VERSION ""

NS_ :

BS_:

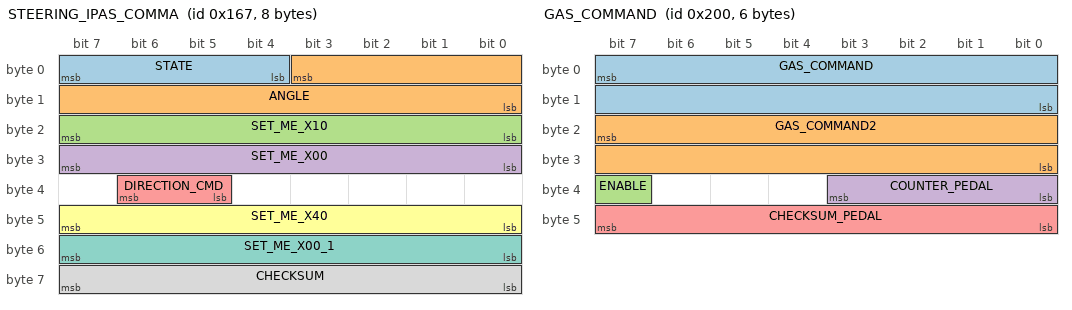
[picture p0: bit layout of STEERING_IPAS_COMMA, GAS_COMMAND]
BO_ 359 STEERING_IPAS_COMMA: 8 IPAS
 SG_ STATE : 7|4@0+ (1,0) [0|15] "" XXX
 SG_ ANGLE : 3|12@0- (1.5,0) [-510|510] "deg" XXX
 SG_ SET_ME_X10 : 23|8@0+ (1,0) [0|255] "" XXX
 SG_ SET_ME_X00 : 31|8@0+ (1,0) [0|255] "" XXX
 SG_ DIRECTION_CMD : 38|2@0+ (1,0) [0|3] "" XXX
 SG_ SET_ME_X40 : 47|8@0+ (1,0) [0|255] "" XXX
 SG_ SET_ME_X00_1 : 55|8@0+ (1,0) [0|255] "" XXX
 SG_ CHECKSUM : 63|8@0+ (1,0) [0|255] "" XXX

BO_ 512 GAS_COMMAND: 6 EON
 SG_ GAS_COMMAND : 7|16@0+ (0.159375,-75.555) [0|1] "" INTERCEPTOR
 SG_ GAS_COMMAND2 : 23|16@0+ (0.159375,-151.111) [0|1] "" INTERCEPTOR
 SG_ ENABLE : 39|1@0+ (1,0) [0|1] "" INTERCEPTOR
 SG_ COUNTER_PEDAL : 35|4@0+ (1,0) [0|15] "" INTERCEPTOR
 SG_ CHECKSUM_PEDAL : 47|8@0+ (1,0) [0|255] "" INTERCEPTOR

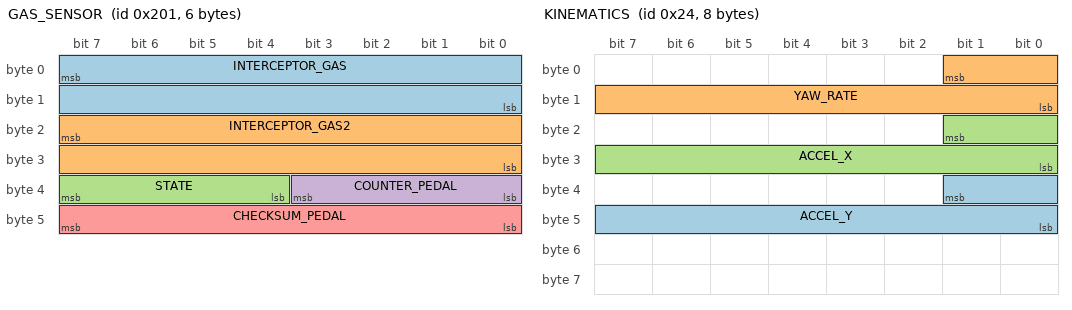
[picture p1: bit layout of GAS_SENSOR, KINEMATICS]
BO_ 513 GAS_SENSOR: 6 INTERCEPTOR
 SG_ INTERCEPTOR_GAS : 7|16@0+ (1,0) [0|1] "" EON
 SG_ INTERCEPTOR_GAS2 : 23|16@0+ (1,0) [0|1] "" EON
 SG_ STATE : 39|4@0+ (1,0) [0|15] "" EON
 SG_ COUNTER_PEDAL : 35|4@0+ (1,0) [0|15] "" EON
 SG_ CHECKSUM_PEDAL : 47|8@0+ (1,0) [0|255] "" EON

BO_ 35 SECONDARY_STEER_ANGLE: 8 XXX
 SG_ ZORRO_STEER : 7|24@0- (0.004901594652,0) [-500|500] "" XXX

BO_ 767 SDSU: 8 XXX
 SG_ FD_BUTTON : 7|1@0+ (1,0) [0|1] "" XXX

BO_ 36 KINEMATICS: 8 XXX
 SG_ ACCEL_Y : 33|10@0+ (0.03589,-18.375) [0|65535] "m/s^2" XXX
 SG_ YAW_RATE : 1|10@0+ (0.244,-125) [0|65535] "deg/s" XXX
 SG_ ACCEL_X : 17|10@0+ (0.03589,-18.375) [0|65535] "m/s^2" XXX

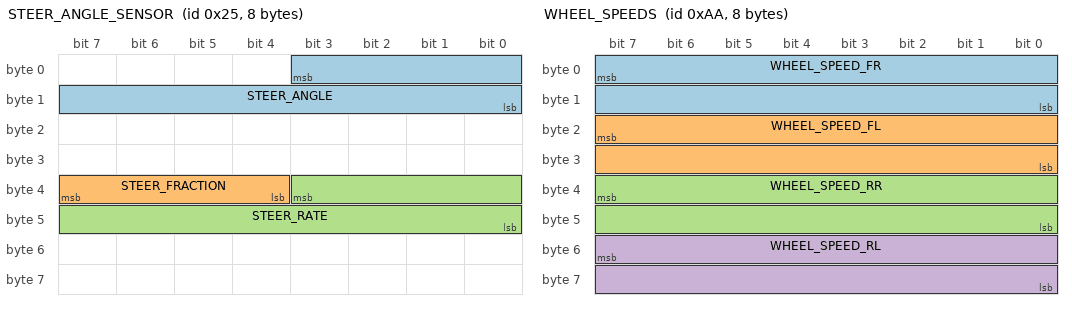
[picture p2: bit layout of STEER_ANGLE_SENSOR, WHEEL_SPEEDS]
BO_ 37 STEER_ANGLE_SENSOR: 8 XXX
 SG_ STEER_ANGLE : 3|12@0- (1.5,0) [-500|500] "deg" XXX
 SG_ STEER_FRACTION : 39|4@0- (0.1,0) [-0.7|0.7] "deg" XXX
 SG_ STEER_RATE : 35|12@0- (1,0) [-2000|2000] "deg/s" XXX

BO_ 166 BRAKE: 8 XXX
 SG_ BRAKE_AMOUNT : 7|8@0+ (1,0) [0|255] "" XXX
 SG_ BRAKE_PEDAL : 23|8@0+ (1,0) [0|255] "" XXX

BO_ 170 WHEEL_SPEEDS: 8 XXX
 SG_ WHEEL_SPEED_FR : 7|16@0+ (0.01,-67.67) [0|250] "km/h" XXX
 SG_ WHEEL_SPEED_FL : 23|16@0+ (0.01,-67.67) [0|250] "km/h" XXX
 SG_ WHEEL_SPEED_RR : 39|16@0+ (0.01,-67.67) [0|250] "km/h" XXX
 SG_ WHEEL_SPEED_RL : 55|16@0+ (0.01,-67.67) [0|250] "km/h" XXX

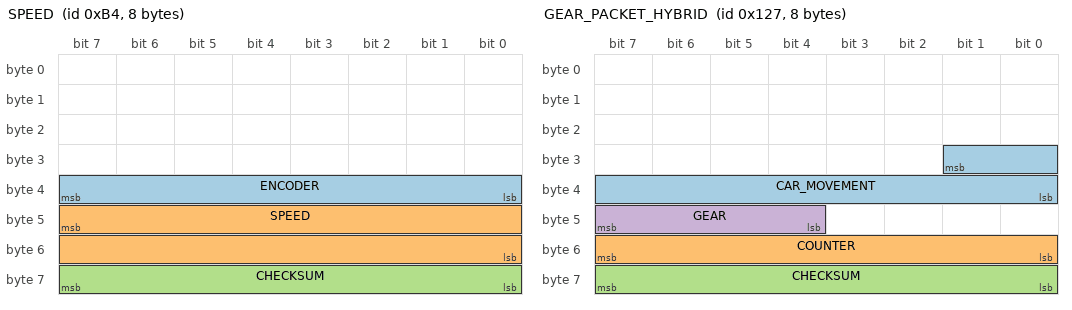
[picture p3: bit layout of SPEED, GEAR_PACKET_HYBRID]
BO_ 180 SPEED: 8 XXX
 SG_ ENCODER : 39|8@0+ (1,0) [0|255] "" XXX
 SG_ SPEED : 47|16@0+ (0.01,0) [0|250] "km/h" XXX
 SG_ CHECKSUM : 63|8@0+ (1,0) [0|255] "" XXX

BO_ 295 GEAR_PACKET_HYBRID: 8 XXX
 SG_ CAR_MOVEMENT : 25|10@0- (1,0) [0|255] "" XXX
 SG_ COUNTER : 55|8@0+ (1,0) [0|255] "" XXX
 SG_ CHECKSUM : 63|8@0+ (1,0) [0|255] "" XXX
 SG_ GEAR : 47|4@0+ (1,0) [0|15] "" XXX

BO_ 353 DSU_SPEED: 7 XXX
 SG_ FORWARD_SPEED : 15|16@0- (0.00390625,-30) [0|255] "km/h" XXX

BO_ 452 ENGINE_RPM: 8 CGW
 SG_ RPM : 7|16@0- (0.78125,0) [0|0] "rpm" SCS

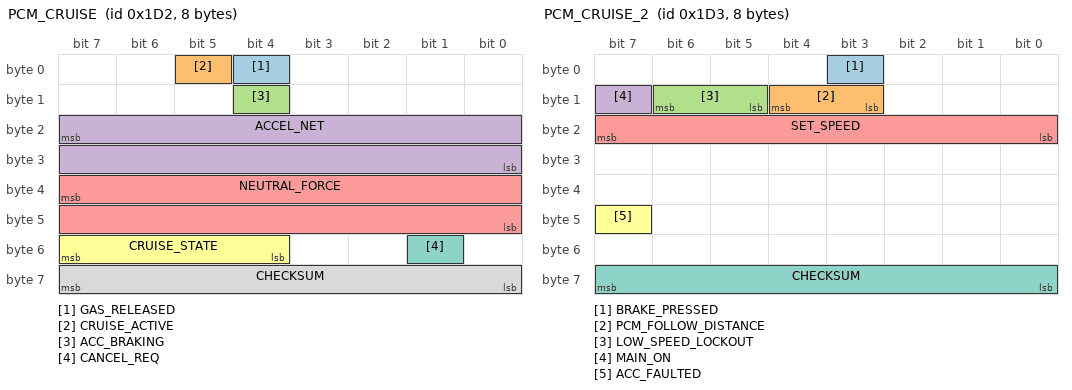
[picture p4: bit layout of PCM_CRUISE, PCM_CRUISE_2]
BO_ 466 PCM_CRUISE: 8 XXX
 SG_ GAS_RELEASED : 4|1@0+ (1,0) [0|1] "" XXX
 SG_ CRUISE_ACTIVE : 5|1@0+ (1,0) [0|1] "" XXX
 SG_ ACC_BRAKING : 12|1@0+ (1,0) [0|1] "" XXX
 SG_ ACCEL_NET : 23|16@0- (0.0009765625,0) [-20|20] "m/s^2" XXX
 SG_ NEUTRAL_FORCE : 39|16@0- (2,0) [-65536|65534] "N" XXX
 SG_ CRUISE_STATE : 55|4@0+ (1,0) [0|15] "" XXX
 SG_ CANCEL_REQ : 49|1@1+ (1,0) [0|1] "" XXX
 SG_ CHECKSUM : 63|8@0+ (1,0) [0|255] "" XXX

BO_ 467 PCM_CRUISE_2: 8 XXX
 SG_ BRAKE_PRESSED : 3|1@0+ (1,0) [0|1] "" XXX
 SG_ PCM_FOLLOW_DISTANCE : 12|2@0+ (1,0) [0|3] "" XXX
 SG_ LOW_SPEED_LOCKOUT : 14|2@0+ (1,0) [0|3] "" XXX
 SG_ MAIN_ON : 15|1@0+ (1,0) [0|1] "" XXX
 SG_ SET_SPEED : 23|8@0+ (1,0) [0|255] "km/h" XXX
 SG_ ACC_FAULTED : 47|1@0+ (1,0) [0|1] "" XXX
 SG_ CHECKSUM : 63|8@0+ (1,0) [0|255] "" XXX

BO_ 552 ACCELEROMETER: 8 XXX
 SG_ ACCEL_Z : 22|15@0- (1,0) [0|32767] "m/s^2" XXX
 SG_ ACCEL_X : 6|15@0- (0.001,0) [-20|20] "m/s^2" XXX

BO_ 560 BRAKE_2: 7 XXX
 SG_ BRAKE_PRESSED : 26|1@0+ (1,0) [0|1] "" XXX

BO_ 581 GAS_PEDAL_HYBRID: 8 XXX
 SG_ GAS_PEDAL : 23|8@0+ (0.005,0) [0|1] "" XXX

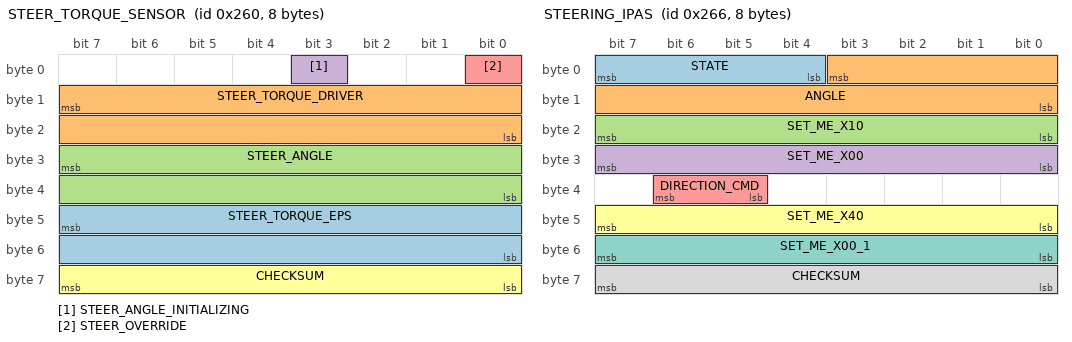
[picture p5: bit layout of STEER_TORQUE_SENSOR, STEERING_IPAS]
BO_ 608 STEER_TORQUE_SENSOR: 8 XXX
 SG_ STEER_TORQUE_EPS : 47|16@0- (1,0) [-32768|32767] "" XXX
 SG_ STEER_TORQUE_DRIVER : 15|16@0- (1,0) [-32768|32767] "" XXX
 SG_ STEER_ANGLE : 31|16@0- (0.0573,0) [-500|500] "" XXX
 SG_ STEER_ANGLE_INITIALIZING : 3|1@0+ (1,0) [0|1] "" XXX
 SG_ STEER_OVERRIDE : 0|1@0+ (1,0) [0|1] "" XXX
 SG_ CHECKSUM : 63|8@0+ (1,0) [0|255] "" XXX

BO_ 614 STEERING_IPAS: 8 IPAS
 SG_ STATE : 7|4@0+ (1,0) [0|15] "" XXX
 SG_ ANGLE : 3|12@0- (1.5,0) [-510|510] "deg" XXX
 SG_ SET_ME_X10 : 23|8@0+ (1,0) [0|255] "" XXX
 SG_ SET_ME_X00 : 31|8@0+ (1,0) [0|255] "" XXX
 SG_ DIRECTION_CMD : 38|2@0+ (1,0) [0|3] "" XXX
 SG_ SET_ME_X40 : 47|8@0+ (1,0) [0|255] "" XXX
 SG_ SET_ME_X00_1 : 55|8@0+ (1,0) [0|255] "" XXX
 SG_ CHECKSUM : 63|8@0+ (1,0) [0|255] "" XXX

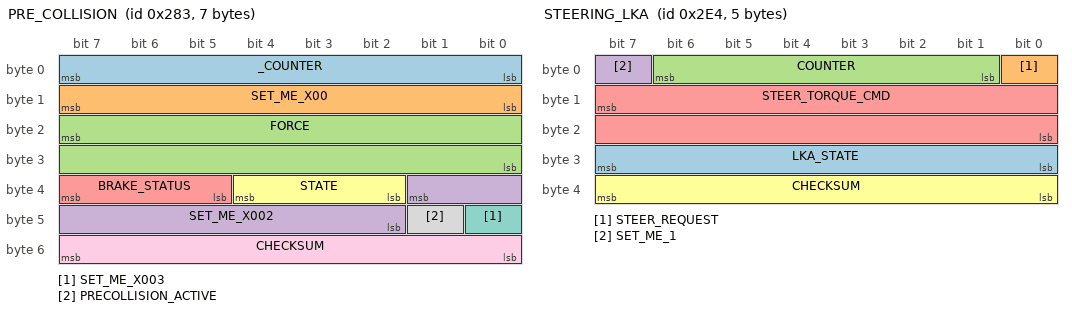
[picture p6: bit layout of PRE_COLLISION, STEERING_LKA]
BO_ 643 PRE_COLLISION: 7 DSU
 SG_ _COUNTER : 7|8@0+ (1,0) [0|255] "" XXX
 SG_ SET_ME_X00 : 15|8@0+ (1,0) [0|255] "" XXX
 SG_ FORCE : 23|16@0- (2,0) [0|255] "N" XXX
 SG_ SET_ME_X002 : 33|8@0+ (1,0) [0|3] "" XXX
 SG_ BRAKE_STATUS : 39|3@0+ (1,0) [0|255] "" XXX
 SG_ STATE : 36|3@0+ (1,0) [0|255] "" XXX
 SG_ SET_ME_X003 : 40|1@0+ (1,0) [0|1] "" XXX
 SG_ PRECOLLISION_ACTIVE : 41|1@0+ (1,0) [0|255] "" XXX
 SG_ CHECKSUM : 55|8@0+ (1,0) [0|255] "" XXX

BO_ 705 GAS_PEDAL: 8 XXX
 SG_ GAS_RELEASED : 3|1@0+ (1,0) [0|1] "" XXX
 SG_ GAS_PEDAL : 55|8@0+ (0.005,0) [0|1] "" XXX

BO_ 740 STEERING_LKA: 5 XXX
 SG_ LKA_STATE : 31|8@0+ (1,0) [0|255] "" XXX
 SG_ STEER_REQUEST : 0|1@0+ (1,0) [0|1] "" XXX
 SG_ COUNTER : 6|6@0+ (1,0) [0|63] "" XXX
 SG_ SET_ME_1 : 7|1@0+ (1,0) [0|1] "" XXX
 SG_ STEER_TORQUE_CMD : 15|16@0- (1,0) [0|65535] "" XXX
 SG_ CHECKSUM : 39|8@0+ (1,0) [0|255] "" XXX

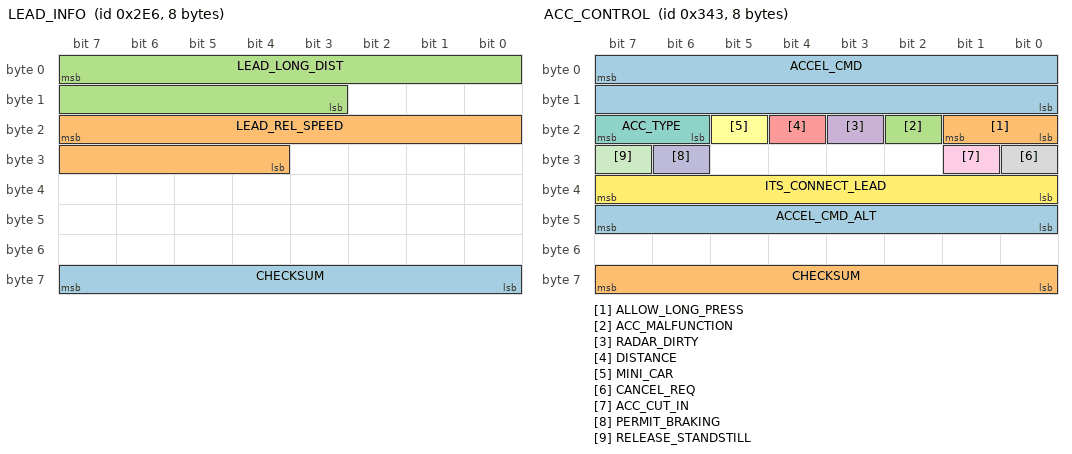
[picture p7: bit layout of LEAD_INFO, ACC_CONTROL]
BO_ 742 LEAD_INFO: 8 DSU
 SG_ CHECKSUM : 63|8@0+ (1,0) [0|255] "" HCU
 SG_ LEAD_REL_SPEED : 23|12@0- (0.025,0) [-100|100] "m/s" HCU
 SG_ LEAD_LONG_DIST : 7|13@0+ (0.05,0) [0|300] "m" HCU

BO_ 835 ACC_CONTROL: 8 DSU
 SG_ ACCEL_CMD : 7|16@0- (0.001,0) [-20|20] "m/s^2" HCU
 SG_ ALLOW_LONG_PRESS : 17|2@0+ (1,0) [0|2] "" XXX
 SG_ ACC_MALFUNCTION : 18|1@0+ (1,0) [0|0] "" XXX
 SG_ RADAR_DIRTY : 19|1@0+ (1,0) [0|1] "" XXX
 SG_ DISTANCE : 20|1@0+ (1,0) [0|1] "" XXX
 SG_ MINI_CAR : 21|1@0+ (1,0) [0|1] "" XXX
 SG_ ACC_TYPE : 23|2@0+ (1,0) [0|3] "" HCU
 SG_ CANCEL_REQ : 24|1@0+ (1,0) [0|1] "" HCU
 SG_ ACC_CUT_IN : 25|1@0+ (1,0) [0|1] "" XXX
 SG_ PERMIT_BRAKING : 30|1@0+ (1,0) [0|1] "" HCU
 SG_ RELEASE_STANDSTILL : 31|1@0+ (1,0) [0|1] "" HCU
 SG_ ITS_CONNECT_LEAD : 39|8@0+ (1,0) [0|1] "" Vector__XXX
 SG_ ACCEL_CMD_ALT : 47|8@0- (0.05,0) [0|0] "m/s^2" XXX
 SG_ CHECKSUM : 63|8@0+ (1,0) [0|255] "" XXX

BO_ 836 PRE_COLLISION_2: 8 DSU
 SG_ CHECKSUM : 63|8@0+ (1,0) [0|0] "" XXX

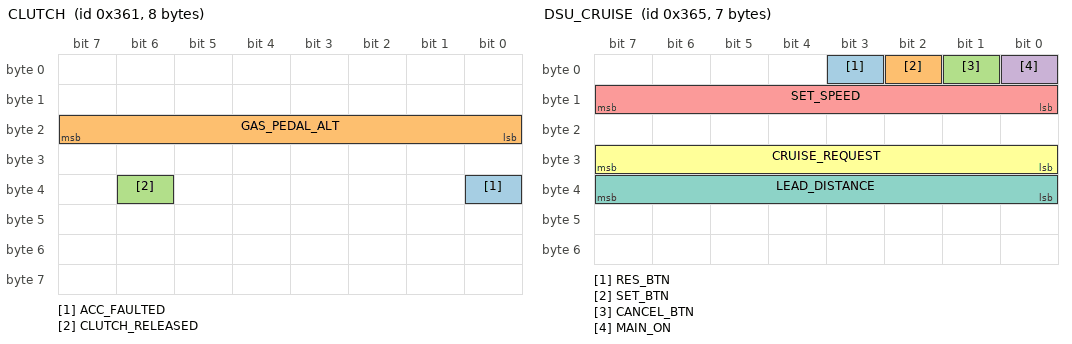
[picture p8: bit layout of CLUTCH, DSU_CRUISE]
BO_ 865 CLUTCH: 8 XXX
 SG_ ACC_FAULTED : 32|1@0+ (1,0) [0|1] "" XXX
 SG_ GAS_PEDAL_ALT : 23|8@0+ (0.005,0) [0|1] "" XXX
 SG_ CLUTCH_RELEASED : 38|1@0+ (1,0) [0|1] "" XXX

BO_ 869 DSU_CRUISE : 7 DSU
 SG_ RES_BTN : 3|1@0+ (1,0) [0|0] "" XXX
 SG_ SET_BTN : 2|1@0+ (1,0) [0|0] "" XXX
 SG_ CANCEL_BTN : 1|1@0+ (1,0) [0|0] "" XXX
 SG_ MAIN_ON : 0|1@0+ (1,0) [0|0] "" XXX
 SG_ SET_SPEED : 15|8@0+ (1,0) [0|0] "km/h" XXX
 SG_ CRUISE_REQUEST : 31|8@0+ (100,-12800) [0|0] "N" XXX
 SG_ LEAD_DISTANCE : 39|8@0+ (1,0) [0|0] "m" XXX

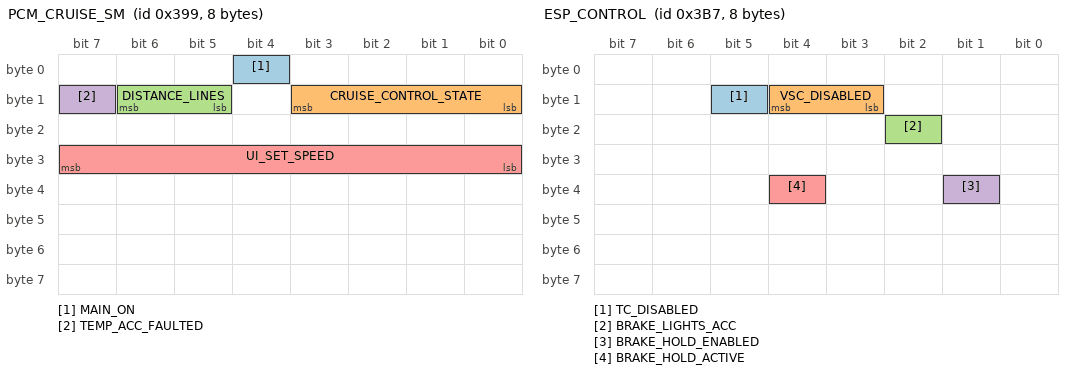
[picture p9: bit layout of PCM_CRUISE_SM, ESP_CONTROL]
BO_ 921 PCM_CRUISE_SM: 8 XXX
 SG_ MAIN_ON : 4|1@0+ (1,0) [0|1] "" XXX
 SG_ CRUISE_CONTROL_STATE : 11|4@0+ (1,0) [0|15] "" XXX
 SG_ DISTANCE_LINES : 14|2@0+ (1,0) [0|3] "" XXX
 SG_ TEMP_ACC_FAULTED : 15|1@0+ (1,0) [0|1] "" XXX
 SG_ UI_SET_SPEED : 31|8@0+ (1,0) [0|255] "" XXX

BO_ 951 ESP_CONTROL: 8 ESP
 SG_ TC_DISABLED : 13|1@0+ (1,0) [0|1] "" XXX
 SG_ VSC_DISABLED : 12|2@0+ (1,0) [0|1] "" XXX
 SG_ BRAKE_LIGHTS_ACC : 18|1@0+ (1,0) [0|1] "" XXX
 SG_ BRAKE_HOLD_ENABLED : 33|1@1+ (1,0) [0|1] "" XXX
 SG_ BRAKE_HOLD_ACTIVE : 36|1@0+ (1,0) [0|1] "" XXX

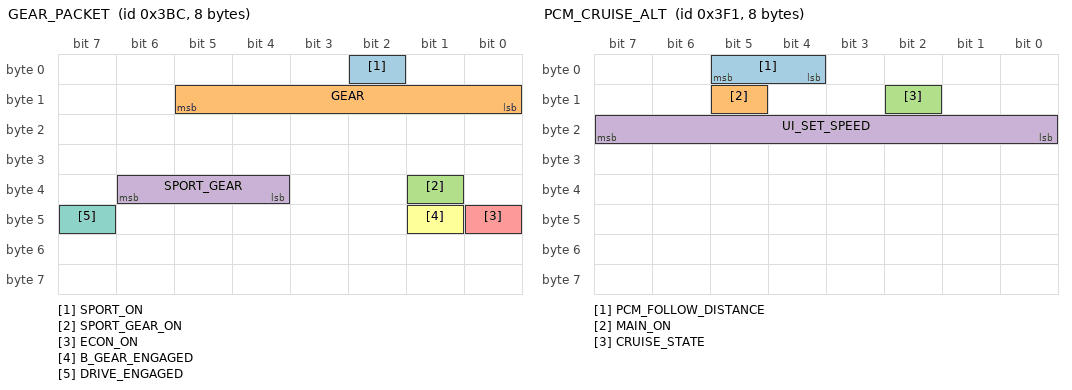
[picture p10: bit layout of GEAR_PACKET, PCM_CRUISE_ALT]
BO_ 956 GEAR_PACKET: 8 XXX
 SG_ SPORT_ON : 2|1@0+ (1,0) [0|1] "" XXX
 SG_ GEAR : 13|6@0+ (1,0) [0|63] "" XXX
 SG_ SPORT_GEAR_ON : 33|1@0+ (1,0) [0|1] "" XXX
 SG_ SPORT_GEAR : 38|3@0+ (1,0) [0|7] "" XXX
 SG_ ECON_ON : 40|1@0+ (1,0) [0|1] "" XXX
 SG_ B_GEAR_ENGAGED : 41|1@0+ (1,0) [0|1] "" XXX
 SG_ DRIVE_ENGAGED : 47|1@0+ (1,0) [0|1] "" XXX

BO_ 1005 REVERSE_CAMERA_STATE: 2 BGM
 SG_ REVERSE_CAMERA_GUIDELINES : 9|2@0+ (1,0) [1|3] "" XXX

BO_ 1009 PCM_CRUISE_ALT: 8 XXX
 SG_ PCM_FOLLOW_DISTANCE : 4|2@1+ (1,0) [0|3] "" XXX
 SG_ MAIN_ON : 13|1@0+ (1,0) [0|3] "" XXX
 SG_ CRUISE_STATE : 10|1@0+ (1,0) [0|1] "" XXX
 SG_ UI_SET_SPEED : 23|8@0+ (1,0) [0|255] "mph" XXX

BO_ 1020 SOLAR_SENSOR: 8 XXX
 SG_ LUX_SENSOR : 55|13@0+ (1,0) [0|0] "" XXX

BO_ 1041 PCS_HUD: 8 DSU
 SG_ PCS_INDICATOR : 7|2@0+ (1,0) [0|3] "" XXX
 SG_ FCW : 4|1@0+ (1,0) [0|1] "" XXX
 SG_ SET_ME_X20 : 15|8@0+ (1,0) [0|1] "" XXX
 SG_ PCS_DUST : 34|1@0+ (1,0) [0|0] "" XXX
 SG_ PCS_TEMP : 35|1@0+ (1,0) [0|0] "" XXX
 SG_ PCS_DUST2 : 41|1@0+ (1,0) [0|0] "" XXX
 SG_ PCS_TEMP2 : 42|1@0+ (1,0) [0|0] "" XXX
 SG_ SET_ME_X10 : 39|8@0+ (1,0) [0|1] "" XXX
 SG_ PCS_OFF : 40|1@0+ (1,0) [0|0] "" XXX
 SG_ FRD_ADJ : 53|3@0+ (1,0) [0|0] "" XXX
 SG_ PCS_SENSITIVITY : 55|8@0+ (1,0) [0|1] "" XXX

BO_ 1042 LKAS_HUD: 8 DSU
 SG_ BARRIERS : 1|2@0+ (1,0) [0|3] "" XXX
 SG_ RIGHT_LINE : 3|2@0+ (1,0) [0|3] "" XXX
 SG_ LEFT_LINE : 5|2@0+ (1,0) [0|3] "" XXX
 SG_ LKAS_STATUS : 7|2@0+ (1,0) [0|3] "" XXX
 SG_ LDA_ALERT : 9|2@0+ (1,0) [0|3] "" XXX
 SG_ LDW_EXIST : 10|1@0+ (1,0) [0|1] "" XXX
 SG_ TWO_BEEPS : 12|1@0+ (1,0) [0|1] "" XXX
 SG_ ADJUSTING_CAMERA : 13|1@0+ (1,0) [0|1] "" XXX
 SG_ LDA_UNAVAILABLE_QUIET : 14|1@0+ (1,0) [0|1] "" XXX
 SG_ LDA_MALFUNCTION : 15|1@0+ (1,0) [0|1] "" XXX
 SG_ LDA_UNAVAILABLE : 16|1@0+ (1,0) [0|1] "" XXX
 SG_ LDA_SENSITIVITY : 18|2@0+ (1,0) [0|3] "" XXX
 SG_ LDA_SA_TOGGLE : 20|2@0+ (1,0) [0|3] "" XXX
 SG_ LDA_MESSAGES : 23|3@0+ (1,0) [0|1] "" XXX
 SG_ LDA_ON_MESSAGE : 31|2@0+ (1,0) [0|3] "" XXX
 SG_ REPEATED_BEEPS : 32|1@0+ (1,0) [0|1] "" XXX
 SG_ LANE_SWAY_TOGGLE : 43|1@0+ (1,0) [0|1] "" XXX
 SG_ LANE_SWAY_SENSITIVITY : 45|2@0+ (1,0) [0|3] "" XXX
 SG_ TAKE_CONTROL : 46|1@0+ (1,0) [0|1] "" XXX
 SG_ LDA_FRONT_CAMERA_BLOCKED : 47|1@0+ (1,0) [0|1] "" XXX
 SG_ LANE_SWAY_BUZZER : 50|2@0+ (1,0) [0|0] "" XXX
 SG_ LANE_SWAY_FLD : 53|3@0+ (1,0) [0|7] "" XXX
 SG_ LANE_SWAY_WARNING : 55|2@0+ (1,0) [0|3] "" XXX
 SG_ SET_ME_X01 : 42|1@0+ (1,0) [0|1] "" XXX
 SG_ SET_ME_X02 : 63|8@0+ (1,0) [0|1] "" XXX

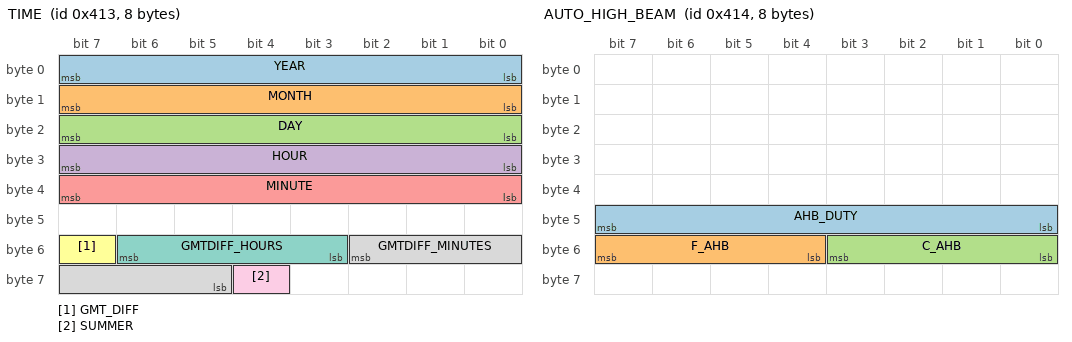
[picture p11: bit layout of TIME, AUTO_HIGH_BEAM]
BO_ 1043 TIME : 8 CGW
 SG_ YEAR : 7|8@0+ (1,0) [0|0] "year" XXX
 SG_ MONTH : 15|8@0+ (1,0) [0|0] "month" XXX
 SG_ DAY : 23|8@0+ (1,0) [0|0] "day" XXX
 SG_ HOUR : 31|8@0+ (1,0) [0|0] "hour" XXX
 SG_ MINUTE : 39|8@0+ (1,0) [0|0] "minute" XXX
 SG_ GMT_DIFF : 55|1@0+ (1,0) [0|0] "" XXX
 SG_ GMTDIFF_HOURS : 54|4@0+ (1,0) [0|0] "hours" XXX
 SG_ GMTDIFF_MINUTES : 50|6@0+ (1,0) [0|0] "minutes" XXX
 SG_ SUMMER : 60|1@0+ (1,0) [0|0] "" XXX

BO_ 1044 AUTO_HIGH_BEAM: 8 FCM
 SG_ AHB_DUTY : 47|8@0+ (0.5,0) [0|0] "%" Vector__XXX
 SG_ F_AHB : 55|4@0+ (1,0) [0|0] "" Vector__XXX
 SG_ C_AHB : 51|4@0+ (1,0) [0|0] "" Vector__XXX

BO_ 1083 AUTOPARK_STATUS: 8 IPAS
 SG_ STATE : 7|4@0+ (1,0) [0|15] "" XXX

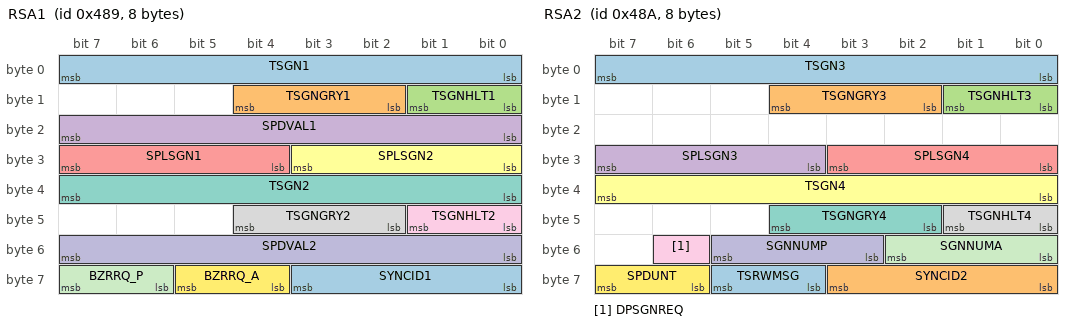
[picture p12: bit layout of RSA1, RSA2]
BO_ 1161 RSA1: 8 FCM
 SG_ TSGN1 : 7|8@0+ (1,0) [0|0] "" XXX
 SG_ TSGNGRY1 : 12|3@0+ (1,0) [0|0] "" XXX
 SG_ TSGNHLT1 : 9|2@0+ (1,0) [0|0] "" XXX
 SG_ SPDVAL1 : 23|8@0+ (1,0) [0|0] "km/h" XXX
 SG_ SPLSGN1 : 31|4@0+ (1,0) [0|0] "" XXX
 SG_ SPLSGN2 : 27|4@0+ (1,0) [0|0] "" XXX
 SG_ TSGN2 : 39|8@0+ (1,0) [0|0] "" XXX
 SG_ TSGNGRY2 : 44|3@0+ (1,0) [0|0] "" XXX
 SG_ TSGNHLT2 : 41|2@0+ (1,0) [0|0] "" XXX
 SG_ SPDVAL2 : 55|8@0+ (1,0) [0|0] "" XXX
 SG_ BZRRQ_P : 63|2@0+ (1,0) [0|0] "" XXX
 SG_ BZRRQ_A : 61|2@0+ (1,0) [0|0] "" XXX
 SG_ SYNCID1 : 59|4@0+ (1,0) [0|0] "" XXX

BO_ 1162 RSA2: 8 FCM
 SG_ TSGN3 : 7|8@0+ (1,0) [0|0] "" XXX
 SG_ TSGNGRY3 : 12|3@0+ (1,0) [0|0] "" XXX
 SG_ TSGNHLT3 : 9|2@0+ (1,0) [0|0] "" XXX
 SG_ SPLSGN3 : 31|4@0+ (1,0) [0|0] "" XXX
 SG_ SPLSGN4 : 27|4@0+ (1,0) [0|0] "" XXX
 SG_ TSGN4 : 39|8@0+ (1,0) [0|0] "" XXX
 SG_ TSGNGRY4 : 44|3@0+ (1,0) [0|0] "" XXX
 SG_ TSGNHLT4 : 41|2@0+ (1,0) [0|0] "" XXX
 SG_ DPSGNREQ : 54|1@0+ (1,0) [0|0] "" XXX
 SG_ SGNNUMP : 53|3@0+ (1,0) [0|0] "" XXX
 SG_ SGNNUMA : 50|3@0+ (1,0) [0|0] "" XXX
 SG_ SPDUNT : 63|2@0+ (1,0) [0|0] "" XXX
 SG_ TSRWMSG : 61|2@0+ (1,0) [0|0] "" XXX
 SG_ SYNCID2 : 59|4@0+ (1,0) [0|0] "" XXX

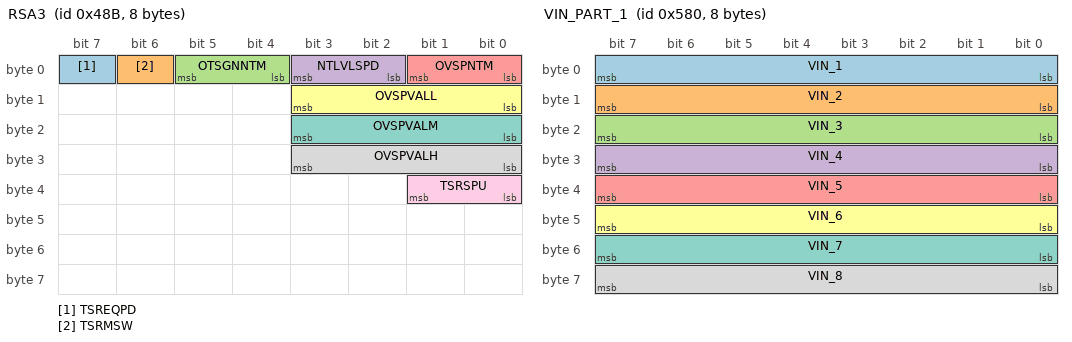
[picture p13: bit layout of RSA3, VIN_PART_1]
BO_ 1163 RSA3: 8 FCM
 SG_ TSREQPD : 7|1@0+ (1,0) [0|0] "" XXX
 SG_ TSRMSW : 6|1@0+ (1,0) [0|0] "" XXX
 SG_ OTSGNNTM : 5|2@0+ (1,0) [0|0] "" XXX
 SG_ NTLVLSPD : 3|2@0+ (1,0) [0|0] "" XXX
 SG_ OVSPNTM : 1|2@0+ (1,0) [0|0] "" XXX
 SG_ OVSPVALL : 11|4@0+ (1,-5) [0|0] "" XXX
 SG_ OVSPVALM : 19|4@0+ (1,-5) [0|0] "" XXX
 SG_ OVSPVALH : 27|4@0+ (1,-5) [0|0] "" XXX
 SG_ TSRSPU : 33|2@0+ (1,0) [0|0] "" XXX

BO_ 1408 VIN_PART_1: 8 CGW
 SG_ VIN_1 : 7|8@0+ (1,0) [0|0] "" XXX
 SG_ VIN_2 : 15|8@0+ (1,0) [0|0] "" XXX
 SG_ VIN_3 : 23|8@0+ (1,0) [0|0] "" XXX
 SG_ VIN_4 : 31|8@0+ (1,0) [0|0] "" XXX
 SG_ VIN_5 : 39|8@0+ (1,0) [0|0] "" XXX
 SG_ VIN_6 : 47|8@0+ (1,0) [0|0] "" XXX
 SG_ VIN_7 : 55|8@0+ (1,0) [0|0] "" XXX
 SG_ VIN_8 : 63|8@0+ (1,0) [0|0] "" XXX

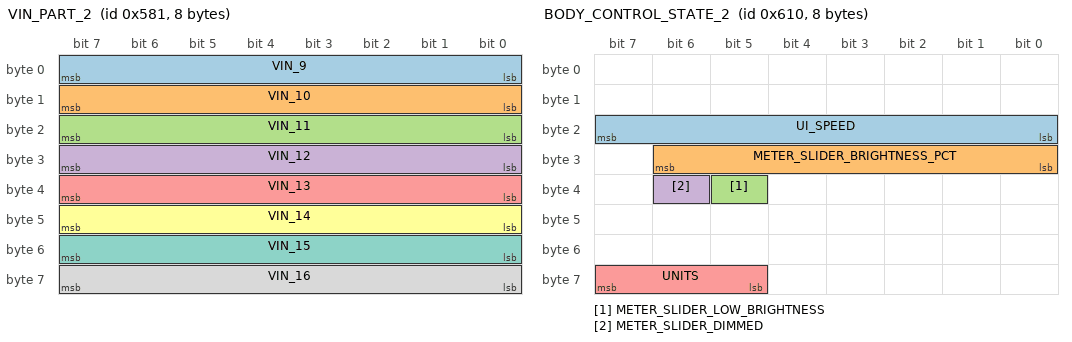
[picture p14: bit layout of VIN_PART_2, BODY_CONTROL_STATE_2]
BO_ 1409 VIN_PART_2: 8 CGW
 SG_ VIN_9 : 7|8@0+ (1,0) [0|0] "" XXX
 SG_ VIN_10 : 15|8@0+ (1,0) [0|0] "" XXX
 SG_ VIN_11 : 23|8@0+ (1,0) [0|0] "" XXX
 SG_ VIN_12 : 31|8@0+ (1,0) [0|0] "" XXX
 SG_ VIN_13 : 39|8@0+ (1,0) [0|0] "" XXX
 SG_ VIN_14 : 47|8@0+ (1,0) [0|0] "" XXX
 SG_ VIN_15 : 55|8@0+ (1,0) [0|0] "" XXX
 SG_ VIN_16 : 63|8@0+ (1,0) [0|0] "" XXX

BO_ 1410 VIN_PART_3: 8 CGW
 SG_ VIN_17 : 7|8@0+ (1,0) [0|0] "" XXX

BO_ 1552 BODY_CONTROL_STATE_2: 8 XXX
 SG_ UI_SPEED : 23|8@0+ (1,0) [0|255] "" XXX
 SG_ METER_SLIDER_BRIGHTNESS_PCT : 30|7@0+ (1,0) [12|100] "%" XXX
 SG_ METER_SLIDER_LOW_BRIGHTNESS : 37|1@0+ (1,0) [0|1] "" XXX
 SG_ METER_SLIDER_DIMMED : 38|1@0+ (1,0) [0|1] "" XXX
 SG_ UNITS : 63|3@0+ (1,0) [1|4] "" XXX

BO_ 1553 UI_SETTING: 8 XXX
 SG_ UNITS : 26|2@0+ (1,0) [0|3] "" XXX
 SG_ ODOMETER : 39|32@0+ (1,0) [0|1048575] "" XXX

BO_ 1556 BLINKERS_STATE: 8 XXX
 SG_ TURN_SIGNALS : 29|2@0+ (1,0) [0|3] "" XXX
 SG_ HAZARD_LIGHT : 27|1@0+ (1,0) [0|1] "" XXX

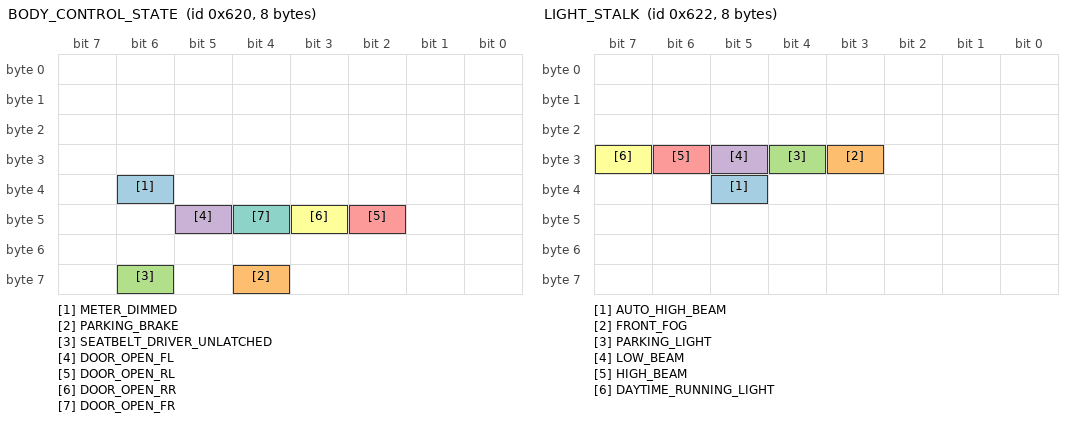
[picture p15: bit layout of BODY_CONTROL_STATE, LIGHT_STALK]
BO_ 1568 BODY_CONTROL_STATE: 8 XXX
 SG_ METER_DIMMED : 38|1@0+ (1,0) [0|1] "" XXX
 SG_ PARKING_BRAKE : 60|1@0+ (1,0) [0|1] "" XXX
 SG_ SEATBELT_DRIVER_UNLATCHED : 62|1@0+ (1,0) [0|1] "" XXX
 SG_ DOOR_OPEN_FL : 45|1@0+ (1,0) [0|1] "" XXX
 SG_ DOOR_OPEN_RL : 42|1@0+ (1,0) [0|1] "" XXX
 SG_ DOOR_OPEN_RR : 43|1@0+ (1,0) [0|1] "" XXX
 SG_ DOOR_OPEN_FR : 44|1@0+ (1,0) [0|1] "" XXX

BO_ 1570 LIGHT_STALK: 8 SCM
 SG_ AUTO_HIGH_BEAM : 37|1@0+ (1,0) [0|1] "" XXX
 SG_ FRONT_FOG : 27|1@0+ (1,0) [0|1] "" XXX
 SG_ PARKING_LIGHT : 28|1@0+ (1,0) [0|1] "" XXX
 SG_ LOW_BEAM : 29|1@0+ (1,0) [0|1] "" XXX
 SG_ HIGH_BEAM : 30|1@0+ (1,0) [0|1] "" XXX
 SG_ DAYTIME_RUNNING_LIGHT : 31|1@0+ (1,0) [0|1] "" XXX

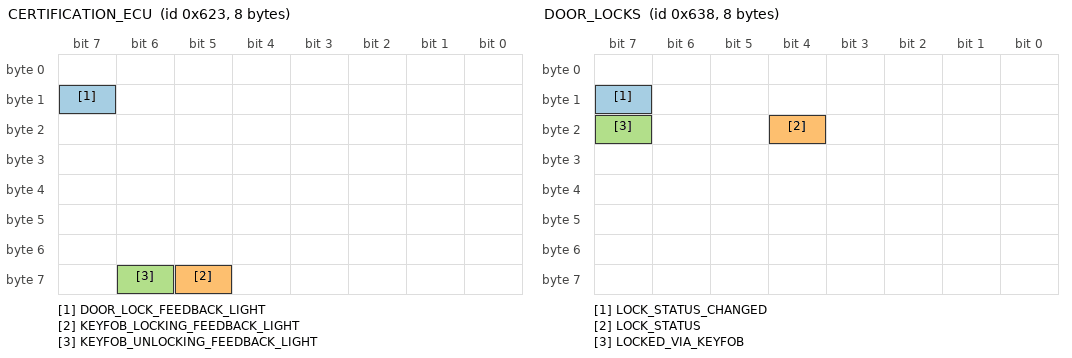
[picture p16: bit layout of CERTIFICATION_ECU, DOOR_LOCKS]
BO_ 1571 CERTIFICATION_ECU: 8 CGW
 SG_ DOOR_LOCK_FEEDBACK_LIGHT : 15|1@0+ (1,0) [0|0] "" XXX
 SG_ KEYFOB_LOCKING_FEEDBACK_LIGHT : 61|1@0+ (1,0) [0|0] "" XXX
 SG_ KEYFOB_UNLOCKING_FEEDBACK_LIGHT : 62|1@0+ (1,0) [0|0] "" XXX

BO_ 1592 DOOR_LOCKS: 8 XXX
 SG_ LOCK_STATUS_CHANGED : 15|1@0+ (1,0) [0|1] "" XXX
 SG_ LOCK_STATUS : 20|1@0+ (1,0) [0|1] "" XXX
 SG_ LOCKED_VIA_KEYFOB : 23|1@0+ (1,0) [0|1] "" XXX

BO_ 548 BRAKE_MODULE: 8 XXX
 SG_ BRAKE_PRESSURE : 43|12@0+ (1,0) [0|4047] "" XXX
 SG_ BRAKE_PRESSED : 5|1@0+ (1,0) [0|1] "" XXX

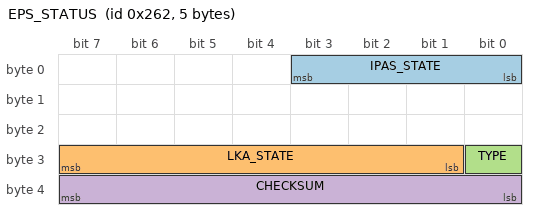
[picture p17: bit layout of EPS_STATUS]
BO_ 610 EPS_STATUS: 5 EPS
 SG_ IPAS_STATE : 3|4@0+ (1,0) [0|15] "" XXX
 SG_ LKA_STATE : 31|7@0+ (1,0) [0|127] "" XXX
 SG_ TYPE : 24|1@0+ (1,0) [0|1] "" XXX
 SG_ CHECKSUM : 39|8@0+ (1,0) [0|255] "" XXX

BO_ 1178 BRAKE_RELATED: 8 XXX
 SG_ BRAKE_PRESSED : 48|1@0+ (1,0) [0|1] "" XXX

BU_: K182_PACM K43_PSCM K17_EBCM NEO K124_ASCM

CM_ "New CAN FD network";
CM_ BU_ CMR_DSMC "Driver Status Monitor Camera";
CM_ BU_ IPMA_ADAS "Assist Driving Alert System";
CM_ BU_ PSCM "Passenger Front Climate Control Seat Module";
CM_ BU_ ABS_ESC "Anti-lock Brake / Traction Control Module";
CM_ BU_ TCCM "Transfer Case Control Module, 4x4 Control Module";
CM_ BU_ TCM_DSL "Transmission Control Module";
CM_ BU_ PCM "Powertrain Control Module";
CM_ BU_ ECM_Diesel "Diesel";
CM_ BU_ GWM "Gateway Module CGEA1.3(Star Architecture)";
CM_ BU_ TSTR "Diagnostic Tester";

CM_ SG_ 524 PrplWhlTotTqRqMxAwd_No_Cs "Signal not transmitted on gas variants.";
CM_ SG_ 524 PrplWhlTotTqRqMxAwd_No_Cnt "Signal not transmitted on gas variants.";
CM_ SG_ 1150 LocationServices_1 "Tx by HS3 APIM";
CM_ SG_ 542 LocationServices_3 "Tx by HS3 APIM";
CM_ SG_ 810 NtfyDrvTrgtDist_L_Rq "Object.SetTripRangeAlert_Rq This signal is meant to provide the customer settings for the target distance remote notification";
CM_ SG_ 810 NtfyDrvSocLvl1_Pc_Rq "Object.SetCustomerLevelAlert_Rq This signal is meant to provide the customer settings for the SOC remote notification.";
CM_ SG_ 810 PtRmtRprt_D_Stat "Object.RemoteDataReport_St";
CM_ SG_ 550 PtWakeupActv1_B_Rq "ECG Application signal";
CM_ SG_ 982 LatCtlPath_No_Cnt "Signal not transmitted on gas variants.";
CM_ SG_ 982 LatCtlPath_No_Cs "Signal not transmitted on gas variants.";
CM_ SG_ 1104 DrvEngageLevel_No_Cs "Signal not transmitted on gas variants.";
CM_ SG_ 1104 DrvEngageLevel_No_Cnt "Signal not transmitted on gas variants.";
CM_ SG_ 1085 ULoRgenTestMde_B_Stat "Signal not transmitted on HEV variants.";
CM_ SG_ 1085 PwSrcULoComm_B_Falt "Signal not transmitted on HEV variants.";
CM_ SG_ 1445 SOBDMC_AutoSarNMReserved4 "Signal not transmitted on gas and diesel variants.";
CM_ SG_ 1445 SOBDMC_AutoSarNMReserved3 "Signal not transmitted on gas and diesel variants.";
CM_ SG_ 1445 SOBDMC_AutoSarNMReserved2 "Signal not transmitted on gas and diesel variants.";
CM_ SG_ 1445 SOBDMC_AutoSarNMReserved1 "Signal not transmitted on gas and diesel variants.";
CM_ SG_ 1445 SOBDMC_AutoSarNMNodeId "Signal not transmitted on gas and diesel variants.";
CM_ SG_ 1445 SOBDMC_AutoSarNMControl "Signal not transmitted on gas and diesel variants.";
CM_ SG_ 1088 HvacPrecondMode2_D_Rq "Signal not transmitted on vehicles that do not have the Fuel operated heater feature.";
CM_ SG_ 1088 HvacPrecondBlwr2_D_Rq "Signal not transmitted on vehicles that do not have the Fuel operated heater feature.";
CM_ SG_ 786 ChrgStat_D_Dsply "Signal not transmitted by PCM_HEV";
CM_ SG_ 66 immoControlData_T2 "Not transmitted on all vehicle variants";
CM_ SG_ 66 immoControlCmd_T2 "Not transmitted on all vehicle variants";
CM_ SG_ 549 BeltminderAudioMute "Object.MyKey.BeltMinderAudioMute.St";
CM_ SG_ 549 Power_Up_Chime_Modules "Object.AlertMethod.IPC _Infotainment";
CM_ SG_ 549 Chime_Source "Object.AlertMethod.IPC_infotainment";
CM_ SG_ 611 AwdStat_D_RqDsply "Signal not transmitted on programs that do not have AWD.";
CM_ SG_ 611 AwdSrvcRqd_B_Rq "Signal not transmitted on programs that do not have AWD.";
CM_ SG_ 611 AwdLck_Tq_Rq "Signal not transmitted on programs that do not have AWD.";
CM_ SG_ 130 VehVTrlrAid_B_Rq "VR session start- req. limit blower speed no more than X volts.  CC restriction on time msg. will be honored.Double Event msg1st event to request limit, 2nd event to release limit, No msg. CC Grammar v7.xls";
CM_ SG_ 130 SteMdule_U_Meas "DCR 1745  to update Tx from GWM to EP100ms. SteMdule_I_Est & SteMdule_U_Meas are used by BMS system & filtered. The filter uses standard periodic rate & changing to EP would adversely affect the filter.(jweinfur)";
CM_ SG_ 130 SteMdule_I_Est "DCR 1745  to update Tx from GWM to EP100ms. SteMdule_I_Est & SteMdule_U_Meas are used by BMS system & filtered. The filter uses standard periodic rate & changing to EP would adversely affect the filter.(jweinfur)";
CM_ SG_ 126 StePinRelInit_An_Sns "SASM will transmit these signals on vehicles with SASM and without PSCM.  SCCM will not Tx this signal when SASM is present.";
CM_ SG_ 126 StePinAn_No_Cs "Signal not transmitted on gas variants.";
CM_ SG_ 1200 BrkTot_Tq_RqDrv "DCR 1836 to update Tx from GWM to EP100ms rejected due MPS6 TCM requires BrkTot_Tq_RqDrv at 20ms (bshu1).";
CM_ SG_ 1046 TCMode "Signal data set to 0x0 for ABS only vehicle option content";
CM_ SG_ 1046 DrvAntiLckLamp_D_Rq "update value table v8.34, not align w/GSDB, need etracker.  ABS & IPC implemented as updated.";
CM_ SG_ 1046 BpedMove_D_Actl "CCMGenSigTimeoutTime=1000";
CM_ SG_ 1044 StePinOffst_An_Est "SASM will transmit these signals on vehicles with SASM and without PSCM.  SCCM will not Tx this signal when SASM is present.";
CM_ SG_ 1044 StePinOffst_No_Cs "Signal not transmitted on gas variants.";
CM_ SG_ 534 BrkObdData_No_Actl "Signal not transmitted on gas, diesel and HEV.  Only supported on PHEV.";
CM_ SG_ 534 BrkObdIndex_No_Actl "Signal not transmitted on gas, diesel and HEV.  Only supported on PHEV.";
CM_ SG_ 534 WhlRotatRr_No_Cnt "DCR 1833 to update Tx from GWM to EP100ms. Wheel Count signals are used by complex algorithm to determine Tire Pressure by Location & can't change from 20msec. (jweinfur)";
CM_ SG_ 534 WhlRotatRl_No_Cnt "DCR 1833 to update Tx from GWM to EP100ms. Wheel Count signals are used by complex algorithm to determine Tire Pressure by Location & can't change from 20msec. (jweinfur)";
CM_ SG_ 534 WhlRotatFr_No_Cnt "DCR 1833 to update Tx from GWM to EP100ms. Wheel Count signals are used by complex algorithm to determine Tire Pressure by Location & can't change from 20msec. (jweinfur)";
CM_ SG_ 534 WhlRotatFl_No_Cnt "DCR 1833 to update Tx from GWM to EP100ms. Wheel Count signals are used by complex algorithm to determine Tire Pressure by Location & can't change from 20msec. (jweinfur)";
CM_ SG_ 531 VehLongOvrGnd_A_Est "CCMGenSigTimeoutTime=1000";
CM_ SG_ 1034 VehicleGGCCData "RCMGenSigTimeout=6000";
CM_ SG_ 1090 Mtr2State_D_ActlMntr "Signal Not transmitted on PCM_HEV variant";
CM_ SG_ 1090 Inv1Ain_I_ActlMntr "Signal Not transmitted on PCM_HEV variant";
CM_ SG_ 1090 VehElRnge_L_Dsply "Signal Not transmitted on HPCM variant";
CM_ SG_ 374 TrnRng_D_Rq "Powersplit HEVs with HF45, HPCM will Tx  this message.  For all other programs it will be Tx by PCM or TCM. ";
CM_ SG_ 374 TrnPrkSys_D_Actl "Powersplit HEVs with HF45, HPCM will Tx  this message.  For all other programs it will be Tx by PCM or TCM. ";
CM_ SG_ 374 GearLvr_D_ActlDrv "Powersplit HEVs with HF45, HPCM will Tx  this message.  For all other programs it will be Tx by PCM or TCM. ";
CM_ SG_ 374 GearPos_No_Cs "Powersplit HEVs with HF45, HPCM will Tx  this message.  For all other programs it will be Tx by PCM or TCM. ";
CM_ SG_ 374 GearPos_D_Trg "Powersplit HEVs with HF45, HPCM will Tx  this message.  For all other programs it will be Tx by PCM or TCM. ";
CM_ SG_ 374 GearPos_No_Cnt "Powersplit HEVs with HF45, HPCM will Tx  this message.  For all other programs it will be Tx by PCM or TCM. ";
CM_ SG_ 374 GearPos_D_Actl "Powersplit HEVs with HF45, HPCM will Tx  this message.  For all other programs it will be Tx by PCM or TCM. ";
CM_ SG_ 603 WhlDirAvgDrv_D_Actl "48V mHEV: ECM_HEVDSL is Tx,  MHT HEV: PCM_HEV is Tx,  Powersplit HEV: SOBDMC_HPCM is Tx";
CM_ SG_ 603 PrplTqMnRgen_B_Actl "48V mHEV: ECM_HEVDSL is Tx,  MHT HEV: PCM_HEV is Tx,  Powersplit HEV: SOBDMC_HPCM is Tx";
CM_ SG_ 603 BattTracCnnct_D_Rq "48V mHEV: ECM_HEVDSL is Tx,  MHT HEV: PCM_HEV is Tx,  Powersplit HEV: SOBDMC_HPCM is Tx";
CM_ SG_ 872 HybMdeStat_D_Dsply "Signal not transmitted by HPCM";
CM_ SG_ 560 SelDrvMdeSwtch_D_Stat3 "ECM_HEV,  PCM & PCM_HEV do not support or Transmit signal.";
CM_ SG_ 560 TrnSrvcRqd_B_Rq "Signal not transmitted on Diesel & HEV variants. MHT(U611/625) HPCM Rx 0x230 from PCM_HEV. Powersplit FWD HEVs(Cx482/3 430) HPCM Tx 0x230.";
CM_ SG_ 560 TrnShifActv_B_Actl "Signal not transmitted on HEV variants. MHT(U611/625) HPCM Rx 0x230 from PCM_HEV. Powersplit FWD HEVs(Cx482/3 430) HPCM Tx 0x230.";
CM_ SG_ 560 GboxOil_Te_Actl "Signal not transmitted on HEV variants. MHT(U611/625) HPCM Rx 0x230 from PCM_HEV. Powersplit FWD HEVs(Cx482/3 430) HPCM Tx 0x230.";
CM_ SG_ 369 SeatWorkSrfc_B_Falt "Signal Not transmitted by TCM_DSL";
CM_ SG_ 369 TrnIpcDsplyRng2_D_Actl "Signal not transmitted on HEV variants.";
CM_ SG_ 369 TrnIpcDsplyRng_D_Stat "Signal not transmitted on HEV variants.";
CM_ SG_ 92 TrnLvrV_D_Rq "Signal not transmitted on vehicles with PCM_HEV";
CM_ SG_ 92 TrnSbwSysHlth_D_Actl "Signal not transmitted on vehicles that do not have shift by wire.";
CM_ SG_ 92 TrnGearNtmAllow_B_Stat "Signal not transmitted on vehicles that do not have shift by wire.";
CM_ SG_ 92 TrnDtpCmd_D_Actl "Signal not transmitted on vehicles that do not have shift by wire.";
CM_ SG_ 92 TrnGearCmd_No_Cs "Signal not transmitted on vehicles that do not have shift by wire.";
CM_ SG_ 92 TrnValidGear_D_Cnfm "Signal not transmitted on vehicles that do not have shift by wire.";
CM_ SG_ 92 TrnNtrlTowCmd_D_Actl "Signal not transmitted on vehicles that do not have shift by wire.";
CM_ SG_ 92 TrnGearCmd_Pc_ActlPt "Signal not transmitted on vehicles that do not have shift by wire.";
CM_ SG_ 92 TrnGear_D_RqPt "Signal not transmitted on vehicles that do not have shift by wire.";
CM_ SG_ 92 TrnCmdState_B_Actl "Signal not transmitted on vehicles that do not have shift by wire.";
CM_ SG_ 92 TrnCmdCnt_B_Actl "Signal not transmitted on vehicles that do not have shift by wire.";
CM_ SG_ 92 PrkBrkActv_D_RqTrnGear "Signal not transmitted on vehicles that do not have shift by wire.";
CM_ SG_ 92 TrnGearMsgTxt_D_Rq "Signal not transmitted on vehicles that do not have shift by wire.";
CM_ SG_ 92 TrnGearCmd_No_Cnt "Signal not transmitted on vehicles that do not have shift by wire.";
CM_ SG_ 1087 BattRgenLoChrg_D_RqEng "Signal not transmitted on diesel variant";
CM_ SG_ 1087 BattRgenLoDChrg_D_RqEng "Signal not transmitted on diesel variant";
CM_ SG_ 1087 FapLcInhbt_B_Rq "Signal not transmitted on diesel variant";
CM_ SG_ 1100 EngExhMdeQuiet_D2_Stat "Signal not transmitted on HEV & Diesel programs";
CM_ SG_ 1100 HvacCmprLim_D_Stat "Signal not transmitted on Diesel variants";
CM_ SG_ 1100 WakeAlarm1_T_Rq "Signal not transmitted on Gas variants";
CM_ SG_ 1100 WakeAlarm1_B_Typ "Signal not transmitted on Gas variants";
CM_ SG_ 1100 Veh_V_DsplyTrailCtlSet "Signal not transmitted on HEV & Diesel programs";
CM_ SG_ 1100 TrailCtlPt_B_Falt "Signal not transmitted on HEV & Diesel programs";
CM_ SG_ 1100 AutoTowAllw_D_StatMnu "Signal not transmitted on Gas & Diesel variants";
CM_ SG_ 1100 AutoTowActv_B_Stat "Signal not transmitted on Gas & Diesel variants";
CM_ SG_ 1086 EngMnfld_P_Actl "Signal not transmitted on HEV & Diesel programs";
CM_ SG_ 1086 ElLoadCtl_D_Rq "Signal not transmitted on HEV variants.";
CM_ SG_ 1071 CluPdl_PcRate_Actl "Signal not transmitted on HEV and Gas variants.";
CM_ SG_ 1071 CluPdlPosPcMeas_D_Qf "Signal not transmitted on HEV and Gas variants.";
CM_ SG_ 1071 CluPdlPos_Pc_Meas "Signal not transmitted on HEV and Gas variants.";
CM_ SG_ 1071 EngAoutIdl_N_Ntrl "Signal not transmitted on HEV variants and diesel.";
CM_ SG_ 1069 SlMde_D_Stat "IPC and HUD_ADV Receve from HS3 FGW 0x42D, not HS3 0x38A, MSG DCR 506. Signal not transmitted on Gas & HEV variants";
CM_ SG_ 1069 SlMde_D_RqDsply "IPC and HUD_ADV Receve from HS3 FGW 0x42D, not HS3 0x38A, MSG DCR 506. Signal not transmitted on Gas & HEV variants";
CM_ SG_ 1069 IsaOffst_D_Stat "Signal not transmitted on Gas & HEV variants";
CM_ SG_ 1069 ObdWarmUp_B_Complt "Signal not transmitted on diesel variants.";
CM_ SG_ 1069 EngMsgTxt_D_Rq "Signal not transmitted on diesel variants.";
CM_ SG_ 1069 EngClnt_Te_ActlDiag "Signal not transmitted on gas variants.";
CM_ SG_ 1069 EngLoad_Pc_CalcDiag "Signal not transmitted on gas variants.";
CM_ SG_ 1069 ApedPos_Pc_ActlDiag "Signal not transmitted on gas variants.";
CM_ SG_ 1060 RearDiffOilTeWarn_B_Rq "Signal not transmitted on HEV & Diesel programs";
CM_ SG_ 1060 RearDiffOil_Te_Actl "Signal not transmitted on HEV & Diesel programs";
CM_ SG_ 1057 FohEng_D_Rq "Signal not transmitted on vehicles that do not have the fuel operated heater feature. Signal not transmitted on HEV programs";
CM_ SG_ 1057 EngIdlShutDown_D_Stat "Signal not transmitted on diesel variants.";
CM_ SG_ 1057 FUEL_ALCOHOL_PERCNT "signal not transmitted on diesel and HEV variants.";
CM_ SG_ 1057 TrnTotTq_Rt_Est "Signal not transmitted on gas and HEV variants.";
CM_ SG_ 1057 TrnTotLss_Tq_Est "Signal not transmitted on gas and HEV variants.";
CM_ SG_ 1057 VehVLimStat_D_Actl "Signal not transmitted on gas and HEV variants.";
CM_ SG_ 1057 VehVLimActv_B_Actl "Signal not transmitted on gas and HEV variants.";
CM_ SG_ 562 GearNtrl_No_Cs "Powersplit HEVs with HF45, HPCM will Tx  this message.  For all other programs it will be Tx by PCM or TCM. ";
CM_ SG_ 562 GearNtrl_No_Cnt "Powersplit HEVs with HF45, HPCM will Tx  this message.  For all other programs it will be Tx by PCM or TCM. ";
CM_ SG_ 516 EngAoutNActl_D_QF "Signal not transmitted on Gas & HEV variants";
CM_ SG_ 516 EngAout3_N_Actl "Signal not transmitted on gas and diesel variants.";
CM_ SG_ 516 ApedPos_Pc_ActlArb "ABSGenSigTimeoutTime=1000";
CM_ SG_ 516 ApedPosPcActl_No_Cnt "Signal not transmitted on gas and diesel variants.";
CM_ SG_ 516 ApedPosPcActl_No_Cs "Signal not transmitted on gas and diesel variants.";
CM_ SG_ 514 VehVTrlrAid_B_Avail "Signal not transmitted on HEV variants.";
CM_ SG_ 514 GearRvrse_D_Actl "Do not implement GearRvrse_D_Actl  until eTracker 8804151 is approved, 11/24/09";
CM_ SG_ 512 PrplWhlTotTqRq_No_Cs "Signal not transmitted on gas & Diesel variants.";
CM_ SG_ 512 PrplWhlTotTqRq_No_Cnt "Signal not transmitted on gas & Diesel variants.";
CM_ SG_ 512 PtDrvMde_D_Stat "Signal not transmitted on Gas & HEV variants.";
CM_ SG_ 380 EngExhBrkOnLamp_B_Rq "Signal not transmitted on Gas variants";
CM_ SG_ 380 EngExhBrkAutoLamp_B_Rq "Signal not transmitted on Gas variants";
CM_ SG_ 380 EngAout_N_MxAllw "Signal not transmitted on Gas variants";
CM_ SG_ 380 EngExhBrkMde_D_Actl "Signal not transmitted on Gas variants";
CM_ SG_ 377 HvacAirFullOut_B_Rq "Signal not transmitted on diesel variant";
CM_ SG_ 377 FuelFlw_Vl_Dsply "Signal not transmitted on diesel variants.";
CM_ SG_ 377 FuelFillInlet_B_Dsply "Signal not transmitted on diesel variants.";
CM_ SG_ 377 OdoCount "Signal not transmitted on diesel variants.";
CM_ SG_ 377 EngOilLife_Pc_Actl "Signal not transmitted on diesel variants.";
CM_ SG_ 377 FuelFilterLamp_B_Dsply "Signal not transmitted on Gas & HEV variants";
CM_ SG_ 377 AirCondRec_B_Rq "Signal not transmitted on diesel variants.";
CM_ SG_ 377 AirCondClutch_B_Stats "Signal not transmitted on diesel variants.";
CM_ SG_ 376 GasPrtc_D_RqDsply "Signal not transmitted on HEV & Diesel variants.";
CM_ SG_ 376 EngAout_Aa_Actl "Signal not transmitted on HEV variants.";
CM_ SG_ 376 AslIconDsply_D_Rq "Signal not transmitted on HEV variants.";
CM_ SG_ 376 AslChime_B_Rq "Signal not transmitted on HEV variants.";
CM_ SG_ 376 HvacHtrCore2_Te_Actl "Signal not transmitted on Gas & Diesel variants";
CM_ SG_ 376 EcssLamp_D_RqDsply "Signal not transmitted on Gas & HEV variants";
CM_ SG_ 376 AirAmb_Te_Actl "Signal not transmitted on Gas variants";
CM_ SG_ 359 PrplWhlRgenMn_Tq_Actl "Signal not transmitted on Gas & Diesel variants";
CM_ SG_ 359 ElPw_D_StatStrtStop "Signal not transmitted on HEV variants.";
CM_ SG_ 359 TrnAin_Tq_Actl "Signal not transmitted on HEV variances.";
CM_ SG_ 359 PlgActvArb_B_Actl "Only supported on PHEV programs.  PlgActvArb_B_Actl HPCM will Tx on Powersplit PHEVs,  On MHT PHEVs the PCM_HEV will Tx and HPCM will Rx.";
CM_ SG_ 359 TrnAinTq_D_Qf "Signal not transmitted on HEV variances.";
CM_ SG_ 358 StopStrtStdby_D_Indic "Signal not transmitted on HEV variants.";
CM_ SG_ 358 StopStrtIODTxt_D_Rq "Signal not transmitted on HEV variants.";
CM_ SG_ 358 StopStrtDrvMde_D_Indic "Signal not transmitted on HEV variants.";
CM_ SG_ 358 StopStrtMsgTxt_D_Rq "Signal not transmitted on HEV variants.";
CM_ SG_ 358 HiElPwInhbt_B_Stat "Signal not transmitted on HEV programs";
CM_ SG_ 358 AutoStopPtDelta_I_Est "Signal not transmitted on HEV variants. ";
CM_ SG_ 357 BpedDrvAppl_D_Actl "CCMGenSigTimeoutTime=1000";
CM_ SG_ 357 CcStat_D_Actl "ABSGenSigTimeoutTime=1000";
CM_ SG_ 357 EngAout_N_MnAllw "Signal not transmitted on Gas & Diesel variants.";
CM_ SG_ 357 AccStopMde_D_Rq "ABSGenSigTimeoutTime=1000";
CM_ SG_ 342 EngOvrhtMitgActv_D_Ind "Signal not transmitted on diesel.";
CM_ SG_ 342 EngGoutLss_Tq_Est "Signal not transmitted on gas and diesel variants.";
CM_ SG_ 342 EngOil_Te_Actl "Signal not transmitted on Gas & HEV variants. ";
CM_ SG_ 954 GenericSwtch2_No_Actl "U625 Police Wig Wag feature";
CM_ SG_ 935 SodRight_D_Stat "IPCGenSigTimeoutTime=1600";
CM_ SG_ 935 Side_Detect_R_Illum "DDMGenSigTimeoutTime=2000";
CM_ SG_ 935 SodSnsRight_D_Stat "IPCGenSigTimeoutTime=1600";
CM_ SG_ 935 SodAlrtRight_D_Stat "DDMGenSigTimeoutTime=2000";
CM_ SG_ 1112 BattTracClntPmp_D_Stat "48V mHEV: ECM_HEVDSL is Tx,  MHT HEV: PCM_HEV is Tx,  Powersplit HEV: SOBDMC_HPCM is Tx";
CM_ SG_ 1050 Outside_Air_Temp_Stat "Filtered value, i.e. same as disply for customer";
CM_ SG_ 1009 CenterStackRing_D_Actl "The Center Stack sends the CPLR a signal to turn On or Off the light Ring, This is a customer selectable preference switch";
CM_ SG_ 1009 APIM_NumberofTracks_St "Object NumberofTracks";
CM_ SG_ 1009 APIM_ActiveTrackNum_St "Object.ActiveTrackNum";
CM_ SG_ 360 GsmSrvcRqd_B_Rq "Signal not transmitted on vehicles that do not have shift by wire.";
CM_ SG_ 360 TrnGearPwmFalt_B_Actl "Signal not transmitted on vehicles that do not have shift by wire.";
CM_ SG_ 360 GearButtnStuck_B_Actl "Signal not transmitted on vehicles that do not have shift by wire.";
CM_ SG_ 90 TrnGsmNtmState_D_Actl "Signal not transmitted on vehicles that do not have shift by wire.";
CM_ SG_ 90 DrQltyDrv_D_StatGsm "Signal not transmitted on vehicles that do not have shift by wire.";
CM_ SG_ 90 TrnBtsiOvrrd_B_Stat "Signal not transmitted on vehicles that do not have shift by wire.";
CM_ SG_ 90 TrnValidGearRq_D_Stat "Signal not transmitted on vehicles that do not have shift by wire.";
CM_ SG_ 90 TrnGearRqCnt_B_Actl "Signal not transmitted on vehicles that do not have shift by wire.";
CM_ SG_ 90 TrnGearButtn_U_Actl "Signal not transmitted on vehicles that do not have shift by wire.";
CM_ SG_ 90 TrnGearButtn_B_ActlR2 "Signal not transmitted on vehicles that do not have shift by wire.";
CM_ SG_ 90 TrnGearButtn_B_ActlR1 "Signal not transmitted on vehicles that do not have shift by wire.";
CM_ SG_ 90 TrnGearButtn_B_ActlR0 "Signal not transmitted on vehicles that do not have shift by wire.";
CM_ SG_ 90 TrnGearButtn_B_ActlP2 "Signal not transmitted on vehicles that do not have shift by wire.";
CM_ SG_ 90 TrnGearButtn_B_ActlP1 "Signal not transmitted on vehicles that do not have shift by wire.";
CM_ SG_ 90 TrnGearButtn_B_ActlP0 "Signal not transmitted on vehicles that do not have shift by wire.";
CM_ SG_ 90 TrnGearButtn_B_ActlN2 "Signal not transmitted on vehicles that do not have shift by wire.";
CM_ SG_ 90 TrnGearButtn_B_ActlN1 "Signal not transmitted on vehicles that do not have shift by wire.";
CM_ SG_ 90 TrnGearButtn_B_ActlN0 "Signal not transmitted on vehicles that do not have shift by wire.";
CM_ SG_ 90 TrnGearButtn_B_ActlM2 "Signal not transmitted on vehicles that do not have shift by wire.";
CM_ SG_ 90 TrnGearButtn_B_ActlM1 "Signal not transmitted on vehicles that do not have shift by wire.";
CM_ SG_ 90 TrnGearButtn_B_ActlM0 "Signal not transmitted on vehicles that do not have shift by wire.";
CM_ SG_ 90 TrnGearButtn_B_ActlD2 "Signal not transmitted on vehicles that do not have shift by wire.";
CM_ SG_ 90 TrnGearButtn_B_ActlD1 "Signal not transmitted on vehicles that do not have shift by wire.";
CM_ SG_ 90 TrnGearButtn_B_ActlD0 "Signal not transmitted on vehicles that do not have shift by wire.";
CM_ SG_ 90 TrnGear_No_Cs "Signal not transmitted on vehicles that do not have shift by wire.";
CM_ SG_ 90 TrnGear_No_Cnt "Signal not transmitted on vehicles that do not have shift by wire.";
CM_ SG_ 90 TrnGear_D_RqDrv "Signal not transmitted on vehicles that do not have shift by wire.";
CM_ SG_ 90 BrkSwtchPos_B_ActlGsm "Signal not transmitted on vehicles that do not have shift by wire.";
CM_ SG_ 138 SteWhlRelCalib_An_Sns "Signal is not transmitted on vehicles where PSCM is transmitting the message that contains this signal. Signal data set to 0x0 for ABS only vehicle option content";
CM_ SG_ 1093 StopLamp_B_RqTrlrBrk "Signal not transmitted on all variants.";
CM_ SG_ 792 ElTrip_L_Dsply "Key cycle trip distance driven with the engine off (Trip EV Miles)";
CM_ SG_ 792 ElLongTerm_L_Dsply "Long term distance distance driven with the engine off since the last long term reset (Long Term EV Miles).";
CM_ SG_ 765 Mc_VehTimeFrmtUsrSel_St "Object.BodyInterface.Settings.VehicleTimeFormatUserSelection";
CM_ SG_ 765 Mc_VehUntTrpCoUsrSel_St "Object.VehicleSettings.Disp_Miles_Kilometers.Rq";
CM_ SG_ 765 Mc_VehUnitTempUsrSel_St "Object.VehicleSettings.Disp_Temperature.Rq";
CM_ SG_ 765 Mc_VehLangUsrSel_St "Object.BodyInterface.Settings.VehicleLanguageUserSelection Object Vehicle Settings.Disp_LangSel";
CM_ SG_ 934 Side_Detect_L_Illum "DDMGenSigTimeoutTime=2000";
CM_ SG_ 934 SodLeft_D_Stat "IPCGenSigTimeoutTime=1600";
CM_ SG_ 934 SodSnsLeft_D_Stat "IPCGenSigTimeoutTime=1600";
CM_ SG_ 934 SodAlrtLeft_D_Stat "DDMGenSigTimeoutTime=2000";
CM_ SG_ 1072 MetricActv_B_Actl "0 =Inactive(English), 1=Active(Metric)";
CM_ SG_ 145 VehYaw_W_Actl "CCMGenSigTimeoutTime=1000";
CM_ SG_ 931 CrnkInhbt_No_Cs "Signal not transmitted on gas and HEV variants.";
CM_ SG_ 931 CrnkInhbt_No_Cnt "Signal not transmitted on gas and HEV variants.";
CM_ SG_ 947 Dimming_Lvl "Refer to Vehicle Interior Illum Dimming Ctrl Sys Eng Spec, Table 2";
CM_ SG_ 947 PrkBrkActv_B_Actl "Signal not transmitted on vehicles with electric park brake. ";
CM_ SG_ 394 HaDsply_No_Cs "Signal not transmitted on gas variants.";
CM_ SG_ 394 HaDsply_No_Cnt "Signal not transmitted on gas variants.";
CM_ SG_ 391 CmbbBrkDecel_A_Rq "ABSGenSigTimeoutTime=1000";
CM_ SG_ 391 CmbbBrkPrchg_D_Rq "ABSGenSigTimeoutTime=1000";
CM_ SG_ 391 CmbbBrkDecel_B_Rq "ABSGenSigTimeoutTime=1000";
CM_ SG_ 391 CmbbBaSens_D_Rq "ABSGenSigTimeoutTime=1000";
CM_ SG_ 390 AccBrkTot_A_Rq "ABSGenSigTimeoutTime=1000";
CM_ SG_ 390 AccBrkPrkEl_B_Rq "ABSGenSigTimeoutTime=1000";
CM_ SG_ 390 AccPrpl_A_Rq "PCMGenSigTimeoutTime=1000";
CM_ SG_ 390 AccBrkPrchg_B_Rq "ABSGenSigTimeoutTime=1000";
CM_ SG_ 390 AccBrkDecel_B_Rq "ABSGenSigTimeoutTime=1000";
CM_ SG_ 390 AccStopStat_B_Rq "ABSGenSigTimeoutTime=1000";
CM_ SG_ 942 PrkAidRdiusRight_L_Dsply "MSGDCR 679, set all signals to OnChange";
CM_ SG_ 942 PrkAidRdiusLeft_L_Dsply "MSGDCR 679, set all signals to OnChange";
CM_ SG_ 942 PrkAidDrvDir_D_Stat "MSGDCR 679, set all signals to OnChange";

BA_DEF_ BO_  "OvtpPushApplication" ENUM  "FALSE","TRUE";
BA_DEF_ BU_  "OvtpOperationMode" ENUM  "SERVER","CLIENT";
BA_DEF_ BU_  "OvtpEcuAddress" INT 0 1022;
BA_DEF_ SG_  "ECGUsedRxSignal" ENUM  "No","Yes";
BA_DEF_ SG_  "ECGUsedTxSignal" ENUM  "No","Yes";
BA_DEF_ BO_  "VFrameFormat" ENUM  "StandardCAN","ExtendedCAN","reserved","reserved","reserved","reserved","reserved","reserved","reserved","reserved","reserved","reserved","reserved","reserved","StandardCAN_FD","ExtendedCAN_FD";
BA_DEF_  "BusType" STRING;
BA_DEF_ BO_  "FrameRouting" STRING;
BA_DEF_ BO_  "FrameGatewayNetwork" STRING;
BA_DEF_ BO_  "NetworkInitialization" ENUM  "No","Yes";
BA_DEF_ BO_  "FrameGatewayId" HEX 0 1407;
BA_DEF_ BO_  "EventRateOfChange" INT 10 10000;
BA_DEF_ BO_  "GenMsgStartDelayTime" INT 0 10000;
BA_DEF_ BO_  "GenMsgNrOfRepetition" INT 0 100;
BA_DEF_ BO_  "GenMsgDelayTime" INT 0 1000;
BA_DEF_ BO_  "GenMsgCycleTime" INT 0 100000;
BA_DEF_ BO_  "GenMsgSendType" ENUM  "FixedPeriodic","Event","EnabledPeriodic","NotUsed","NotUsed","EventPeriodic","NotUsed","NotUsed","NoMsgSendType";
BA_DEF_ SG_  "U_T6_MCA_MY2020_Tx" ENUM  "No","Yes";
BA_DEF_ SG_  "U_P702_MY2021_Tx" ENUM  "No","Yes";
BA_DEF_ SG_  "U_CX727_MY2021_Tx" ENUM  "No","Yes";
BA_DEF_ SG_  "U_T6_MCA_MY2020_Rx" ENUM  "No","Yes";
BA_DEF_ SG_  "U_P702_MY2021_Rx" ENUM  "No","Yes";
BA_DEF_ SG_  "U_CX727_MY2021_Rx" ENUM  "No","Yes";
BA_DEF_ SG_  "GenSigStartValue" HEX 0 268435455;
BA_DEF_ SG_  "MetaData" ENUM  "No","Yes";
BA_DEF_ SG_  "ContentDependant" ENUM  "No","Yes";
BA_DEF_ SG_  "GenSigStartValueInteger" INT 0 1000000000;
BA_DEF_ SG_  "UsedOnPgmDBC" ENUM  "No","Yes";
BA_DEF_ SG_  "CrossOver_InfoCAN" ENUM  "No","Yes";
BA_DEF_ SG_  "WakeupSignal" ENUM  "No","Yes";
BA_DEF_ SG_  "GenSigInactiveValue" INT 0 100000;
BA_DEF_ SG_  "GenSigSendType" ENUM  "Cyclic","OnWrite","vector_leerstring","OnChange","vector_leerstring","IfActive","vector_leerstring","NoSigSendType";
BA_DEF_ BO_  "SCP_FreshnessValueLength" INT 0 512;
BA_DEF_ BO_  "AuthFreshnessCounterSyncAttempt" INT 0 512;
BA_DEF_ BO_  "SCP_FreshnessValueTxLength" INT 0 512;
BA_DEF_ BO_  "SCP_AuthInfoTxLength" INT 0 512;
BA_DEF_ BO_  "ProgBWConditional" STRING;
BA_DEF_ BO_  "NmAsrMessage" ENUM  "No","Yes";
BA_DEF_ BO_  "TpApplType" STRING;
BA_DEF_ BO_  "DiagState" ENUM  "No","Yes";
BA_DEF_ BO_  "TpTxIndex" INT 0 536870911;
BA_DEF_ BO_  "DiagRequest" ENUM  "No","Yes";
BA_DEF_ BO_  "DiagResponse" ENUM  "No","Yes";
BA_DEF_ BO_  "GenMsgILSupport" ENUM  "No","Yes";
BA_DEF_ BU_  "Terminator" ENUM  "No","Yes";
BA_DEF_ BU_  "NodeWakeUpTime" INT 0 10000;
BA_DEF_ BU_  "NodeStartUpTime" INT 0 10000;
BA_DEF_ BU_  "NmAsrNodeIdentifier" HEX 128 255;
BA_DEF_ BU_  "NmAsrNode" ENUM  "No","Yes";
BA_DEF_ BU_  "PowerType" ENUM  "Switched","Latched","Sleep","vector_leerstring","vector_leerstring";
BA_DEF_ BU_  "DiagNode" ENUM  "GGDS","GDS","NONE";
BA_DEF_ BU_  "EOL_SB_Flash" ENUM  "GGDS","GDS","NONE","vector_leerstring";
BA_DEF_ BU_  "NmStationAddress" INT 0 255;
BA_DEF_ BU_  "ILUsed" ENUM  "No","Yes";
BA_DEF_ BU_  "NosPackage" ENUM  "None","I3_1","I3_2","1.0.1","RP","EuCD","Volcano","I3_3","FNOS_Autosar";
BA_DEF_ BU_  "PackageID" STRING;
BA_DEF_ BU_  "GatewayECU" ENUM  "No","Yes";
BA_DEF_  "NetworkSpeed" ENUM  "500kBits/s","125kBit/s";
BA_DEF_  "VersionNumber" INT 0 10000;
BA_DEF_  "StarNetworkGwType" ENUM  "0=NotDefined","1=HS1","2=HS2","3=HS3","4=HS4","5=HS5","6=MS1","7=HS6","8=HS7","9=MS2","10=FD1","11=FD2","12=FD3","13=FD4","14=FD5","15=FD6","16=FD7","17=FD8";
BA_DEF_  "CMDB_Version" STRING;
BA_DEF_  "NmType" STRING;
BA_DEF_  "NmAsrMessageCount" INT 128 128;
BA_DEF_  "NmAsrBaseAddress" HEX 1408 1408;
BA_DEF_  "DBName" STRING;
BA_DEF_  "VersionDay" INT 1 31;
BA_DEF_  "Manufacturer" STRING;
BA_DEF_  "VersionMonth" INT 1 12;
BA_DEF_  "VersionYear" INT 2000 3000;
BA_DEF_  "NmBaseAddress" HEX 1280 1280;
BA_DEF_  "NmMessageCount" INT 0 128;
BA_DEF_DEF_  "OvtpPushApplication" "FALSE";
BA_DEF_DEF_  "OvtpOperationMode" "SERVER";
BA_DEF_DEF_  "OvtpEcuAddress" 0;
BA_DEF_DEF_  "ECGUsedRxSignal" "No";
BA_DEF_DEF_  "ECGUsedTxSignal" "No";
BA_DEF_DEF_  "VFrameFormat" "ExtendedCAN_FD";
BA_DEF_DEF_  "BusType" "";
BA_DEF_DEF_  "FrameRouting" "NONE";
BA_DEF_DEF_  "FrameGatewayNetwork" "NONE";
BA_DEF_DEF_  "NetworkInitialization" "Yes";
BA_DEF_DEF_  "FrameGatewayId" 0;
BA_DEF_DEF_  "EventRateOfChange" 10000;
BA_DEF_DEF_  "GenMsgStartDelayTime" 0;
BA_DEF_DEF_  "GenMsgNrOfRepetition" 1;
BA_DEF_DEF_  "GenMsgDelayTime" 20;
BA_DEF_DEF_  "GenMsgCycleTime" 0;
BA_DEF_DEF_  "GenMsgSendType" "NoMsgSendType";
BA_DEF_DEF_  "U_T6_MCA_MY2020_Tx" "No";
BA_DEF_DEF_  "U_P702_MY2021_Tx" "No";
BA_DEF_DEF_  "U_CX727_MY2021_Tx" "No";
BA_DEF_DEF_  "U_T6_MCA_MY2020_Rx" "No";
BA_DEF_DEF_  "U_P702_MY2021_Rx" "No";
BA_DEF_DEF_  "U_CX727_MY2021_Rx" "No";
BA_DEF_DEF_  "GenSigStartValue" 0;
BA_DEF_DEF_  "MetaData" "No";
BA_DEF_DEF_  "ContentDependant" "No";
BA_DEF_DEF_  "GenSigStartValueInteger" 0;
BA_DEF_DEF_  "UsedOnPgmDBC" "Yes";
BA_DEF_DEF_  "CrossOver_InfoCAN" "No";
BA_DEF_DEF_  "WakeupSignal" "No";
BA_DEF_DEF_  "GenSigInactiveValue" 0;
BA_DEF_DEF_  "GenSigSendType" "NoSigSendType";
BA_DEF_DEF_  "SCP_FreshnessValueLength" 64;
BA_DEF_DEF_  "AuthFreshnessCounterSyncAttempt" 2;
BA_DEF_DEF_  "SCP_FreshnessValueTxLength" 8;
BA_DEF_DEF_  "SCP_AuthInfoTxLength" 56;
BA_DEF_DEF_  "ProgBWConditional" "NONE";
BA_DEF_DEF_  "NmAsrMessage" "No";
BA_DEF_DEF_  "TpApplType" "";
BA_DEF_DEF_  "DiagState" "No";
BA_DEF_DEF_  "TpTxIndex" 0;
BA_DEF_DEF_  "DiagRequest" "No";
BA_DEF_DEF_  "DiagResponse" "No";
BA_DEF_DEF_  "GenMsgILSupport" "Yes";
BA_DEF_DEF_  "Terminator" "No";
BA_DEF_DEF_  "NodeWakeUpTime" 10;
BA_DEF_DEF_  "NodeStartUpTime" 250;
BA_DEF_DEF_  "NmAsrNodeIdentifier" 128;
BA_DEF_DEF_  "NmAsrNode" "No";
BA_DEF_DEF_  "PowerType" "Switched";
BA_DEF_DEF_  "DiagNode" "GGDS";
BA_DEF_DEF_  "EOL_SB_Flash" "GGDS";
BA_DEF_DEF_  "NmStationAddress" 0;
BA_DEF_DEF_  "ILUsed" "Yes";
BA_DEF_DEF_  "NosPackage" "I3_3";
BA_DEF_DEF_  "PackageID" "08.05.00.00.71.xx.xx.rr.00.00";
BA_DEF_DEF_  "GatewayECU" "No";
BA_DEF_DEF_  "NetworkSpeed" "500kBits/s";
BA_DEF_DEF_  "VersionNumber" 1;
BA_DEF_DEF_  "StarNetworkGwType" "0=NotDefined";
BA_DEF_DEF_  "CMDB_Version" "v11.01";
BA_DEF_DEF_  "NmType" "Ford-OSEK";
BA_DEF_DEF_  "NmAsrMessageCount" 128;
BA_DEF_DEF_  "NmAsrBaseAddress" 1408;
BA_DEF_DEF_  "DBName" "";
BA_DEF_DEF_  "VersionDay" 1;
BA_DEF_DEF_  "Manufacturer" "Ford";
BA_DEF_DEF_  "VersionMonth" 1;
BA_DEF_DEF_  "VersionYear" 2011;
BA_DEF_DEF_  "NmBaseAddress" 1280;
BA_DEF_DEF_  "NmMessageCount" 128;
BA_ "BusType" "CAN FD";
BA_ "VersionYear" 2019;
BA_ "VersionMonth" 4;
BA_ "VersionDay" 11;
BA_ "CMDB_Version" "FNV2_v18.07";
BA_ "StarNetworkGwType" 10;
BA_ "VersionNumber" 6;
BA_ "DBName" "FD1_CAN";
BA_ "NmStationAddress" BU_ VDM 48;
BA_ "OvtpEcuAddress" BU_ VDM 32;
BA_ "OvtpEcuAddress" BU_ CMR_DSMC 187;
BA_ "NmStationAddress" BU_ CMR_DSMC 95;
BA_ "PowerType" BU_ CMR_DSMC 2;
BA_ "NmAsrNode" BU_ CMR_DSMC 1;
BA_ "NmAsrNodeIdentifier" BU_ CMR_DSMC 223;
BA_ "OvtpEcuAddress" BU_ SOBDMC_HPCM_FD1 17;
BA_ "NmStationAddress" BU_ SOBDMC_HPCM_FD1 37;
BA_ "OvtpEcuAddress" BU_ IPMA_ADAS 33;
BA_ "NmStationAddress" BU_ IPMA_ADAS 28;
BA_ "NodeStartUpTime" BU_ IPMA_ADAS 300;
BA_ "OvtpEcuAddress" BU_ PSCM 48;
BA_ "NmStationAddress" BU_ PSCM 53;
BA_ "PowerType" BU_ PSCM 1;
BA_ "NmAsrNode" BU_ PSCM 1;
BA_ "NmAsrNodeIdentifier" BU_ PSCM 181;
BA_ "Terminator" BU_ PSCM 1;
BA_ "OvtpEcuAddress" BU_ ABS_ESC 40;
BA_ "NmStationAddress" BU_ ABS_ESC 22;
BA_ "PowerType" BU_ ABS_ESC 2;
BA_ "NmAsrNode" BU_ ABS_ESC 1;
BA_ "NmAsrNodeIdentifier" BU_ ABS_ESC 150;
BA_ "NodeStartUpTime" BU_ ABS_ESC 1000;
BA_ "NodeWakeUpTime" BU_ ABS_ESC 300;
BA_ "OvtpEcuAddress" BU_ TCCM 25;
BA_ "NmStationAddress" BU_ TCCM 33;
BA_ "NmAsrNode" BU_ TCCM 1;
BA_ "NmAsrNodeIdentifier" BU_ TCCM 161;
BA_ "NodeStartUpTime" BU_ TCCM 1000;
BA_ "NodeWakeUpTime" BU_ TCCM 25;
BA_ "OvtpEcuAddress" BU_ TCM_DSL 24;
BA_ "NmStationAddress" BU_ TCM_DSL 32;
BA_ "PowerType" BU_ TCM_DSL 1;
BA_ "NmAsrNode" BU_ TCM_DSL 1;
BA_ "NmAsrNodeIdentifier" BU_ TCM_DSL 160;
BA_ "NodeWakeUpTime" BU_ TCM_DSL 200;
BA_ "NosPackage" BU_ TCM_DSL 4;
BA_ "OvtpEcuAddress" BU_ PCM_HEV 16;
BA_ "NmStationAddress" BU_ PCM_HEV 21;
BA_ "PowerType" BU_ PCM_HEV 1;
BA_ "NmAsrNode" BU_ PCM_HEV 1;
BA_ "NmAsrNodeIdentifier" BU_ PCM_HEV 149;
BA_ "NodeStartUpTime" BU_ PCM_HEV 350;
BA_ "OvtpEcuAddress" BU_ PCM 16;
BA_ "NmStationAddress" BU_ PCM 21;
BA_ "PowerType" BU_ PCM 1;
BA_ "NmAsrNode" BU_ PCM 1;
BA_ "NmAsrNodeIdentifier" BU_ PCM 149;
BA_ "NodeStartUpTime" BU_ PCM 350;
BA_ "OvtpEcuAddress" BU_ ECM_Diesel 16;
BA_ "NmStationAddress" BU_ ECM_Diesel 21;
BA_ "PowerType" BU_ ECM_Diesel 1;
BA_ "NmAsrNode" BU_ ECM_Diesel 1;
BA_ "NmAsrNodeIdentifier" BU_ ECM_Diesel 149;
BA_ "OvtpEcuAddress" BU_ GWM 216;
BA_ "OvtpOperationMode" BU_ GWM 1;
BA_ "NmStationAddress" BU_ GWM 30;
BA_ "PowerType" BU_ GWM 2;
BA_ "NmAsrNode" BU_ GWM 1;
BA_ "NmAsrNodeIdentifier" BU_ GWM 158;
BA_ "NodeStartUpTime" BU_ GWM 100;
BA_ "Terminator" BU_ GWM 1;
BA_ "GatewayECU" BU_ GWM 1;
BA_ "NosPackage" BU_ GWM 4;
BA_ "GenMsgSendType" BO_ 823 5;
BA_ "GenMsgCycleTime" BO_ 823 1000;
BA_ "VFrameFormat" BO_ 823 14;
BA_ "GenMsgSendType" BO_ 824 5;
BA_ "GenMsgCycleTime" BO_ 824 1000;
BA_ "VFrameFormat" BO_ 824 14;
BA_ "FrameGatewayId" BO_ 949 949;
BA_ "FrameGatewayNetwork" BO_ 949 "HS1_CAN";
BA_ "FrameRouting" BO_ 949 "";
BA_ "VFrameFormat" BO_ 949 14;
BA_ "GenMsgILSupport" BO_ 1825 0;
BA_ "DiagRequest" BO_ 1825 1;
BA_ "GenMsgSendType" BO_ 1825 1;
BA_ "GenMsgDelayTime" BO_ 1825 0;
BA_ "NetworkInitialization" BO_ 1825 0;
BA_ "VFrameFormat" BO_ 1825 14;
BA_ "GenMsgDelayTime" BO_ 524 0;
BA_ "GenMsgCycleTime" BO_ 524 10;
BA_ "GenMsgSendType" BO_ 524 0;
BA_ "ProgBWConditional" BO_ 524 "MSGDCR1008_CX48X_V03_HS1D_56.84_mHEV_54.89";
BA_ "VFrameFormat" BO_ 524 14;
BA_ "FrameRouting" BO_ 740 "";
BA_ "FrameGatewayNetwork" BO_ 740 "HS1_CAN";
BA_ "FrameGatewayId" BO_ 740 740;
BA_ "VFrameFormat" BO_ 740 14;
BA_ "GenMsgCycleTime" BO_ 1160 1000;
BA_ "GenMsgSendType" BO_ 1160 5;
BA_ "VFrameFormat" BO_ 1160 14;
BA_ "GenMsgCycleTime" BO_ 776 1000;
BA_ "GenMsgSendType" BO_ 776 5;
BA_ "VFrameFormat" BO_ 776 14;
BA_ "GenMsgCycleTime" BO_ 775 1000;
BA_ "GenMsgSendType" BO_ 775 5;
BA_ "VFrameFormat" BO_ 775 14;
BA_ "GenMsgCycleTime" BO_ 774 1000;
BA_ "GenMsgSendType" BO_ 774 5;
BA_ "VFrameFormat" BO_ 774 14;
BA_ "FrameGatewayId" BO_ 811 811;
BA_ "FrameGatewayNetwork" BO_ 811 "HS3_CAN";
BA_ "FrameRouting" BO_ 811 "";
BA_ "VFrameFormat" BO_ 811 14;
BA_ "GenMsgSendType" BO_ 850 0;
BA_ "GenMsgCycleTime" BO_ 850 150;
BA_ "VFrameFormat" BO_ 850 14;
BA_ "GenMsgCycleTime" BO_ 563 1000;
BA_ "GenMsgSendType" BO_ 563 5;
BA_ "VFrameFormat" BO_ 563 14;
BA_ "GenMsgILSupport" BO_ 1833 0;
BA_ "DiagResponse" BO_ 1833 1;
BA_ "GenMsgSendType" BO_ 1833 1;
BA_ "GenMsgDelayTime" BO_ 1833 0;
BA_ "NetworkInitialization" BO_ 1833 0;
BA_ "VFrameFormat" BO_ 1833 14;
BA_ "FrameRouting" BO_ 570 "";
BA_ "GenMsgSendType" BO_ 570 0;
BA_ "GenMsgCycleTime" BO_ 570 20;
BA_ "GenMsgDelayTime" BO_ 570 10;
BA_ "VFrameFormat" BO_ 570 14;
BA_ "FrameRouting" BO_ 837 "";
BA_ "GenMsgSendType" BO_ 837 5;
BA_ "GenMsgCycleTime" BO_ 837 1000;
BA_ "VFrameFormat" BO_ 837 14;
BA_ "FrameRouting" BO_ 885 "";
BA_ "GenMsgSendType" BO_ 885 0;
BA_ "GenMsgCycleTime" BO_ 885 200;
BA_ "VFrameFormat" BO_ 885 14;
BA_ "FrameRouting" BO_ 1150 "";
BA_ "FrameGatewayNetwork" BO_ 1150 "HS3_CAN";
BA_ "FrameGatewayId" BO_ 1150 1118;
BA_ "VFrameFormat" BO_ 1150 14;
BA_ "FrameRouting" BO_ 542 "";
BA_ "FrameGatewayNetwork" BO_ 542 "HS4_CAN";
BA_ "FrameGatewayId" BO_ 542 542;
BA_ "VFrameFormat" BO_ 542 14;
BA_ "FrameRouting" BO_ 2612224016 "";
BA_ "TpTxIndex" BO_ 2612224016 464535768;
BA_ "GenMsgSendType" BO_ 2612224016 1;
BA_ "GenMsgDelayTime" BO_ 2612224016 0;
BA_ "NetworkInitialization" BO_ 2612224016 0;
BA_ "OvtpPushApplication" BO_ 2612224016 1;
BA_ "FrameRouting" BO_ 810 "";
BA_ "GenMsgCycleTime" BO_ 810 1000;
BA_ "GenMsgSendType" BO_ 810 5;
BA_ "VFrameFormat" BO_ 810 14;
BA_ "FrameRouting" BO_ 550 "";
BA_ "GenMsgCycleTime" BO_ 550 1000;
BA_ "GenMsgSendType" BO_ 550 5;
BA_ "VFrameFormat" BO_ 550 14;
BA_ "FrameRouting" BO_ 639 "";
BA_ "GenMsgCycleTime" BO_ 639 1000;
BA_ "GenMsgSendType" BO_ 639 5;
BA_ "VFrameFormat" BO_ 639 14;
BA_ "FrameRouting" BO_ 530 "";
BA_ "GenMsgCycleTime" BO_ 530 1000;
BA_ "GenMsgSendType" BO_ 530 5;
BA_ "VFrameFormat" BO_ 530 14;
BA_ "FrameRouting" BO_ 1142 "";
BA_ "GenMsgSendType" BO_ 1142 0;
BA_ "GenMsgCycleTime" BO_ 1142 500;
BA_ "VFrameFormat" BO_ 1142 14;
BA_ "FrameRouting" BO_ 817 "";
BA_ "FrameGatewayId" BO_ 817 817;
BA_ "FrameGatewayNetwork" BO_ 817 "HS1_CAN";
BA_ "VFrameFormat" BO_ 817 14;
BA_ "FrameRouting" BO_ 879 "";
BA_ "FrameGatewayNetwork" BO_ 879 "HS1_CAN";
BA_ "FrameGatewayId" BO_ 879 879;
BA_ "VFrameFormat" BO_ 879 14;
BA_ "FrameRouting" BO_ 878 "";
BA_ "GenMsgSendType" BO_ 878 5;
BA_ "GenMsgCycleTime" BO_ 878 1000;
BA_ "VFrameFormat" BO_ 878 14;
BA_ "FrameRouting" BO_ 395 "";
BA_ "FrameGatewayNetwork" BO_ 395 "HS3_CAN";
BA_ "FrameGatewayId" BO_ 395 395;
BA_ "VFrameFormat" BO_ 395 14;
BA_ "TpTxIndex" BO_ 2611055832 463572184;
BA_ "FrameRouting" BO_ 2611055832 "";
BA_ "NetworkInitialization" BO_ 2611055832 0;
BA_ "GenMsgDelayTime" BO_ 2611055832 0;
BA_ "GenMsgSendType" BO_ 2611055832 1;
BA_ "TpTxIndex" BO_ 2611054808 463571160;
BA_ "FrameRouting" BO_ 2611054808 "";
BA_ "NetworkInitialization" BO_ 2611054808 0;
BA_ "GenMsgDelayTime" BO_ 2611054808 0;
BA_ "GenMsgSendType" BO_ 2611054808 1;
BA_ "TpTxIndex" BO_ 2611026136 463542488;
BA_ "FrameRouting" BO_ 2611026136 "";
BA_ "NetworkInitialization" BO_ 2611026136 0;
BA_ "GenMsgDelayTime" BO_ 2611026136 0;
BA_ "GenMsgSendType" BO_ 2611026136 1;
BA_ "TpTxIndex" BO_ 2611025112 463541464;
BA_ "FrameRouting" BO_ 2611025112 "";
BA_ "NetworkInitialization" BO_ 2611025112 0;
BA_ "GenMsgDelayTime" BO_ 2611025112 0;
BA_ "GenMsgSendType" BO_ 2611025112 1;
BA_ "TpTxIndex" BO_ 2610975960 463492312;
BA_ "FrameRouting" BO_ 2610975960 "";
BA_ "NetworkInitialization" BO_ 2610975960 0;
BA_ "GenMsgDelayTime" BO_ 2610975960 0;
BA_ "GenMsgSendType" BO_ 2610975960 1;
BA_ "FrameRouting" BO_ 2610007256 "";
BA_ "NetworkInitialization" BO_ 2610007256 0;
BA_ "GenMsgDelayTime" BO_ 2610007256 0;
BA_ "GenMsgSendType" BO_ 2610007256 1;
BA_ "TpTxIndex" BO_ 2610007256 462523608;
BA_ "FrameRouting" BO_ 2610006232 "";
BA_ "NetworkInitialization" BO_ 2610006232 0;
BA_ "GenMsgDelayTime" BO_ 2610006232 0;
BA_ "GenMsgSendType" BO_ 2610006232 1;
BA_ "TpTxIndex" BO_ 2610006232 462522584;
BA_ "FrameRouting" BO_ 2609977560 "";
BA_ "NetworkInitialization" BO_ 2609977560 0;
BA_ "GenMsgDelayTime" BO_ 2609977560 0;
BA_ "GenMsgSendType" BO_ 2609977560 1;
BA_ "TpTxIndex" BO_ 2609977560 462493912;
BA_ "FrameRouting" BO_ 2609976536 "";
BA_ "NetworkInitialization" BO_ 2609976536 0;
BA_ "GenMsgDelayTime" BO_ 2609976536 0;
BA_ "GenMsgSendType" BO_ 2609976536 1;
BA_ "TpTxIndex" BO_ 2609976536 462492888;
BA_ "FrameRouting" BO_ 2609927384 "";
BA_ "NetworkInitialization" BO_ 2609927384 0;
BA_ "GenMsgDelayTime" BO_ 2609927384 0;
BA_ "GenMsgSendType" BO_ 2609927384 1;
BA_ "TpTxIndex" BO_ 2609927384 462443736;
BA_ "TpTxIndex" BO_ 2611175523 463572184;
BA_ "FrameRouting" BO_ 2611175523 "";
BA_ "NetworkInitialization" BO_ 2611175523 0;
BA_ "GenMsgDelayTime" BO_ 2611175523 0;
BA_ "GenMsgSendType" BO_ 2611175523 1;
BA_ "TpTxIndex" BO_ 2612224099 464620760;
BA_ "OvtpPushApplication" BO_ 2612224099 1;
BA_ "FrameRouting" BO_ 2612224099 "";
BA_ "NetworkInitialization" BO_ 2612224099 0;
BA_ "GenMsgDelayTime" BO_ 2612224099 0;
BA_ "GenMsgSendType" BO_ 2612224099 1;
BA_ "TpTxIndex" BO_ 2611175522 463571160;
BA_ "FrameRouting" BO_ 2611175522 "";
BA_ "NetworkInitialization" BO_ 2611175522 0;
BA_ "GenMsgDelayTime" BO_ 2611175522 0;
BA_ "GenMsgSendType" BO_ 2611175522 1;
BA_ "TpTxIndex" BO_ 2612224098 464619736;
BA_ "OvtpPushApplication" BO_ 2612224098 1;
BA_ "FrameRouting" BO_ 2612224098 "";
BA_ "NetworkInitialization" BO_ 2612224098 0;
BA_ "GenMsgDelayTime" BO_ 2612224098 0;
BA_ "GenMsgSendType" BO_ 2612224098 1;
BA_ "TpTxIndex" BO_ 2611175494 463542488;
BA_ "FrameRouting" BO_ 2611175494 "";
BA_ "NetworkInitialization" BO_ 2611175494 0;
BA_ "GenMsgDelayTime" BO_ 2611175494 0;
BA_ "GenMsgSendType" BO_ 2611175494 1;
BA_ "TpTxIndex" BO_ 2612224070 464591064;
BA_ "OvtpPushApplication" BO_ 2612224070 1;
BA_ "FrameRouting" BO_ 2612224070 "";
BA_ "NetworkInitialization" BO_ 2612224070 0;
BA_ "GenMsgDelayTime" BO_ 2612224070 0;
BA_ "GenMsgSendType" BO_ 2612224070 1;
BA_ "TpTxIndex" BO_ 2611175493 463541464;
BA_ "FrameRouting" BO_ 2611175493 "";
BA_ "NetworkInitialization" BO_ 2611175493 0;
BA_ "GenMsgDelayTime" BO_ 2611175493 0;
BA_ "GenMsgSendType" BO_ 2611175493 1;
BA_ "TpTxIndex" BO_ 2612224069 464590040;
BA_ "OvtpPushApplication" BO_ 2612224069 1;
BA_ "FrameRouting" BO_ 2612224069 "";
BA_ "NetworkInitialization" BO_ 2612224069 0;
BA_ "GenMsgDelayTime" BO_ 2612224069 0;
BA_ "GenMsgSendType" BO_ 2612224069 1;
BA_ "TpTxIndex" BO_ 2611175445 463492312;
BA_ "FrameRouting" BO_ 2611175445 "";
BA_ "NetworkInitialization" BO_ 2611175445 0;
BA_ "GenMsgDelayTime" BO_ 2611175445 0;
BA_ "GenMsgSendType" BO_ 2611175445 1;
BA_ "TpTxIndex" BO_ 2612224021 464540888;
BA_ "OvtpPushApplication" BO_ 2612224021 1;
BA_ "FrameRouting" BO_ 2612224021 "";
BA_ "NetworkInitialization" BO_ 2612224021 0;
BA_ "GenMsgDelayTime" BO_ 2612224021 0;
BA_ "GenMsgSendType" BO_ 2612224021 1;
BA_ "TpTxIndex" BO_ 2610126947 462523608;
BA_ "FrameRouting" BO_ 2610126947 "";
BA_ "NetworkInitialization" BO_ 2610126947 0;
BA_ "GenMsgDelayTime" BO_ 2610126947 0;
BA_ "GenMsgSendType" BO_ 2610126947 1;
BA_ "TpTxIndex" BO_ 2610126946 462522584;
BA_ "FrameRouting" BO_ 2610126946 "";
BA_ "NetworkInitialization" BO_ 2610126946 0;
BA_ "GenMsgDelayTime" BO_ 2610126946 0;
BA_ "GenMsgSendType" BO_ 2610126946 1;
BA_ "TpTxIndex" BO_ 2610126918 462493912;
BA_ "FrameRouting" BO_ 2610126918 "";
BA_ "NetworkInitialization" BO_ 2610126918 0;
BA_ "GenMsgDelayTime" BO_ 2610126918 0;
BA_ "GenMsgSendType" BO_ 2610126918 1;
BA_ "TpTxIndex" BO_ 2610126917 462492888;
BA_ "FrameRouting" BO_ 2610126917 "";
BA_ "NetworkInitialization" BO_ 2610126917 0;
BA_ "GenMsgDelayTime" BO_ 2610126917 0;
BA_ "GenMsgSendType" BO_ 2610126917 1;
BA_ "FrameRouting" BO_ 982 "";
BA_ "GenMsgSendType" BO_ 982 0;
BA_ "GenMsgCycleTime" BO_ 982 50;
BA_ "VFrameFormat" BO_ 982 14;
BA_ "FrameRouting" BO_ 1104 "";
BA_ "GenMsgCycleTime" BO_ 1104 200;
BA_ "GenMsgSendType" BO_ 1104 0;
BA_ "VFrameFormat" BO_ 1104 14;
BA_ "FrameRouting" BO_ 1085 "";
BA_ "GenMsgSendType" BO_ 1085 0;
BA_ "GenMsgCycleTime" BO_ 1085 50;
BA_ "VFrameFormat" BO_ 1085 14;
BA_ "FrameRouting" BO_ 865 "";
BA_ "FrameGatewayNetwork" BO_ 865 "HS1_CAN";
BA_ "FrameGatewayId" BO_ 865 865;
BA_ "VFrameFormat" BO_ 865 14;
BA_ "FrameRouting" BO_ 1445 "";
BA_ "GenMsgILSupport" BO_ 1445 0;
BA_ "NmAsrMessage" BO_ 1445 1;
BA_ "GenMsgSendType" BO_ 1445 0;
BA_ "GenMsgCycleTime" BO_ 1445 1000;
BA_ "NetworkInitialization" BO_ 1445 0;
BA_ "VFrameFormat" BO_ 1445 14;
BA_ "FrameRouting" BO_ 1088 "";
BA_ "GenMsgCycleTime" BO_ 1088 1000;
BA_ "GenMsgSendType" BO_ 1088 0;
BA_ "VFrameFormat" BO_ 1088 14;
BA_ "FrameRouting" BO_ 786 "";
BA_ "GenMsgCycleTime" BO_ 786 100;
BA_ "GenMsgSendType" BO_ 786 0;
BA_ "VFrameFormat" BO_ 786 14;
BA_ "FrameRouting" BO_ 66 "";
BA_ "FrameGatewayNetwork" BO_ 66 "HS1_CAN";
BA_ "FrameGatewayId" BO_ 66 66;
BA_ "VFrameFormat" BO_ 66 14;
BA_ "FrameRouting" BO_ 549 "";
BA_ "FrameGatewayId" BO_ 549 549;
BA_ "FrameGatewayNetwork" BO_ 549 "HS3_CAN";
BA_ "VFrameFormat" BO_ 549 14;
BA_ "FrameRouting" BO_ 611 "";
BA_ "GenMsgSendType" BO_ 611 0;
BA_ "GenMsgCycleTime" BO_ 611 100;
BA_ "VFrameFormat" BO_ 611 14;
BA_ "FrameRouting" BO_ 130 "";
BA_ "GenMsgSendType" BO_ 130 0;
BA_ "GenMsgCycleTime" BO_ 130 20;
BA_ "GenMsgDelayTime" BO_ 130 10;
BA_ "VFrameFormat" BO_ 130 14;
BA_ "FrameRouting" BO_ 126 "";
BA_ "GenMsgSendType" BO_ 126 0;
BA_ "GenMsgCycleTime" BO_ 126 10;
BA_ "GenMsgDelayTime" BO_ 126 0;
BA_ "VFrameFormat" BO_ 126 14;
BA_ "FrameRouting" BO_ 1200 "";
BA_ "GenMsgSendType" BO_ 1200 0;
BA_ "GenMsgCycleTime" BO_ 1200 20;
BA_ "GenMsgDelayTime" BO_ 1200 10;
BA_ "VFrameFormat" BO_ 1200 14;
BA_ "FrameRouting" BO_ 1046 "";
BA_ "GenMsgSendType" BO_ 1046 0;
BA_ "GenMsgCycleTime" BO_ 1046 100;
BA_ "VFrameFormat" BO_ 1046 14;
BA_ "FrameRouting" BO_ 1044 "";
BA_ "GenMsgSendType" BO_ 1044 0;
BA_ "GenMsgCycleTime" BO_ 1044 100;
BA_ "VFrameFormat" BO_ 1044 14;
BA_ "FrameRouting" BO_ 1042 "";
BA_ "GenMsgSendType" BO_ 1042 0;
BA_ "GenMsgCycleTime" BO_ 1042 50;
BA_ "VFrameFormat" BO_ 1042 14;
BA_ "FrameRouting" BO_ 534 "";
BA_ "GenMsgSendType" BO_ 534 0;
BA_ "GenMsgCycleTime" BO_ 534 20;
BA_ "GenMsgDelayTime" BO_ 534 10;
BA_ "VFrameFormat" BO_ 534 14;
BA_ "FrameRouting" BO_ 531 "";
BA_ "GenMsgSendType" BO_ 531 0;
BA_ "GenMsgCycleTime" BO_ 531 20;
BA_ "GenMsgDelayTime" BO_ 531 10;
BA_ "VFrameFormat" BO_ 531 14;
BA_ "FrameRouting" BO_ 1034 "";
BA_ "FrameGatewayId" BO_ 1034 1034;
BA_ "FrameGatewayNetwork" BO_ 1034 "HS1_CAN";
BA_ "VFrameFormat" BO_ 1034 14;
BA_ "FrameRouting" BO_ 1090 "";
BA_ "GenMsgSendType" BO_ 1090 0;
BA_ "GenMsgCycleTime" BO_ 1090 1000;
BA_ "VFrameFormat" BO_ 1090 14;
BA_ "FrameRouting" BO_ 869 "";
BA_ "GenMsgSendType" BO_ 869 0;
BA_ "GenMsgCycleTime" BO_ 869 100;
BA_ "VFrameFormat" BO_ 869 14;
BA_ "FrameRouting" BO_ 374 "";
BA_ "GenMsgSendType" BO_ 374 5;
BA_ "GenMsgCycleTime" BO_ 374 100;
BA_ "VFrameFormat" BO_ 374 14;
BA_ "FrameRouting" BO_ 603 "";
BA_ "GenMsgSendType" BO_ 603 0;
BA_ "GenMsgCycleTime" BO_ 603 20;
BA_ "GenMsgDelayTime" BO_ 603 10;
BA_ "VFrameFormat" BO_ 603 14;
BA_ "FrameRouting" BO_ 872 "";
BA_ "GenMsgSendType" BO_ 872 0;
BA_ "GenMsgCycleTime" BO_ 872 100;
BA_ "VFrameFormat" BO_ 872 14;
BA_ "FrameRouting" BO_ 560 "";
BA_ "GenMsgSendType" BO_ 560 0;
BA_ "GenMsgCycleTime" BO_ 560 20;
BA_ "GenMsgDelayTime" BO_ 560 10;
BA_ "VFrameFormat" BO_ 560 14;
BA_ "FrameRouting" BO_ 369 "";
BA_ "GenMsgSendType" BO_ 369 0;
BA_ "GenMsgCycleTime" BO_ 369 30;
BA_ "GenMsgDelayTime" BO_ 369 10;
BA_ "VFrameFormat" BO_ 369 14;
BA_ "FrameRouting" BO_ 92 "";
BA_ "GenMsgSendType" BO_ 92 5;
BA_ "GenMsgCycleTime" BO_ 92 100;
BA_ "VFrameFormat" BO_ 92 14;
BA_ "FrameRouting" BO_ 1087 "";
BA_ "GenMsgSendType" BO_ 1087 0;
BA_ "GenMsgCycleTime" BO_ 1087 100;
BA_ "VFrameFormat" BO_ 1087 14;
BA_ "FrameRouting" BO_ 1100 "";
BA_ "GenMsgSendType" BO_ 1100 0;
BA_ "GenMsgCycleTime" BO_ 1100 100;
BA_ "VFrameFormat" BO_ 1100 14;
BA_ "FrameRouting" BO_ 1086 "";
BA_ "GenMsgSendType" BO_ 1086 0;
BA_ "GenMsgCycleTime" BO_ 1086 100;
BA_ "VFrameFormat" BO_ 1086 14;
BA_ "FrameRouting" BO_ 1071 "";
BA_ "GenMsgSendType" BO_ 1071 0;
BA_ "GenMsgCycleTime" BO_ 1071 100;
BA_ "VFrameFormat" BO_ 1071 14;
BA_ "FrameRouting" BO_ 1069 "";
BA_ "GenMsgSendType" BO_ 1069 0;
BA_ "GenMsgCycleTime" BO_ 1069 100;
BA_ "VFrameFormat" BO_ 1069 14;
BA_ "FrameRouting" BO_ 1060 "";
BA_ "GenMsgSendType" BO_ 1060 0;
BA_ "GenMsgCycleTime" BO_ 1060 100;
BA_ "VFrameFormat" BO_ 1060 14;
BA_ "FrameRouting" BO_ 1057 "";
BA_ "GenMsgSendType" BO_ 1057 0;
BA_ "GenMsgCycleTime" BO_ 1057 100;
BA_ "VFrameFormat" BO_ 1057 14;
BA_ "FrameRouting" BO_ 562 "";
BA_ "GenMsgSendType" BO_ 562 0;
BA_ "GenMsgCycleTime" BO_ 562 100;
BA_ "VFrameFormat" BO_ 562 14;
BA_ "FrameRouting" BO_ 516 "";
BA_ "GenMsgSendType" BO_ 516 0;
BA_ "GenMsgCycleTime" BO_ 516 10;
BA_ "GenMsgDelayTime" BO_ 516 0;
BA_ "VFrameFormat" BO_ 516 14;
BA_ "FrameRouting" BO_ 514 "";
BA_ "GenMsgSendType" BO_ 514 0;
BA_ "GenMsgCycleTime" BO_ 514 20;
BA_ "GenMsgDelayTime" BO_ 514 10;
BA_ "VFrameFormat" BO_ 514 14;
BA_ "FrameRouting" BO_ 512 "";
BA_ "GenMsgSendType" BO_ 512 0;
BA_ "GenMsgCycleTime" BO_ 512 20;
BA_ "GenMsgDelayTime" BO_ 512 10;
BA_ "VFrameFormat" BO_ 512 14;
BA_ "FrameRouting" BO_ 380 "";
BA_ "GenMsgSendType" BO_ 380 0;
BA_ "GenMsgCycleTime" BO_ 380 100;
BA_ "VFrameFormat" BO_ 380 14;
BA_ "FrameRouting" BO_ 377 "";
BA_ "GenMsgSendType" BO_ 377 0;
BA_ "GenMsgCycleTime" BO_ 377 100;
BA_ "VFrameFormat" BO_ 377 14;
BA_ "FrameRouting" BO_ 376 "";
BA_ "GenMsgSendType" BO_ 376 0;
BA_ "GenMsgCycleTime" BO_ 376 100;
BA_ "VFrameFormat" BO_ 376 14;
BA_ "FrameRouting" BO_ 359 "";
BA_ "GenMsgSendType" BO_ 359 0;
BA_ "GenMsgCycleTime" BO_ 359 10;
BA_ "GenMsgDelayTime" BO_ 359 0;
BA_ "VFrameFormat" BO_ 359 14;
BA_ "FrameRouting" BO_ 358 "";
BA_ "GenMsgSendType" BO_ 358 0;
BA_ "GenMsgCycleTime" BO_ 358 100;
BA_ "VFrameFormat" BO_ 358 14;
BA_ "FrameRouting" BO_ 357 "";
BA_ "GenMsgSendType" BO_ 357 0;
BA_ "GenMsgCycleTime" BO_ 357 20;
BA_ "GenMsgDelayTime" BO_ 357 10;
BA_ "VFrameFormat" BO_ 357 14;
BA_ "FrameRouting" BO_ 342 "";
BA_ "GenMsgSendType" BO_ 342 0;
BA_ "GenMsgCycleTime" BO_ 342 100;
BA_ "VFrameFormat" BO_ 342 14;
BA_ "FrameRouting" BO_ 954 "";
BA_ "FrameGatewayId" BO_ 954 954;
BA_ "FrameGatewayNetwork" BO_ 954 "HS1_CAN";
BA_ "VFrameFormat" BO_ 954 14;
BA_ "FrameRouting" BO_ 935 "";
BA_ "GenMsgSendType" BO_ 935 5;
BA_ "GenMsgCycleTime" BO_ 935 200;
BA_ "VFrameFormat" BO_ 935 14;
BA_ "FrameRouting" BO_ 1041 "";
BA_ "FrameGatewayId" BO_ 1041 1041;
BA_ "FrameGatewayNetwork" BO_ 1041 "HS1_CAN";
BA_ "VFrameFormat" BO_ 1041 14;
BA_ "FrameRouting" BO_ 1112 "";
BA_ "FrameGatewayId" BO_ 1112 1112;
BA_ "FrameGatewayNetwork" BO_ 1112 "HS1_CAN";
BA_ "VFrameFormat" BO_ 1112 14;
BA_ "FrameRouting" BO_ 1050 "";
BA_ "FrameGatewayId" BO_ 1050 1050;
BA_ "FrameGatewayNetwork" BO_ 1050 "MS1_CAN";
BA_ "VFrameFormat" BO_ 1050 14;
BA_ "FrameRouting" BO_ 1009 "";
BA_ "FrameGatewayId" BO_ 1009 1009;
BA_ "FrameGatewayNetwork" BO_ 1009 "HS3_CAN";
BA_ "VFrameFormat" BO_ 1009 14;
BA_ "FrameRouting" BO_ 360 "";
BA_ "FrameGatewayId" BO_ 360 360;
BA_ "FrameGatewayNetwork" BO_ 360 "HS2_CAN";
BA_ "VFrameFormat" BO_ 360 14;
BA_ "FrameRouting" BO_ 90 "";
BA_ "FrameGatewayId" BO_ 90 90;
BA_ "FrameGatewayNetwork" BO_ 90 "HS2_CAN";
BA_ "VFrameFormat" BO_ 90 14;
BA_ "FrameRouting" BO_ 138 "";
BA_ "FrameGatewayId" BO_ 138 138;
BA_ "FrameGatewayNetwork" BO_ 138 "HS2_CAN";
BA_ "VFrameFormat" BO_ 138 14;
BA_ "FrameRouting" BO_ 1093 "";
BA_ "FrameGatewayId" BO_ 1093 1093;
BA_ "FrameGatewayNetwork" BO_ 1093 "HS3_CAN";
BA_ "VFrameFormat" BO_ 1093 14;
BA_ "FrameRouting" BO_ 792 "";
BA_ "FrameGatewayId" BO_ 792 792;
BA_ "FrameGatewayNetwork" BO_ 792 "HS3_CAN";
BA_ "VFrameFormat" BO_ 792 14;
BA_ "FrameRouting" BO_ 765 "";
BA_ "FrameGatewayId" BO_ 765 765;
BA_ "FrameGatewayNetwork" BO_ 765 "HS3_CAN";
BA_ "VFrameFormat" BO_ 765 14;
BA_ "FrameRouting" BO_ 934 "";
BA_ "GenMsgSendType" BO_ 934 5;
BA_ "GenMsgCycleTime" BO_ 934 200;
BA_ "VFrameFormat" BO_ 934 14;
BA_ "FrameRouting" BO_ 1072 "";
BA_ "FrameGatewayId" BO_ 1072 1072;
BA_ "FrameGatewayNetwork" BO_ 1072 "HS3_CAN";
BA_ "VFrameFormat" BO_ 1072 14;
BA_ "FrameRouting" BO_ 145 "";
BA_ "FrameGatewayId" BO_ 145 145;
BA_ "FrameGatewayNetwork" BO_ 145 "HS2_CAN";
BA_ "VFrameFormat" BO_ 145 14;
BA_ "FrameRouting" BO_ 931 "";
BA_ "FrameGatewayId" BO_ 931 931;
BA_ "FrameGatewayNetwork" BO_ 931 "HS1_CAN";
BA_ "VFrameFormat" BO_ 931 14;
BA_ "FrameRouting" BO_ 947 "";
BA_ "FrameGatewayId" BO_ 947 947;
BA_ "FrameGatewayNetwork" BO_ 947 "HS1_CAN";
BA_ "VFrameFormat" BO_ 947 14;
BA_ "FrameRouting" BO_ 394 "";
BA_ "GenMsgSendType" BO_ 394 5;
BA_ "GenMsgCycleTime" BO_ 394 200;
BA_ "VFrameFormat" BO_ 394 14;
BA_ "FrameRouting" BO_ 391 "";
BA_ "GenMsgSendType" BO_ 391 0;
BA_ "GenMsgCycleTime" BO_ 391 20;
BA_ "GenMsgDelayTime" BO_ 391 10;
BA_ "VFrameFormat" BO_ 391 14;
BA_ "FrameRouting" BO_ 390 "";
BA_ "GenMsgSendType" BO_ 390 0;
BA_ "GenMsgCycleTime" BO_ 390 20;
BA_ "GenMsgDelayTime" BO_ 390 10;
BA_ "VFrameFormat" BO_ 390 14;
BA_ "FrameRouting" BO_ 942 "";
BA_ "GenMsgSendType" BO_ 942 5;
BA_ "GenMsgCycleTime" BO_ 942 1000;
BA_ "VFrameFormat" BO_ 942 14;
BA_ "GenSigSendType" SG_ 823 DteVehPwId_No_Actl 3;
BA_ "ECGUsedRxSignal" SG_ 823 DteVehPwId_No_Actl 1;
BA_ "ECGUsedRxSignal" SG_ 823 DteVehEId_No_Actl 1;
BA_ "ECGUsedRxSignal" SG_ 823 DteVehEffId_No_Actl 1;
BA_ "ECGUsedRxSignal" SG_ 823 DteVeh_Pw_Actl 1;
BA_ "GenSigStartValue" SG_ 823 DteVeh_Eff_Actl 100;
BA_ "ECGUsedRxSignal" SG_ 823 DteVeh_Eff_Actl 1;
BA_ "ECGUsedRxSignal" SG_ 823 DteVeh_E_Actl 1;
BA_ "GenSigSendType" SG_ 823 DteAcceptNew_B_Rq 3;
BA_ "ECGUsedRxSignal" SG_ 823 DteAcceptNew_B_Rq 1;
BA_ "GenSigSendType" SG_ 824 DteCldTrlrOn_B_Stat 3;
BA_ "ECGUsedTxSignal" SG_ 824 DteCldTrlrOn_B_Stat 1;
BA_ "GenSigSendType" SG_ 824 DteCldTrlrOff_B_Stat 3;
BA_ "ECGUsedTxSignal" SG_ 824 DteCldTrlrOff_B_Stat 1;
BA_ "GenSigStartValue" SG_ 824 DteCldTrip_L_Actl 100;
BA_ "ECGUsedTxSignal" SG_ 824 DteCldTrip_L_Actl 1;
BA_ "GenSigSendType" SG_ 824 DteCldTraffic_B_Stat 3;
BA_ "ECGUsedTxSignal" SG_ 824 DteCldTraffic_B_Stat 1;
BA_ "GenSigSendType" SG_ 824 DteCldTerrain_B_Stat 3;
BA_ "ECGUsedTxSignal" SG_ 824 DteCldTerrain_B_Stat 1;
BA_ "GenSigSendType" SG_ 824 DteCldRoute_B_Stat 3;
BA_ "ECGUsedTxSignal" SG_ 824 DteCldRoute_B_Stat 1;
BA_ "GenSigSendType" SG_ 824 DteCldPayload_B_Stat 3;
BA_ "ECGUsedTxSignal" SG_ 824 DteCldPayload_B_Stat 1;
BA_ "GenSigSendType" SG_ 824 DteCldId_No_Actl 3;
BA_ "ECGUsedTxSignal" SG_ 824 DteCldId_No_Actl 1;
BA_ "GenSigSendType" SG_ 824 DteCldExtTe_B_Stat 3;
BA_ "ECGUsedTxSignal" SG_ 824 DteCldExtTe_B_Stat 1;
BA_ "GenSigStartValue" SG_ 824 DteCldExt_Eff_Actl 100;
BA_ "ECGUsedTxSignal" SG_ 824 DteCldExt_Eff_Actl 1;
BA_ "GenSigStartValue" SG_ 824 DteCldDrv_Eff_Actl 100;
BA_ "ECGUsedTxSignal" SG_ 824 DteCldDrv_Eff_Actl 1;
BA_ "GenSigSendType" SG_ 824 DteCldDcac_B_Stat 3;
BA_ "ECGUsedTxSignal" SG_ 824 DteCldDcac_B_Stat 1;
BA_ "GenSigStartValue" SG_ 824 DteCldClimt_Eff_Actl 100;
BA_ "ECGUsedTxSignal" SG_ 824 DteCldClimt_Eff_Actl 1;
BA_ "GenSigStartValue" SG_ 824 DteCldBattULo_Eff_Actl 100;
BA_ "ECGUsedTxSignal" SG_ 824 DteCldBattULo_Eff_Actl 1;
BA_ "GenSigStartValueInteger" SG_ 949 Tire_Press_RR_ORR_Data 65533;
BA_ "GenSigStartValue" SG_ 949 Tire_Press_RR_ORR_Data 65533;
BA_ "GenSigStartValueInteger" SG_ 949 Tire_Press_LR_OLR_Data 65533;
BA_ "GenSigStartValue" SG_ 949 Tire_Press_LR_OLR_Data 65533;
BA_ "GenSigStartValueInteger" SG_ 949 Tire_Press_LF_Data 65533;
BA_ "GenSigStartValue" SG_ 949 Tire_Press_LF_Data 65533;
BA_ "GenSigStartValueInteger" SG_ 949 Tire_Press_RF_Data 65533;
BA_ "GenSigStartValue" SG_ 949 Tire_Press_RF_Data 65533;
BA_ "GenSigSendType" SG_ 1825 TesterPhysicalReqVDM 3;
BA_ "U_T6_MCA_MY2020_Tx" SG_ 524 PrplWhlTotTqRqMxAwd_No_Cs 1;
BA_ "U_T6_MCA_MY2020_Rx" SG_ 524 PrplWhlTotTqRqMxAwd_No_Cs 1;
BA_ "MetaData" SG_ 524 PrplWhlTotTqRqMxAwd_No_Cs 1;
BA_ "ContentDependant" SG_ 524 PrplWhlTotTqRqMxAwd_No_Cs 1;
BA_ "U_T6_MCA_MY2020_Tx" SG_ 524 PrplWhlTot_Tq_RqMxAwd 1;
BA_ "U_T6_MCA_MY2020_Rx" SG_ 524 PrplWhlTot_Tq_RqMxAwd 1;
BA_ "GenSigStartValue" SG_ 524 PrplWhlTot_Tq_RqMxAwd 65535;
BA_ "GenSigStartValueInteger" SG_ 524 PrplWhlTot_Tq_RqMxAwd 65535;
BA_ "U_T6_MCA_MY2020_Tx" SG_ 524 PrplWhlTotTqRqMxAwd_No_Cnt 1;
BA_ "U_T6_MCA_MY2020_Rx" SG_ 524 PrplWhlTotTqRqMxAwd_No_Cnt 1;
BA_ "MetaData" SG_ 524 PrplWhlTotTqRqMxAwd_No_Cnt 1;
BA_ "ContentDependant" SG_ 524 PrplWhlTotTqRqMxAwd_No_Cnt 1;
BA_ "U_CX727_MY2021_Rx" SG_ 740 BattAuxCnnct_B_Cmd 1;
BA_ "GenSigSendType" SG_ 1160 DgtlCommPncReset_B_Req 3;
BA_ "ECGUsedTxSignal" SG_ 1160 DgtlCommPncReset_B_Req 1;
BA_ "ECGUsedTxSignal" SG_ 1160 DataMntrSustn_B_Rq 1;
BA_ "GenSigSendType" SG_ 1160 DataMntrSustn_B_Rq 3;
BA_ "ECGUsedTxSignal" SG_ 1160 PwSustnRdata_B_RqTelem 1;
BA_ "GenSigSendType" SG_ 1160 PwSustnRdata_B_RqTelem 3;
BA_ "ECGUsedTxSignal" SG_ 776 ScMnSoc_Pc_RqCld 1;
BA_ "GenSigStartValue" SG_ 776 ScMnSoc_Pc_RqCld 100;
BA_ "GenSigSendType" SG_ 776 ScMnSoc_Pc_RqCld 3;
BA_ "ECGUsedTxSignal" SG_ 776 ScChrgrPwMax_Pw_RqCld 1;
BA_ "GenSigSendType" SG_ 776 ScChrgrPwMax_Pw_RqCld 3;
BA_ "ECGUsedTxSignal" SG_ 776 ScLocPwId_No_RqCld 1;
BA_ "GenSigSendType" SG_ 776 ScLocPwId_No_RqCld 3;
BA_ "ECGUsedTxSignal" SG_ 776 PrcondEdit_D_RqCld 1;
BA_ "GenSigSendType" SG_ 776 PrcondEdit_D_RqCld 3;
BA_ "ECGUsedTxSignal" SG_ 776 GoTEditMnte_T_RqCld 1;
BA_ "GenSigStartValue" SG_ 776 GoTEditMnte_T_RqCld 14;
BA_ "GenSigSendType" SG_ 776 GoTEditMnte_T_RqCld 3;
BA_ "ECGUsedTxSignal" SG_ 776 GoTEditHr_T_RqCld 1;
BA_ "GenSigStartValue" SG_ 776 GoTEditHr_T_RqCld 30;
BA_ "GenSigSendType" SG_ 776 GoTEditHr_T_RqCld 3;
BA_ "ECGUsedTxSignal" SG_ 776 ChrgToPcEdit_Pc_RqCld 1;
BA_ "GenSigStartValue" SG_ 776 ChrgToPcEdit_Pc_RqCld 126;
BA_ "GenSigSendType" SG_ 776 ChrgToPcEdit_Pc_RqCld 3;
BA_ "ECGUsedTxSignal" SG_ 776 AirAmb_Te_ActlCld 1;
BA_ "GenSigStartValueInteger" SG_ 776 AirAmb_Te_ActlCld 512;
BA_ "GenSigSendType" SG_ 776 AirAmb_Te_ActlCld 3;
BA_ "ECGUsedTxSignal" SG_ 776 ScFreshDataEnbl_B_Rq 1;
BA_ "GenSigSendType" SG_ 776 ScFreshDataEnbl_B_Rq 3;
BA_ "ECGUsedTxSignal" SG_ 776 ScEnbl_D_RqCld 1;
BA_ "GenSigStartValue" SG_ 776 ScEnbl_D_RqCld 1;
BA_ "GenSigSendType" SG_ 776 ScEnbl_D_RqCld 3;
BA_ "ECGUsedTxSignal" SG_ 775 ScDayOfWeekId_D_RqCld 1;
BA_ "GenSigStartValue" SG_ 775 ScDayOfWeekId_D_RqCld 1;
BA_ "GenSigSendType" SG_ 775 ScDayOfWeekId_D_RqCld 3;
BA_ "ECGUsedTxSignal" SG_ 775 ScLocSetId_No_RqCld 1;
BA_ "GenSigSendType" SG_ 775 ScLocSetId_No_RqCld 3;
BA_ "ECGUsedTxSignal" SG_ 775 ScLocRdius_L_RqCld 1;
BA_ "GenSigStartValue" SG_ 775 ScLocRdius_L_RqCld 1;
BA_ "GenSigSendType" SG_ 775 ScLocRdius_L_RqCld 3;
BA_ "ECGUsedTxSignal" SG_ 775 ScChrgToPc_Pc_RqCld 1;
BA_ "GenSigStartValue" SG_ 775 ScChrgToPc_Pc_RqCld 100;
BA_ "GenSigSendType" SG_ 775 ScChrgToPc_Pc_RqCld 3;
BA_ "ECGUsedTxSignal" SG_ 775 ScChrgPrfl_No_RqCld 1;
BA_ "GenSigSendType" SG_ 775 ScChrgPrfl_No_RqCld 3;
BA_ "ECGUsedTxSignal" SG_ 775 ScChrgDurSet_D_RqCld 1;
BA_ "GenSigStartValue" SG_ 775 ScChrgDurSet_D_RqCld 1;
BA_ "GenSigSendType" SG_ 775 ScChrgDurSet_D_RqCld 3;
BA_ "ECGUsedTxSignal" SG_ 775 ScChrgDur_T_RqCld 1;
BA_ "GenSigSendType" SG_ 775 ScChrgDur_T_RqCld 3;
BA_ "ECGUsedTxSignal" SG_ 774 ScLocLongPostv_B_RqCld 1;
BA_ "GenSigSendType" SG_ 774 ScLocLongPostv_B_RqCld 3;
BA_ "ECGUsedTxSignal" SG_ 774 ScLocLongFrct_An_RqCld 1;
BA_ "GenSigStartValue" SG_ 774 ScLocLongFrct_An_RqCld 1048575;
BA_ "GenSigSendType" SG_ 774 ScLocLongFrct_An_RqCld 3;
BA_ "ECGUsedTxSignal" SG_ 774 ScLocLongDeg_An_RqCld 1;
BA_ "GenSigSendType" SG_ 774 ScLocLongDeg_An_RqCld 3;
BA_ "ECGUsedTxSignal" SG_ 774 ScLocLattPostv_B_RqCld 1;
BA_ "GenSigSendType" SG_ 774 ScLocLattPostv_B_RqCld 3;
BA_ "ECGUsedTxSignal" SG_ 774 ScLocLattFrct_An_RqCld 1;
BA_ "GenSigStartValue" SG_ 774 ScLocLattFrct_An_RqCld 1048575;
BA_ "GenSigSendType" SG_ 774 ScLocLattFrct_An_RqCld 3;
BA_ "ECGUsedTxSignal" SG_ 774 ScLocLattDeg_An_RqCld 1;
BA_ "GenSigSendType" SG_ 774 ScLocLattDeg_An_RqCld 3;
BA_ "ECGUsedTxSignal" SG_ 774 ScLocId_No_RqCld 1;
BA_ "GenSigSendType" SG_ 774 ScLocId_No_RqCld 3;
BA_ "ECGUsedTxSignal" SG_ 774 ScLocDelete_B_RqCld 1;
BA_ "GenSigSendType" SG_ 774 ScLocDelete_B_RqCld 3;
BA_ "GenSigStartValue" SG_ 811 DistToStopover_L_Actl 65535;
BA_ "WakeupSignal" SG_ 811 ExtLghtRight_D_RqMnu 1;
BA_ "WakeupSignal" SG_ 811 AutoLghtOvrrd_B_RqDrv 1;
BA_ "WakeupSignal" SG_ 811 ExtLghtRear_D_RqMnu 1;
BA_ "WakeupSignal" SG_ 811 ExtLghtLeft_D_RqMnu 1;
BA_ "WakeupSignal" SG_ 811 ExtLghtFront_D_RqMnu 1;
BA_ "GenSigStartValue" SG_ 811 GoTEditMnte_T_RqMnu 14;
BA_ "GenSigStartValue" SG_ 811 GoTEditHr_T_RqMnu 30;
BA_ "U_CX727_MY2021_Tx" SG_ 850 VehElRngeNut_L_Dsply 1;
BA_ "U_CX727_MY2021_Tx" SG_ 850 NxtUsgSocEst_Pc_Dsply 1;
BA_ "ECGUsedRxSignal" SG_ 850 EstmChrgTimeLP_St 1;
BA_ "U_CX727_MY2021_Tx" SG_ 850 EstmChrgTimeLP_St 1;
BA_ "ECGUsedRxSignal" SG_ 850 EstmChrgTimeHP_St 1;
BA_ "U_CX727_MY2021_Tx" SG_ 850 EstmChrgTimeHP_St 1;
BA_ "ECGUsedRxSignal" SG_ 850 ChargeNowDuration_St 1;
BA_ "U_CX727_MY2021_Tx" SG_ 850 ChargeNowDuration_St 1;
BA_ "ECGUsedTxSignal" SG_ 563 DrvBhavWarn_B_Rq 1;
BA_ "GenSigSendType" SG_ 563 DrvBhavWarn_B_Rq 3;
BA_ "ECGUsedTxSignal" SG_ 563 OfbChrgSetSync_D_Rq 1;
BA_ "ECGUsedTxSignal" SG_ 563 KeyOffPwMde_D_Stat 1;
BA_ "GenSigSendType" SG_ 563 KeyOffPwMde_D_Stat 3;
BA_ "ECGUsedTxSignal" SG_ 563 ModemReset_D_Stat 1;
BA_ "GenSigSendType" SG_ 563 ModemReset_D_Stat 3;
BA_ "ECGUsedTxSignal" SG_ 563 FactoryReset_St 1;
BA_ "GenSigSendType" SG_ 563 FactoryReset_St 3;
BA_ "GenSigSendType" SG_ 1833 TesterPhysicalResVDM 3;
BA_ "GenSigStartValueInteger" SG_ 570 SuspRearRight_L_Actl 511;
BA_ "GenSigStartValue" SG_ 570 SuspRearRight_L_Actl 511;
BA_ "U_CX727_MY2021_Rx" SG_ 570 SuspRearRight_L_Actl 1;
BA_ "GenSigStartValueInteger" SG_ 570 SuspFrntRight_L_Actl 511;
BA_ "GenSigStartValue" SG_ 570 SuspFrntRight_L_Actl 511;
BA_ "U_CX727_MY2021_Rx" SG_ 570 SuspFrntRight_L_Actl 1;
BA_ "GenSigStartValueInteger" SG_ 570 SuspRear_L_Prev 511;
BA_ "GenSigStartValue" SG_ 570 SuspRear_L_Prev 511;
BA_ "U_CX727_MY2021_Rx" SG_ 570 SuspRear_L_Prev 1;
BA_ "U_P702_MY2021_Rx" SG_ 570 SuspRear_L_Prev 1;
BA_ "GenSigStartValueInteger" SG_ 570 SuspRear_L_Actl 511;
BA_ "GenSigStartValue" SG_ 570 SuspRear_L_Actl 511;
BA_ "U_CX727_MY2021_Rx" SG_ 570 SuspRear_L_Actl 1;
BA_ "U_P702_MY2021_Rx" SG_ 570 SuspRear_L_Actl 1;
BA_ "GenSigStartValueInteger" SG_ 570 SuspFrnt_L_Prev 511;
BA_ "GenSigStartValue" SG_ 570 SuspFrnt_L_Prev 511;
BA_ "U_CX727_MY2021_Rx" SG_ 570 SuspFrnt_L_Prev 1;
BA_ "U_P702_MY2021_Rx" SG_ 570 SuspFrnt_L_Prev 1;
BA_ "GenSigStartValueInteger" SG_ 570 SuspFrnt_L_Actl 511;
BA_ "GenSigStartValue" SG_ 570 SuspFrnt_L_Actl 511;
BA_ "U_CX727_MY2021_Rx" SG_ 570 SuspFrnt_L_Actl 1;
BA_ "U_P702_MY2021_Rx" SG_ 570 SuspFrnt_L_Actl 1;
BA_ "GenSigSendType" SG_ 837 Ccd_B_Falt 3;
BA_ "GenSigSendType" SG_ 837 SelDrvMdeSusp_D_Stat 3;
BA_ "U_CX727_MY2021_Rx" SG_ 837 SelDrvMdeSusp_D_Stat 1;
BA_ "U_P702_MY2021_Rx" SG_ 837 SelDrvMdeSusp_D_Stat 1;
BA_ "U_T6_MCA_MY2020_Rx" SG_ 837 SelDrvMdeSusp_D_Stat 1;
BA_ "GenSigSendType" SG_ 837 AdptDrvMdePt_D_Rq 3;
BA_ "U_CX727_MY2021_Rx" SG_ 837 AdptDrvMdePt_D_Rq 1;
BA_ "U_P702_MY2021_Rx" SG_ 837 AdptDrvMdePt_D_Rq 1;
BA_ "U_T6_MCA_MY2020_Rx" SG_ 837 AdptDrvMdePt_D_Rq 1;
BA_ "GenSigSendType" SG_ 837 AdptDrvMdeChassis_D_Rq 3;
BA_ "U_CX727_MY2021_Rx" SG_ 837 AdptDrvMdeChassis_D_Rq 1;
BA_ "U_P702_MY2021_Rx" SG_ 837 AdptDrvMdeChassis_D_Rq 1;
BA_ "U_T6_MCA_MY2020_Rx" SG_ 837 AdptDrvMdeChassis_D_Rq 1;
BA_ "GenSigSendType" SG_ 837 CcdMsgTxt_D_RqDsply 3;
BA_ "U_P702_MY2021_Rx" SG_ 837 CcdMsgTxt_D_RqDsply 1;
BA_ "ECGUsedTxSignal" SG_ 885 BattULoChrg_D_RqOta 1;
BA_ "ECGUsedTxSignal" SG_ 885 VehStrtInhbt_T_Dsply 1;
BA_ "ECGUsedTxSignal" SG_ 885 VehStrtInhbt_D_Dsply 1;
BA_ "ECGUsedTxSignal" SG_ 885 VehOnRqstr_D_Stat 1;
BA_ "ECGUsedTxSignal" SG_ 885 VehStrtInhbt_D_RqCld 1;
BA_ "ECGUsedTxSignal" SG_ 885 VehOn_D_RqCld 1;
BA_ "ECGUsedTxSignal" SG_ 885 CanMsg375_No_Cnt 1;
BA_ "ECGUsedTxSignal" SG_ 885 CanMsg375_No_Crc 1;
BA_ "ECGUsedTxSignal" SG_ 885 OtaActv_D_Stat 1;
BA_ "U_CX727_MY2021_Rx" SG_ 1150 LocationServices_1 1;
BA_ "GenSigSendType" SG_ 2612224016 PARSEDPushPCMtoGWM_ECG 3;
BA_ "U_P702_MY2021_Tx" SG_ 2612224016 PARSEDPushPCMtoGWM_ECG 1;
BA_ "U_T6_MCA_MY2020_Tx" SG_ 2612224016 PARSEDPushPCMtoGWM_ECG 1;
BA_ "ECGUsedRxSignal" SG_ 2612224016 PARSEDPushPCMtoGWM_ECG 1;
BA_ "GenSigSendType" SG_ 810 OBCCSerial_D_Rq 3;
BA_ "ECGUsedTxSignal" SG_ 810 OBCCSerial_D_Rq 1;
BA_ "ECGUsedTxSignal" SG_ 810 TlghtTest_D_RqArb 1;
BA_ "GenSigSendType" SG_ 810 TlghtTest_D_RqArb 3;
BA_ "ECGUsedTxSignal" SG_ 810 ChrgrPncSustn_B_Rq 1;
BA_ "GenSigStartValueInteger" SG_ 810 ChrgrPncSustn_B_Rq 3;
BA_ "ECGUsedTxSignal" SG_ 810 NtfyDrvTrgtDist_L_Rq 1;
BA_ "GenSigStartValue" SG_ 810 NtfyDrvTrgtDist_L_Rq 1;
BA_ "GenSigStartValueInteger" SG_ 810 NtfyDrvTrgtDist_L_Rq 1;
BA_ "WakeupSignal" SG_ 810 NtfyDrvTrgtDist_L_Rq 1;
BA_ "GenSigSendType" SG_ 810 NtfyDrvTrgtDist_L_Rq 3;
BA_ "ECGUsedTxSignal" SG_ 810 NtfyDrvSocLvl1_Pc_Rq 1;
BA_ "GenSigStartValue" SG_ 810 NtfyDrvSocLvl1_Pc_Rq 1;
BA_ "GenSigStartValueInteger" SG_ 810 NtfyDrvSocLvl1_Pc_Rq 1;
BA_ "WakeupSignal" SG_ 810 NtfyDrvSocLvl1_Pc_Rq 1;
BA_ "GenSigSendType" SG_ 810 NtfyDrvSocLvl1_Pc_Rq 3;
BA_ "ECGUsedTxSignal" SG_ 810 PtRmtRprt_D_Stat 1;
BA_ "WakeupSignal" SG_ 810 PtRmtRprt_D_Stat 1;
BA_ "GenSigSendType" SG_ 810 PtRmtRprt_D_Stat 3;
BA_ "ECGUsedTxSignal" SG_ 810 ChrgrPncEnbl_D_Rq 1;
BA_ "GenSigStartValue" SG_ 810 ChrgrPncEnbl_D_Rq 3;
BA_ "GenSigStartValueInteger" SG_ 810 ChrgrPncEnbl_D_Rq 3;
BA_ "GenSigSendType" SG_ 810 ChrgrPncEnbl_D_Rq 3;
BA_ "ECGUsedTxSignal" SG_ 810 ExtLghtDsply_B_StatArb 1;
BA_ "WakeupSignal" SG_ 810 ExtLghtDsply_B_StatArb 1;
BA_ "GenSigSendType" SG_ 810 ExtLghtDsply_B_StatArb 3;
BA_ "ECGUsedTxSignal" SG_ 810 ExtLghtRight_D_RqOta 1;
BA_ "WakeupSignal" SG_ 810 ExtLghtRight_D_RqOta 1;
BA_ "GenSigSendType" SG_ 810 ExtLghtRight_D_RqOta 3;
BA_ "ECGUsedTxSignal" SG_ 810 ExtLghtRear_D_RqOta 1;
BA_ "WakeupSignal" SG_ 810 ExtLghtRear_D_RqOta 1;
BA_ "GenSigSendType" SG_ 810 ExtLghtRear_D_RqOta 3;
BA_ "ECGUsedTxSignal" SG_ 810 ExtLghtLeft_D_RqOta 1;
BA_ "WakeupSignal" SG_ 810 ExtLghtLeft_D_RqOta 1;
BA_ "GenSigSendType" SG_ 810 ExtLghtLeft_D_RqOta 3;
BA_ "ECGUsedTxSignal" SG_ 810 ExtLghtFront_D_RqOta 1;
BA_ "WakeupSignal" SG_ 810 ExtLghtFront_D_RqOta 1;
BA_ "GenSigSendType" SG_ 810 ExtLghtFront_D_RqOta 3;
BA_ "ECGUsedTxSignal" SG_ 550 PtWakeupActv1_B_Rq 1;
BA_ "WakeupSignal" SG_ 550 PtWakeupActv1_B_Rq 1;
BA_ "GenSigSendType" SG_ 550 PtWakeupActv1_B_Rq 3;
BA_ "ECGUsedTxSignal" SG_ 639 OfbChrgPrflUpdate_B_Rq 1;
BA_ "GenSigSendType" SG_ 639 OfbChrgPrflUpdate_B_Rq 3;
BA_ "ECGUsedTxSignal" SG_ 639 OfbChrgClearAll_B_Rq 1;
BA_ "GenSigSendType" SG_ 639 OfbChrgClearAll_B_Rq 3;
BA_ "ECGUsedTxSignal" SG_ 639 OfbChrgGoTTouch_D_Rq 1;
BA_ "GenSigSendType" SG_ 639 OfbChrgGoTTouch_D_Rq 3;
BA_ "ECGUsedTxSignal" SG_ 639 OfbChrgGoTPrcond_D_Rq 1;
BA_ "ECGUsedTxSignal" SG_ 639 OfbChrgGoTOn_D_Rq 1;
BA_ "GenSigStartValue" SG_ 639 OfbChrgGoTOn_D_Rq 2;
BA_ "GenSigStartValueInteger" SG_ 639 OfbChrgGoTOn_D_Rq 2;
BA_ "GenSigSendType" SG_ 639 OfbChrgGoTOn_D_Rq 3;
BA_ "ECGUsedTxSignal" SG_ 639 OfbChrgGoTMnte_D_Rq 1;
BA_ "MetaData" SG_ 639 OfbChrgGoTMnte_D_Rq 1;
BA_ "ECGUsedTxSignal" SG_ 639 OfbChrgGoTHr_T_Rq 1;
BA_ "GenSigStartValue" SG_ 639 OfbChrgGoTHr_T_Rq 30;
BA_ "GenSigStartValueInteger" SG_ 639 OfbChrgGoTHr_T_Rq 30;
BA_ "ECGUsedTxSignal" SG_ 639 OfbChrgGoTExtHtr_D_Rq 1;
BA_ "GenSigSendType" SG_ 639 OfbChrgGoTExtHtr_D_Rq 3;
BA_ "ECGUsedTxSignal" SG_ 639 OfbChrgGoTElement_D_Rq 1;
BA_ "MetaData" SG_ 639 OfbChrgGoTElement_D_Rq 1;
BA_ "GenSigSendType" SG_ 639 OfbChrgGoTElement_D_Rq 3;
BA_ "ECGUsedTxSignal" SG_ 639 OfbChrgGoTDelete_B_Rq 1;
BA_ "ECGUsedTxSignal" SG_ 639 OfbChrgGoTUpdate_B_Rq 1;
BA_ "GenSigSendType" SG_ 639 OfbChrgGoTUpdate_B_Rq 3;
BA_ "ECGUsedTxSignal" SG_ 530 OfbChrgLocIdTrgt_No_Rq 1;
BA_ "MetaData" SG_ 530 OfbChrgLocIdTrgt_No_Rq 1;
BA_ "GenSigSendType" SG_ 530 OfbChrgLocIdTrgt_No_Rq 3;
BA_ "ECGUsedTxSignal" SG_ 530 OfbChrgToPcWknd_D_Actl 1;
BA_ "ECGUsedTxSignal" SG_ 530 OfbChrgToPcWkdy_D_Actl 1;
BA_ "ECGUsedTxSignal" SG_ 530 OfbChrgSetNow_D_Rq 1;
BA_ "ECGUsedTxSignal" SG_ 530 OfbChrgSetDelete_B_Rq 1;
BA_ "ECGUsedTxSignal" SG_ 530 OfbChrgPrflWknd_No_Rq 1;
BA_ "ECGUsedTxSignal" SG_ 530 OfbChrgPrflWkdy_No_Rq 1;
BA_ "ECGUsedTxSignal" SG_ 530 OfbChrgLocIdUns_B_Rq 1;
BA_ "ECGUsedRxSignal" SG_ 1142 ConsTipV_No_Dsply 1;
BA_ "U_CX727_MY2021_Tx" SG_ 1142 ConsTipV_No_Dsply 1;
BA_ "WakeupSignal" SG_ 817 DrTgateOpen_B_Rq 1;
BA_ "WakeupSignal" SG_ 817 DrTgateExtSwMde_B_Stat 1;
BA_ "WakeupSignal" SG_ 817 Remote_Device_Feedback 1;
BA_ "WakeupSignal" SG_ 817 Veh_Lock_Requestor 1;
BA_ "WakeupSignal" SG_ 817 R_Pwr_Sliding_Dr_Rqst 1;
BA_ "WakeupSignal" SG_ 817 Power_Liftgate_Rqst 1;
BA_ "WakeupSignal" SG_ 817 Veh_Lock_EvNum 1;
BA_ "WakeupSignal" SG_ 817 Power_Decklid_Rqst 1;
BA_ "WakeupSignal" SG_ 817 L_Pwr_Sliding_Dr_Rqst 1;
BA_ "WakeupSignal" SG_ 817 Keyfob_Pad_Msg_Count 1;
BA_ "WakeupSignal" SG_ 817 Veh_Lock_Status 1;
BA_ "GenSigStartValueInteger" SG_ 817 Veh_Lock_Status 1;
BA_ "GenSigStartValue" SG_ 817 Veh_Lock_Status 1;
BA_ "WakeupSignal" SG_ 817 ChildLck_D_Dsply 1;
BA_ "GenSigStartValueInteger" SG_ 817 ChildLck_D_Dsply 1;
BA_ "GenSigStartValue" SG_ 817 ChildLck_D_Dsply 1;
BA_ "WakeupSignal" SG_ 817 Lockmsgtxt_D_Rq 1;
BA_ "WakeupSignal" SG_ 817 LockInhibit 1;
BA_ "GenSigSendType" SG_ 878 DcacGfciTest_B_Rq 3;
BA_ "GenSigSendType" SG_ 878 DcacHw_D_Confg 3;
BA_ "GenSigStartValueInteger" SG_ 878 DcacHw_D_Confg 1;
BA_ "GenSigStartValue" SG_ 878 DcacHw_D_Confg 1;
BA_ "GenSigSendType" SG_ 878 DcacFaltMsgTxt_D_Rq 3;
BA_ "GenSigStartValueInteger" SG_ 878 DcacFaltMsgTxt_D_Rq 1;
BA_ "GenSigStartValue" SG_ 878 DcacFaltMsgTxt_D_Rq 1;
BA_ "GenSigSendType" SG_ 878 DcacLoFuelMsgTxt_D_Rq 3;
BA_ "GenSigSendType" SG_ 878 DcacEngOnMsgTxt_D_Rq 3;
BA_ "GenSigSendType" SG_ 878 DcacElPw_D_Stat 3;
BA_ "GenSigStartValueInteger" SG_ 878 DcacElPw_D_Stat 1;
BA_ "GenSigStartValue" SG_ 878 DcacElPw_D_Stat 1;
BA_ "GenSigSendType" SG_ 878 PwBedPnlEnbl_B_Rq 3;
BA_ "GenSigSendType" SG_ 878 DcacOn_B_Rq 3;
BA_ "U_P702_MY2021_Tx" SG_ 878 DcacOn_B_Rq 1;
BA_ "GenSigSendType" SG_ 878 DcacSys_B_Falt 3;
BA_ "U_P702_MY2021_Tx" SG_ 878 DcacSys_B_Falt 1;
BA_ "GenSigSendType" SG_ 878 DcacLedCtl_D_Rq 3;
BA_ "U_P702_MY2021_Tx" SG_ 878 DcacLedCtl_D_Rq 1;
BA_ "ECGUsedTxSignal" SG_ 2611055832 PARSEDPhysGWM_ECGtoSODR 1;
BA_ "GenSigSendType" SG_ 2611055832 PARSEDPhysGWM_ECGtoSODR 3;
BA_ "ECGUsedTxSignal" SG_ 2611054808 PARSEDPhysGWM_ECGtoSODL 1;
BA_ "GenSigSendType" SG_ 2611054808 PARSEDPhysGWM_ECGtoSODL 3;
BA_ "ECGUsedTxSignal" SG_ 2611026136 PARSEDPhysGWM_ECGtoSODCMD 1;
BA_ "GenSigSendType" SG_ 2611026136 PARSEDPhysGWM_ECGtoSODCMD 3;
BA_ "ECGUsedTxSignal" SG_ 2611025112 PARSEDPhysGWM_ECGtoSODCMC 1;
BA_ "GenSigSendType" SG_ 2611025112 PARSEDPhysGWM_ECGtoSODCMC 3;
BA_ "ECGUsedTxSignal" SG_ 2610975960 PARSEDPhysGWM_ECGtoCCM 1;
BA_ "GenSigSendType" SG_ 2610975960 PARSEDPhysGWM_ECGtoCCM 3;
BA_ "ECGUsedTxSignal" SG_ 2610007256 OTAPhysGWM_ECGtoSODR 1;
BA_ "GenSigSendType" SG_ 2610007256 OTAPhysGWM_ECGtoSODR 3;
BA_ "ECGUsedTxSignal" SG_ 2610006232 OTAPhysGWM_ECGtoSODL 1;
BA_ "GenSigSendType" SG_ 2610006232 OTAPhysGWM_ECGtoSODL 3;
BA_ "ECGUsedTxSignal" SG_ 2609977560 OTAPhysGWM_ECGtoSODCMD 1;
BA_ "GenSigSendType" SG_ 2609977560 OTAPhysGWM_ECGtoSODCMD 3;
BA_ "ECGUsedTxSignal" SG_ 2609976536 OTAPhysGWM_ECGtoSODCMC 1;
BA_ "GenSigSendType" SG_ 2609976536 OTAPhysGWM_ECGtoSODCMC 3;
BA_ "ECGUsedTxSignal" SG_ 2609927384 OTAPhysGWM_ECGtoCCM 1;
BA_ "GenSigSendType" SG_ 2609927384 OTAPhysGWM_ECGtoCCM 3;
BA_ "ECGUsedRxSignal" SG_ 2611175523 PARSEDPhysSODRtoGWM_ECG 1;
BA_ "GenSigSendType" SG_ 2611175523 PARSEDPhysSODRtoGWM_ECG 3;
BA_ "ECGUsedRxSignal" SG_ 2612224099 PARSEDPhysSODR2toGWM_ECG 1;
BA_ "GenSigSendType" SG_ 2612224099 PARSEDPhysSODR2toGWM_ECG 3;
BA_ "ECGUsedRxSignal" SG_ 2611175522 PARSEDPhysSODLtoGWM_ECG 1;
BA_ "GenSigSendType" SG_ 2611175522 PARSEDPhysSODLtoGWM_ECG 3;
BA_ "ECGUsedRxSignal" SG_ 2612224098 PARSEDPhysSODL2toGWM_ECG 1;
BA_ "GenSigSendType" SG_ 2612224098 PARSEDPhysSODL2toGWM_ECG 3;
BA_ "ECGUsedRxSignal" SG_ 2611175494 PARSEDPhysSODCMDtoGWM_ECG 1;
BA_ "GenSigSendType" SG_ 2611175494 PARSEDPhysSODCMDtoGWM_ECG 3;
BA_ "ECGUsedRxSignal" SG_ 2612224070 PARSEDPhysSODCMD2toGWM_ECG 1;
BA_ "GenSigSendType" SG_ 2612224070 PARSEDPhysSODCMD2toGWM_ECG 3;
BA_ "ECGUsedRxSignal" SG_ 2611175493 PARSEDPhysSODCMCtoGWM_ECG 1;
BA_ "GenSigSendType" SG_ 2611175493 PARSEDPhysSODCMCtoGWM_ECG 3;
BA_ "ECGUsedRxSignal" SG_ 2612224069 PARSEDPhysSODCMC2toGWM_ECG 1;
BA_ "GenSigSendType" SG_ 2612224069 PARSEDPhysSODCMC2toGWM_ECG 3;
BA_ "ECGUsedRxSignal" SG_ 2611175445 PARSEDPhysCCMtoGWM_ECG 1;
BA_ "GenSigSendType" SG_ 2611175445 PARSEDPhysCCMtoGWM_ECG 3;
BA_ "ECGUsedRxSignal" SG_ 2612224021 PARSEDPhysCCM2toGWM_ECG 1;
BA_ "GenSigSendType" SG_ 2612224021 PARSEDPhysCCM2toGWM_ECG 3;
BA_ "ECGUsedRxSignal" SG_ 2610126947 OTAPhysSODRtoGWM_ECG 1;
BA_ "GenSigSendType" SG_ 2610126947 OTAPhysSODRtoGWM_ECG 3;
BA_ "ECGUsedRxSignal" SG_ 2610126946 OTAPhysSODLtoGWM_ECG 1;
BA_ "GenSigSendType" SG_ 2610126946 OTAPhysSODLtoGWM_ECG 3;
BA_ "ECGUsedRxSignal" SG_ 2610126918 OTAPhysSODCMDtoGWM_ECG 1;
BA_ "GenSigSendType" SG_ 2610126918 OTAPhysSODCMDtoGWM_ECG 3;
BA_ "ECGUsedRxSignal" SG_ 2610126917 OTAPhysSODCMCtoGWM_ECG 1;
BA_ "GenSigSendType" SG_ 2610126917 OTAPhysSODCMCtoGWM_ECG 3;
BA_ "GenSigStartValue" SG_ 982 LatCtlCrv_NoRate2_Actl 1024;
BA_ "ContentDependant" SG_ 982 LatCtlPath_No_Cnt 1;
BA_ "MetaData" SG_ 982 LatCtlPath_No_Cnt 1;
BA_ "ContentDependant" SG_ 982 LatCtlPath_No_Cs 1;
BA_ "MetaData" SG_ 982 LatCtlPath_No_Cs 1;
BA_ "U_CX727_MY2021_Rx" SG_ 982 HandsOffCnfm_B_Rq 1;
BA_ "U_P702_MY2021_Rx" SG_ 982 HandsOffCnfm_B_Rq 1;
BA_ "U_CX727_MY2021_Rx" SG_ 982 LatCtlRampType_D_Rq 1;
BA_ "U_P702_MY2021_Rx" SG_ 982 LatCtlRampType_D_Rq 1;
BA_ "U_CX727_MY2021_Rx" SG_ 982 LatCtlPrecision_D_Rq 1;
BA_ "U_P702_MY2021_Rx" SG_ 982 LatCtlPrecision_D_Rq 1;
BA_ "GenSigStartValueInteger" SG_ 982 LatCtlPathOffst_L_Actl 512;
BA_ "U_CX727_MY2021_Rx" SG_ 982 LatCtlPathOffst_L_Actl 1;
BA_ "U_P702_MY2021_Rx" SG_ 982 LatCtlPathOffst_L_Actl 1;
BA_ "GenSigStartValueInteger" SG_ 982 LatCtlPath_An_Actl 1000;
BA_ "U_CX727_MY2021_Rx" SG_ 982 LatCtlPath_An_Actl 1;
BA_ "U_P702_MY2021_Rx" SG_ 982 LatCtlPath_An_Actl 1;
BA_ "GenSigStartValueInteger" SG_ 982 LatCtlCurv_No_Actl 1000;
BA_ "U_CX727_MY2021_Rx" SG_ 982 LatCtlCurv_No_Actl 1;
BA_ "U_P702_MY2021_Rx" SG_ 982 LatCtlCurv_No_Actl 1;
BA_ "MetaData" SG_ 1104 DrvEngageLevel_No_Cs 1;
BA_ "ContentDependant" SG_ 1104 DrvEngageLevel_No_Cs 1;
BA_ "MetaData" SG_ 1104 DrvEngageLevel_No_Cnt 1;
BA_ "ContentDependant" SG_ 1104 DrvEngageLevel_No_Cnt 1;
BA_ "ContentDependant" SG_ 1085 ULoRgenTestMde_B_Stat 1;
BA_ "U_P702_MY2021_Tx" SG_ 1085 ULoRgenTestMde_B_Stat 1;
BA_ "U_T6_MCA_MY2020_Tx" SG_ 1085 ULoRgenTestMde_B_Stat 1;
BA_ "U_P702_MY2021_Tx" SG_ 1085 PwSrcULoOvrTe_B_Actl 1;
BA_ "U_T6_MCA_MY2020_Tx" SG_ 1085 PwSrcULoOvrTe_B_Actl 1;
BA_ "U_P702_MY2021_Tx" SG_ 1085 PwSrcULoFalt_D_Stat 1;
BA_ "U_T6_MCA_MY2020_Tx" SG_ 1085 PwSrcULoFalt_D_Stat 1;
BA_ "U_P702_MY2021_Tx" SG_ 1085 PwSrcULoDcnnt_B_Stat 1;
BA_ "U_T6_MCA_MY2020_Tx" SG_ 1085 PwSrcULoDcnnt_B_Stat 1;
BA_ "U_P702_MY2021_Tx" SG_ 1085 PwSrcULo_Pc_Mx 1;
BA_ "U_T6_MCA_MY2020_Tx" SG_ 1085 PwSrcULo_Pc_Mx 1;
BA_ "ContentDependant" SG_ 1085 PwSrcULoComm_B_Falt 1;
BA_ "U_P702_MY2021_Tx" SG_ 1085 PwSrcULoComm_B_Falt 1;
BA_ "U_T6_MCA_MY2020_Tx" SG_ 1085 PwSrcULoComm_B_Falt 1;
BA_ "U_P702_MY2021_Rx" SG_ 1085 PwSrcULo_I_Mx 1;
BA_ "U_P702_MY2021_Tx" SG_ 1085 PwSrcULo_I_Mx 1;
BA_ "U_T6_MCA_MY2020_Tx" SG_ 1085 PwSrcULo_I_Mx 1;
BA_ "U_P702_MY2021_Rx" SG_ 1085 PwSrcULo_I_Actl 1;
BA_ "U_P702_MY2021_Tx" SG_ 1085 PwSrcULo_I_Actl 1;
BA_ "U_T6_MCA_MY2020_Tx" SG_ 1085 PwSrcULo_I_Actl 1;
BA_ "U_P702_MY2021_Rx" SG_ 865 BattRgenLo_U_Actl 1;
BA_ "GenSigStartValue" SG_ 865 BattRgenLo_U_Actl 768;
BA_ "U_P702_MY2021_Rx" SG_ 865 BattRgenLo_I_Actl 1;
BA_ "GenSigStartValue" SG_ 865 BattRgenLo_I_Actl 32768;
BA_ "GenSigStartValueInteger" SG_ 1445 SOBDMC_AutoSarNMReserved4 255;
BA_ "ContentDependant" SG_ 1445 SOBDMC_AutoSarNMReserved4 1;
BA_ "GenSigStartValue" SG_ 1445 SOBDMC_AutoSarNMReserved4 255;
BA_ "U_P702_MY2021_Tx" SG_ 1445 SOBDMC_AutoSarNMReserved4 1;
BA_ "GenSigStartValueInteger" SG_ 1445 SOBDMC_AutoSarNMReserved3 255;
BA_ "ContentDependant" SG_ 1445 SOBDMC_AutoSarNMReserved3 1;
BA_ "GenSigStartValue" SG_ 1445 SOBDMC_AutoSarNMReserved3 255;
BA_ "U_P702_MY2021_Tx" SG_ 1445 SOBDMC_AutoSarNMReserved3 1;
BA_ "GenSigStartValueInteger" SG_ 1445 SOBDMC_AutoSarNMReserved2 255;
BA_ "ContentDependant" SG_ 1445 SOBDMC_AutoSarNMReserved2 1;
BA_ "GenSigStartValue" SG_ 1445 SOBDMC_AutoSarNMReserved2 255;
BA_ "U_P702_MY2021_Tx" SG_ 1445 SOBDMC_AutoSarNMReserved2 1;
BA_ "GenSigStartValueInteger" SG_ 1445 SOBDMC_AutoSarNMReserved1 255;
BA_ "ContentDependant" SG_ 1445 SOBDMC_AutoSarNMReserved1 1;
BA_ "GenSigStartValue" SG_ 1445 SOBDMC_AutoSarNMReserved1 255;
BA_ "U_P702_MY2021_Tx" SG_ 1445 SOBDMC_AutoSarNMReserved1 1;
BA_ "GenSigStartValueInteger" SG_ 1445 SOBDMC_AutoSarNMNodeId 165;
BA_ "ContentDependant" SG_ 1445 SOBDMC_AutoSarNMNodeId 1;
BA_ "GenSigStartValue" SG_ 1445 SOBDMC_AutoSarNMNodeId 165;
BA_ "U_P702_MY2021_Tx" SG_ 1445 SOBDMC_AutoSarNMNodeId 1;
BA_ "ContentDependant" SG_ 1445 SOBDMC_AutoSarNMControl 1;
BA_ "U_P702_MY2021_Tx" SG_ 1445 SOBDMC_AutoSarNMControl 1;
BA_ "GenSigStartValueInteger" SG_ 1445 SOBDMC_GWOnBoardTester 255;
BA_ "ContentDependant" SG_ 1445 SOBDMC_GWOnBoardTester 1;
BA_ "GenSigStartValue" SG_ 1445 SOBDMC_GWOnBoardTester 255;
BA_ "U_P702_MY2021_Tx" SG_ 1445 SOBDMC_GWOnBoardTester 1;
BA_ "GenSigStartValueInteger" SG_ 1445 SOBDMC_GWNMProxy 255;
BA_ "ContentDependant" SG_ 1445 SOBDMC_GWNMProxy 1;
BA_ "GenSigStartValue" SG_ 1445 SOBDMC_GWNMProxy 255;
BA_ "U_P702_MY2021_Tx" SG_ 1445 SOBDMC_GWNMProxy 1;
BA_ "U_CX727_MY2021_Tx" SG_ 1088 ChrgTMatch_B_Stat 1;
BA_ "U_P702_MY2021_Tx" SG_ 1088 ChrgStat_D2_Dsply 1;
BA_ "ECGUsedRxSignal" SG_ 1088 ChrgStat_D2_Dsply 1;
BA_ "U_P702_MY2021_Tx" SG_ 1088 HvacPrecondRecirc_D_Rq 1;
BA_ "U_P702_MY2021_Tx" SG_ 1088 HvacPrecondMode2_D_Rq 1;
BA_ "ContentDependant" SG_ 1088 HvacPrecondMode2_D_Rq 1;
BA_ "WakeupSignal" SG_ 1088 HvacPrecondMode2_D_Rq 1;
BA_ "U_P702_MY2021_Tx" SG_ 1088 HvacPrecondBlwr2_D_Rq 1;
BA_ "ContentDependant" SG_ 1088 HvacPrecondBlwr2_D_Rq 1;
BA_ "WakeupSignal" SG_ 1088 HvacPrecondBlwr2_D_Rq 1;
BA_ "U_P702_MY2021_Tx" SG_ 1088 HvacPrecondAC_D_Rq 1;
BA_ "U_P702_MY2021_Tx" SG_ 1088 HvacPrecond_Te_Rq 1;
BA_ "GenSigStartValue" SG_ 1088 HvacPrecond_Te_Rq 2;
BA_ "GenSigStartValueInteger" SG_ 1088 HvacPrecond_Te_Rq 2;
BA_ "U_P702_MY2021_Tx" SG_ 1088 BattChrgInhbt_D_Rq 1;
BA_ "U_P702_MY2021_Tx" SG_ 786 RgenTrip_Pc_Dsply 1;
BA_ "CrossOver_InfoCAN" SG_ 786 RgenTrip_Pc_Dsply 1;
BA_ "ECGUsedRxSignal" SG_ 786 RgenTrip_Pc_Dsply 1;
BA_ "U_P702_MY2021_Tx" SG_ 786 RgenTrip_L_Dsply 1;
BA_ "GenSigStartValue" SG_ 786 RgenTrip_L_Dsply 65535;
BA_ "GenSigStartValueInteger" SG_ 786 RgenTrip_L_Dsply 65535;
BA_ "CrossOver_InfoCAN" SG_ 786 RgenTrip_L_Dsply 1;
BA_ "ECGUsedRxSignal" SG_ 786 RgenTrip_L_Dsply 1;
BA_ "U_P702_MY2021_Tx" SG_ 786 ChrgStat_D_Dsply 1;
BA_ "ECGUsedRxSignal" SG_ 786 ChrgStat_D_Dsply 1;
BA_ "U_P702_MY2021_Rx" SG_ 66 immoControlData_T2 1;
BA_ "ContentDependant" SG_ 66 immoControlData_T2 1;
BA_ "U_P702_MY2021_Rx" SG_ 66 immoControlCmd_T2 1;
BA_ "ContentDependant" SG_ 66 immoControlCmd_T2 1;
BA_ "WakeupSignal" SG_ 549 Power_Up_Chime_Modules 1;
BA_ "U_P702_MY2021_Rx" SG_ 611 AwdSys_D_Stat 1;
BA_ "U_T6_MCA_MY2020_Rx" SG_ 611 AwdSys_D_Stat 1;
BA_ "U_P702_MY2021_Tx" SG_ 611 AwdSys_D_Stat 1;
BA_ "CrossOver_InfoCAN" SG_ 611 AwdStat_D_RqDsply 1;
BA_ "ContentDependant" SG_ 611 AwdStat_D_RqDsply 1;
BA_ "U_P702_MY2021_Rx" SG_ 611 AwdStat_D_RqDsply 1;
BA_ "U_T6_MCA_MY2020_Rx" SG_ 611 AwdStat_D_RqDsply 1;
BA_ "U_P702_MY2021_Tx" SG_ 611 AwdStat_D_RqDsply 1;
BA_ "CrossOver_InfoCAN" SG_ 611 AwdLck_D_Stat 1;
BA_ "U_P702_MY2021_Rx" SG_ 611 AwdLck_D_Stat 1;
BA_ "U_T6_MCA_MY2020_Rx" SG_ 611 AwdLck_D_Stat 1;
BA_ "U_P702_MY2021_Tx" SG_ 611 AwdLck_D_Stat 1;
BA_ "CrossOver_InfoCAN" SG_ 611 AwdSrvcRqd_B_Rq 1;
BA_ "ContentDependant" SG_ 611 AwdSrvcRqd_B_Rq 1;
BA_ "U_P702_MY2021_Rx" SG_ 611 AwdSrvcRqd_B_Rq 1;
BA_ "U_T6_MCA_MY2020_Rx" SG_ 611 AwdSrvcRqd_B_Rq 1;
BA_ "U_P702_MY2021_Tx" SG_ 611 AwdSrvcRqd_B_Rq 1;
BA_ "U_P702_MY2021_Tx" SG_ 611 NtrlTowAvail_B_Stat 1;
BA_ "CrossOver_InfoCAN" SG_ 611 AwdLck_Tq_Rq 1;
BA_ "ContentDependant" SG_ 611 AwdLck_Tq_Rq 1;
BA_ "U_P702_MY2021_Rx" SG_ 611 AwdLck_Tq_Rq 1;
BA_ "U_P702_MY2021_Tx" SG_ 611 AwdLck_Tq_Rq 1;
BA_ "CrossOver_InfoCAN" SG_ 611 TrnAout_Tq_RqMx 1;
BA_ "GenSigStartValueInteger" SG_ 611 TrnAout_Tq_RqMx 8191;
BA_ "GenSigStartValue" SG_ 611 TrnAout_Tq_RqMx 8191;
BA_ "U_P702_MY2021_Rx" SG_ 611 TrnAout_Tq_RqMx 1;
BA_ "U_T6_MCA_MY2020_Rx" SG_ 611 TrnAout_Tq_RqMx 1;
BA_ "U_P702_MY2021_Tx" SG_ 611 TrnAout_Tq_RqMx 1;
BA_ "CrossOver_InfoCAN" SG_ 611 AwdOffRoadMode_D_Stats 1;
BA_ "U_P702_MY2021_Tx" SG_ 611 AwdOffRoadMode_D_Stats 1;
BA_ "CrossOver_InfoCAN" SG_ 611 AwdLoLamp_D_RqDsply 1;
BA_ "U_P702_MY2021_Tx" SG_ 611 AwdLoLamp_D_RqDsply 1;
BA_ "CrossOver_InfoCAN" SG_ 611 AwdHiLamp_D_RqDsply 1;
BA_ "U_P702_MY2021_Rx" SG_ 611 AwdHiLamp_D_RqDsply 1;
BA_ "U_P702_MY2021_Tx" SG_ 611 AwdHiLamp_D_RqDsply 1;
BA_ "CrossOver_InfoCAN" SG_ 611 AwdAutoLamp_D_RqDsply 1;
BA_ "U_P702_MY2021_Rx" SG_ 611 AwdAutoLamp_D_RqDsply 1;
BA_ "U_P702_MY2021_Tx" SG_ 611 AwdAutoLamp_D_RqDsply 1;
BA_ "CrossOver_InfoCAN" SG_ 611 Awd2wdLamp_D_RqDsply 1;
BA_ "U_P702_MY2021_Tx" SG_ 611 Awd2wdLamp_D_RqDsply 1;
BA_ "CrossOver_InfoCAN" SG_ 611 AwdRnge_D_Actl 1;
BA_ "GenSigStartValueInteger" SG_ 611 AwdRnge_D_Actl 7;
BA_ "GenSigStartValue" SG_ 611 AwdRnge_D_Actl 7;
BA_ "U_P702_MY2021_Rx" SG_ 611 AwdRnge_D_Actl 1;
BA_ "U_T6_MCA_MY2020_Rx" SG_ 611 AwdRnge_D_Actl 1;
BA_ "U_P702_MY2021_Tx" SG_ 611 AwdRnge_D_Actl 1;
BA_ "ECGUsedRxSignal" SG_ 611 AwdRnge_D_Actl 1;
BA_ "CrossOver_InfoCAN" SG_ 130 TrlrHitchLamp_D_Rqst 1;
BA_ "U_P702_MY2021_Tx" SG_ 130 TrlrHitchLamp_D_Rqst 1;
BA_ "CrossOver_InfoCAN" SG_ 130 VehVTrlrAid_B_Rq 1;
BA_ "U_P702_MY2021_Rx" SG_ 130 VehVTrlrAid_B_Rq 1;
BA_ "U_T6_MCA_MY2020_Rx" SG_ 130 VehVTrlrAid_B_Rq 1;
BA_ "U_P702_MY2021_Tx" SG_ 130 VehVTrlrAid_B_Rq 1;
BA_ "GenSigStartValueInteger" SG_ 130 Veh_V_RqMxTrlrAid 255;
BA_ "GenSigStartValue" SG_ 130 Veh_V_RqMxTrlrAid 255;
BA_ "U_P702_MY2021_Rx" SG_ 130 Veh_V_RqMxTrlrAid 1;
BA_ "U_T6_MCA_MY2020_Rx" SG_ 130 Veh_V_RqMxTrlrAid 1;
BA_ "U_P702_MY2021_Tx" SG_ 130 Veh_V_RqMxTrlrAid 1;
BA_ "U_P702_MY2021_Rx" SG_ 130 DrvSteActv_B_Stat 1;
BA_ "U_P702_MY2021_Tx" SG_ 130 DrvSteActv_B_Stat 1;
BA_ "GenSigStartValueInteger" SG_ 130 DrvSte_Tq_Actl 128;
BA_ "U_P702_MY2021_Rx" SG_ 130 DrvSte_Tq_Actl 1;
BA_ "U_P702_MY2021_Tx" SG_ 130 DrvSte_Tq_Actl 1;
BA_ "U_CX727_MY2021_Tx" SG_ 130 SteMdule_D_Stat 1;
BA_ "U_P702_MY2021_Tx" SG_ 130 SteMdule_D_Stat 1;
BA_ "GenSigStartValueInteger" SG_ 130 SteMdule_U_Meas 255;
BA_ "GenSigStartValue" SG_ 130 SteMdule_U_Meas 255;
BA_ "U_CX727_MY2021_Tx" SG_ 130 SteMdule_U_Meas 1;
BA_ "U_P702_MY2021_Tx" SG_ 130 SteMdule_U_Meas 1;
BA_ "GenSigStartValueInteger" SG_ 130 SteMdule_I_Est 4095;
BA_ "GenSigStartValue" SG_ 130 SteMdule_I_Est 4095;
BA_ "U_CX727_MY2021_Tx" SG_ 130 SteMdule_I_Est 1;
BA_ "U_P702_MY2021_Tx" SG_ 130 SteMdule_I_Est 1;
BA_ "CrossOver_InfoCAN" SG_ 130 EPAS_Failure 1;
BA_ "U_CX727_MY2021_Tx" SG_ 130 EPAS_Failure 1;
BA_ "U_P702_MY2021_Tx" SG_ 130 EPAS_Failure 1;
BA_ "GenSigStartValueInteger" SG_ 130 SteeringColumnTorque 254;
BA_ "GenSigStartValue" SG_ 130 SteeringColumnTorque 254;
BA_ "U_CX727_MY2021_Rx" SG_ 130 SteeringColumnTorque 1;
BA_ "U_P702_MY2021_Rx" SG_ 130 SteeringColumnTorque 1;
BA_ "U_CX727_MY2021_Tx" SG_ 130 SteeringColumnTorque 1;
BA_ "U_P702_MY2021_Tx" SG_ 130 SteeringColumnTorque 1;
BA_ "U_CX727_MY2021_Tx" SG_ 130 SAPPAngleControlStat6 1;
BA_ "U_P702_MY2021_Tx" SG_ 130 SAPPAngleControlStat6 1;
BA_ "U_CX727_MY2021_Tx" SG_ 130 SAPPAngleControlStat5 1;
BA_ "U_P702_MY2021_Tx" SG_ 130 SAPPAngleControlStat5 1;
BA_ "U_CX727_MY2021_Tx" SG_ 130 SAPPAngleControlStat4 1;
BA_ "U_P702_MY2021_Tx" SG_ 130 SAPPAngleControlStat4 1;
BA_ "U_CX727_MY2021_Tx" SG_ 130 SAPPAngleControlStat3 1;
BA_ "U_P702_MY2021_Tx" SG_ 130 SAPPAngleControlStat3 1;
BA_ "U_CX727_MY2021_Tx" SG_ 130 SAPPAngleControlStat2 1;
BA_ "U_P702_MY2021_Tx" SG_ 130 SAPPAngleControlStat2 1;
BA_ "U_CX727_MY2021_Tx" SG_ 130 SAPPAngleControlStat1 1;
BA_ "U_P702_MY2021_Tx" SG_ 130 SAPPAngleControlStat1 1;
BA_ "U_P702_MY2021_Rx" SG_ 126 StePw_B_Rq 1;
BA_ "U_T6_MCA_MY2020_Rx" SG_ 126 StePw_B_Rq 1;
BA_ "U_P702_MY2021_Tx" SG_ 126 StePw_B_Rq 1;
BA_ "GenSigStartValueInteger" SG_ 126 StePinRelInit_An_Sns 65535;
BA_ "ContentDependant" SG_ 126 StePinRelInit_An_Sns 1;
BA_ "GenSigStartValue" SG_ 126 StePinRelInit_An_Sns 65535;
BA_ "U_P702_MY2021_Rx" SG_ 126 StePinRelInit_An_Sns 1;
BA_ "U_CX727_MY2021_Rx" SG_ 126 StePinRelInit_An_Sns 1;
BA_ "U_T6_MCA_MY2020_Rx" SG_ 126 StePinRelInit_An_Sns 1;
BA_ "U_CX727_MY2021_Tx" SG_ 126 StePinRelInit_An_Sns 1;
BA_ "U_P702_MY2021_Tx" SG_ 126 StePinRelInit_An_Sns 1;
BA_ "CrossOver_InfoCAN" SG_ 126 StePinCompAnEst_D_Qf 1;
BA_ "GenSigStartValueInteger" SG_ 126 StePinCompAnEst_D_Qf 1;
BA_ "GenSigStartValue" SG_ 126 StePinCompAnEst_D_Qf 1;
BA_ "U_P702_MY2021_Rx" SG_ 126 StePinCompAnEst_D_Qf 1;
BA_ "U_CX727_MY2021_Rx" SG_ 126 StePinCompAnEst_D_Qf 1;
BA_ "U_T6_MCA_MY2020_Rx" SG_ 126 StePinCompAnEst_D_Qf 1;
BA_ "U_CX727_MY2021_Tx" SG_ 126 StePinCompAnEst_D_Qf 1;
BA_ "U_P702_MY2021_Tx" SG_ 126 StePinCompAnEst_D_Qf 1;
BA_ "ECGUsedRxSignal" SG_ 126 StePinCompAnEst_D_Qf 1;
BA_ "GenSigStartValueInteger" SG_ 126 StePinComp_An_Est 16000;
BA_ "U_P702_MY2021_Rx" SG_ 126 StePinComp_An_Est 1;
BA_ "U_CX727_MY2021_Rx" SG_ 126 StePinComp_An_Est 1;
BA_ "U_T6_MCA_MY2020_Rx" SG_ 126 StePinComp_An_Est 1;
BA_ "U_CX727_MY2021_Tx" SG_ 126 StePinComp_An_Est 1;
BA_ "U_P702_MY2021_Tx" SG_ 126 StePinComp_An_Est 1;
BA_ "ECGUsedRxSignal" SG_ 126 StePinComp_An_Est 1;
BA_ "ContentDependant" SG_ 126 StePinAn_No_Cs 1;
BA_ "MetaData" SG_ 126 StePinAn_No_Cs 1;
BA_ "U_P702_MY2021_Rx" SG_ 126 StePinAn_No_Cs 1;
BA_ "U_CX727_MY2021_Rx" SG_ 126 StePinAn_No_Cs 1;
BA_ "U_CX727_MY2021_Tx" SG_ 126 StePinAn_No_Cs 1;
BA_ "U_P702_MY2021_Tx" SG_ 126 StePinAn_No_Cs 1;
BA_ "CrossOver_InfoCAN" SG_ 126 StePinAn_No_Cnt 1;
BA_ "MetaData" SG_ 126 StePinAn_No_Cnt 1;
BA_ "U_P702_MY2021_Rx" SG_ 126 StePinAn_No_Cnt 1;
BA_ "U_CX727_MY2021_Rx" SG_ 126 StePinAn_No_Cnt 1;
BA_ "U_CX727_MY2021_Tx" SG_ 126 StePinAn_No_Cnt 1;
BA_ "U_P702_MY2021_Tx" SG_ 126 StePinAn_No_Cnt 1;
BA_ "GenSigStartValueInteger" SG_ 1200 HsaTrnAout_Tq_Rq 32768;
BA_ "U_CX727_MY2021_Tx" SG_ 1200 HsaTrnAout_Tq_Rq 1;
BA_ "U_P702_MY2021_Tx" SG_ 1200 HsaTrnAout_Tq_Rq 1;
BA_ "GenSigStartValueInteger" SG_ 1200 BrkBstrVac_P_Actl 127;
BA_ "GenSigStartValue" SG_ 1200 BrkBstrVac_P_Actl 127;
BA_ "U_P702_MY2021_Rx" SG_ 1200 BrkBstrVac_P_Actl 1;
BA_ "U_T6_MCA_MY2020_Rx" SG_ 1200 BrkBstrVac_P_Actl 1;
BA_ "U_CX727_MY2021_Tx" SG_ 1200 BrkBstrVac_P_Actl 1;
BA_ "U_P702_MY2021_Tx" SG_ 1200 BrkBstrVac_P_Actl 1;
BA_ "GenSigStartValueInteger" SG_ 1200 YawStabilityIndex 256;
BA_ "U_CX727_MY2021_Rx" SG_ 1200 YawStabilityIndex 1;
BA_ "U_P702_MY2021_Rx" SG_ 1200 YawStabilityIndex 1;
BA_ "U_CX727_MY2021_Tx" SG_ 1200 YawStabilityIndex 1;
BA_ "U_P702_MY2021_Tx" SG_ 1200 YawStabilityIndex 1;
BA_ "U_P702_MY2021_Rx" SG_ 1200 BrkTot_Tq_RqDrv 1;
BA_ "U_T6_MCA_MY2020_Rx" SG_ 1200 BrkTot_Tq_RqDrv 1;
BA_ "U_CX727_MY2021_Tx" SG_ 1200 BrkTot_Tq_RqDrv 1;
BA_ "U_P702_MY2021_Tx" SG_ 1200 BrkTot_Tq_RqDrv 1;
BA_ "MetaData" SG_ 1200 BrkTotTqRqDrv_No_Cnt 1;
BA_ "U_P702_MY2021_Rx" SG_ 1200 BrkTotTqRqDrv_No_Cnt 1;
BA_ "U_T6_MCA_MY2020_Rx" SG_ 1200 BrkTotTqRqDrv_No_Cnt 1;
BA_ "U_CX727_MY2021_Tx" SG_ 1200 BrkTotTqRqDrv_No_Cnt 1;
BA_ "U_P702_MY2021_Tx" SG_ 1200 BrkTotTqRqDrv_No_Cnt 1;
BA_ "MetaData" SG_ 1200 BrkTotTqRqDrv_No_Cs 1;
BA_ "U_P702_MY2021_Rx" SG_ 1200 BrkTotTqRqDrv_No_Cs 1;
BA_ "U_T6_MCA_MY2020_Rx" SG_ 1200 BrkTotTqRqDrv_No_Cs 1;
BA_ "U_CX727_MY2021_Tx" SG_ 1200 BrkTotTqRqDrv_No_Cs 1;
BA_ "U_P702_MY2021_Tx" SG_ 1200 BrkTotTqRqDrv_No_Cs 1;
BA_ "U_CX727_MY2021_Tx" SG_ 1200 HsaStat_D_Dsply 1;
BA_ "U_P702_MY2021_Tx" SG_ 1200 HsaStat_D_Dsply 1;
BA_ "CrossOver_InfoCAN" SG_ 1046 HsaMde_D_Mem 1;
BA_ "GenSigStartValueInteger" SG_ 1046 HsaMde_D_Mem 1;
BA_ "GenSigStartValue" SG_ 1046 HsaMde_D_Mem 1;
BA_ "U_CX727_MY2021_Tx" SG_ 1046 HsaMde_D_Mem 1;
BA_ "U_P702_MY2021_Tx" SG_ 1046 HsaMde_D_Mem 1;
BA_ "CrossOver_InfoCAN" SG_ 1046 BrkBstrVac_B_Rq 1;
BA_ "U_P702_MY2021_Rx" SG_ 1046 BrkBstrVac_B_Rq 1;
BA_ "U_T6_MCA_MY2020_Rx" SG_ 1046 BrkBstrVac_B_Rq 1;
BA_ "U_CX727_MY2021_Tx" SG_ 1046 BrkBstrVac_B_Rq 1;
BA_ "U_P702_MY2021_Tx" SG_ 1046 BrkBstrVac_B_Rq 1;
BA_ "CrossOver_InfoCAN" SG_ 1046 HdcMde_D_Actl 1;
BA_ "U_CX727_MY2021_Tx" SG_ 1046 HdcMde_D_Actl 1;
BA_ "U_P702_MY2021_Tx" SG_ 1046 HdcMde_D_Actl 1;
BA_ "GenSigStartValueInteger" SG_ 1046 RearDiffLck_Tq2_RqMx 4094;
BA_ "GenSigStartValue" SG_ 1046 RearDiffLck_Tq2_RqMx 4094;
BA_ "U_CX727_MY2021_Tx" SG_ 1046 RearDiffLck_Tq2_RqMx 1;
BA_ "U_P702_MY2021_Tx" SG_ 1046 RearDiffLck_Tq2_RqMx 1;
BA_ "U_CX727_MY2021_Tx" SG_ 1046 TRLR_SWAY_EVNT_IN_PROG 1;
BA_ "U_P702_MY2021_Tx" SG_ 1046 TRLR_SWAY_EVNT_IN_PROG 1;
BA_ "ECGUsedRxSignal" SG_ 1046 TRLR_SWAY_EVNT_IN_PROG 1;
BA_ "U_CX727_MY2021_Tx" SG_ 1046 TRLR_SWAY_CONFIG_STAT 1;
BA_ "U_P702_MY2021_Tx" SG_ 1046 TRLR_SWAY_CONFIG_STAT 1;
BA_ "CrossOver_InfoCAN" SG_ 1046 TCMode 1;
BA_ "ContentDependant" SG_ 1046 TCMode 1;
BA_ "U_P702_MY2021_Rx" SG_ 1046 TCMode 1;
BA_ "U_T6_MCA_MY2020_Rx" SG_ 1046 TCMode 1;
BA_ "U_CX727_MY2021_Tx" SG_ 1046 TCMode 1;
BA_ "U_P702_MY2021_Tx" SG_ 1046 TCMode 1;
BA_ "ECGUsedRxSignal" SG_ 1046 TCMode 1;
BA_ "CrossOver_InfoCAN" SG_ 1046 DrvSlipCtlLamp_D_Rq 1;
BA_ "U_P702_MY2021_Rx" SG_ 1046 DrvSlipCtlLamp_D_Rq 1;
BA_ "U_T6_MCA_MY2020_Rx" SG_ 1046 DrvSlipCtlLamp_D_Rq 1;
BA_ "U_CX727_MY2021_Tx" SG_ 1046 DrvSlipCtlLamp_D_Rq 1;
BA_ "U_P702_MY2021_Tx" SG_ 1046 DrvSlipCtlLamp_D_Rq 1;
BA_ "CrossOver_InfoCAN" SG_ 1046 Abs_B_Falt 1;
BA_ "U_P702_MY2021_Rx" SG_ 1046 Abs_B_Falt 1;
BA_ "U_T6_MCA_MY2020_Rx" SG_ 1046 Abs_B_Falt 1;
BA_ "U_CX727_MY2021_Tx" SG_ 1046 Abs_B_Falt 1;
BA_ "U_P702_MY2021_Tx" SG_ 1046 Abs_B_Falt 1;
BA_ "ECGUsedRxSignal" SG_ 1046 Abs_B_Falt 1;
BA_ "CrossOver_InfoCAN" SG_ 1046 DrvSlipCtlMde_D_Ind 1;
BA_ "U_P702_MY2021_Rx" SG_ 1046 DrvSlipCtlMde_D_Ind 1;
BA_ "U_T6_MCA_MY2020_Rx" SG_ 1046 DrvSlipCtlMde_D_Ind 1;
BA_ "U_CX727_MY2021_Tx" SG_ 1046 DrvSlipCtlMde_D_Ind 1;
BA_ "U_P702_MY2021_Tx" SG_ 1046 DrvSlipCtlMde_D_Ind 1;
BA_ "ECGUsedRxSignal" SG_ 1046 DrvSlipCtlMde_D_Ind 1;
BA_ "CrossOver_InfoCAN" SG_ 1046 DrvAntiLckLamp_D_Rq 1;
BA_ "U_P702_MY2021_Rx" SG_ 1046 DrvAntiLckLamp_D_Rq 1;
BA_ "U_T6_MCA_MY2020_Rx" SG_ 1046 DrvAntiLckLamp_D_Rq 1;
BA_ "U_CX727_MY2021_Tx" SG_ 1046 DrvAntiLckLamp_D_Rq 1;
BA_ "U_P702_MY2021_Tx" SG_ 1046 DrvAntiLckLamp_D_Rq 1;
BA_ "CrossOver_InfoCAN" SG_ 1046 BpedMove_No_Cnt 1;
BA_ "MetaData" SG_ 1046 BpedMove_No_Cnt 1;
BA_ "U_P702_MY2021_Rx" SG_ 1046 BpedMove_No_Cnt 1;
BA_ "U_CX727_MY2021_Tx" SG_ 1046 BpedMove_No_Cnt 1;
BA_ "U_P702_MY2021_Tx" SG_ 1046 BpedMove_No_Cnt 1;
BA_ "CrossOver_InfoCAN" SG_ 1046 StabCtlBrk_B_Avail 1;
BA_ "GenSigStartValueInteger" SG_ 1046 StabCtlBrk_B_Avail 1;
BA_ "GenSigStartValue" SG_ 1046 StabCtlBrk_B_Avail 1;
BA_ "U_CX727_MY2021_Tx" SG_ 1046 StabCtlBrk_B_Avail 1;
BA_ "U_P702_MY2021_Tx" SG_ 1046 StabCtlBrk_B_Avail 1;
BA_ "CrossOver_InfoCAN" SG_ 1046 DrvHdcWarnInfo_D_Rq 1;
BA_ "U_CX727_MY2021_Tx" SG_ 1046 DrvHdcWarnInfo_D_Rq 1;
BA_ "U_P702_MY2021_Tx" SG_ 1046 DrvHdcWarnInfo_D_Rq 1;
BA_ "CrossOver_InfoCAN" SG_ 1046 DrvHdcMsg_D_Rq 1;
BA_ "U_CX727_MY2021_Tx" SG_ 1046 DrvHdcMsg_D_Rq 1;
BA_ "U_P702_MY2021_Tx" SG_ 1046 DrvHdcMsg_D_Rq 1;
BA_ "CrossOver_InfoCAN" SG_ 1046 DrvHdcLampInfo_D_Rq 1;
BA_ "U_CX727_MY2021_Tx" SG_ 1046 DrvHdcLampInfo_D_Rq 1;
BA_ "U_P702_MY2021_Tx" SG_ 1046 DrvHdcLampInfo_D_Rq 1;
BA_ "CrossOver_InfoCAN" SG_ 1046 BpedMove_D_Actl 1;
BA_ "GenSigStartValueInteger" SG_ 1046 BpedMove_D_Actl 3;
BA_ "GenSigStartValue" SG_ 1046 BpedMove_D_Actl 3;
BA_ "U_P702_MY2021_Rx" SG_ 1046 BpedMove_D_Actl 1;
BA_ "U_CX727_MY2021_Tx" SG_ 1046 BpedMove_D_Actl 1;
BA_ "U_P702_MY2021_Tx" SG_ 1046 BpedMove_D_Actl 1;
BA_ "CrossOver_InfoCAN" SG_ 1046 ChimeBrk_B_Rq 1;
BA_ "U_CX727_MY2021_Tx" SG_ 1046 ChimeBrk_B_Rq 1;
BA_ "U_P702_MY2021_Tx" SG_ 1046 ChimeBrk_B_Rq 1;
BA_ "CrossOver_InfoCAN" SG_ 1046 BrkLamp_B_Rq 1;
BA_ "U_CX727_MY2021_Tx" SG_ 1046 BrkLamp_B_Rq 1;
BA_ "U_P702_MY2021_Tx" SG_ 1046 BrkLamp_B_Rq 1;
BA_ "CrossOver_InfoCAN" SG_ 1046 HILL_DESC_MC 1;
BA_ "U_CX727_MY2021_Tx" SG_ 1046 HILL_DESC_MC 1;
BA_ "U_P702_MY2021_Tx" SG_ 1046 HILL_DESC_MC 1;
BA_ "U_P702_MY2021_Tx" SG_ 1046 RearDiffElckrOpen_B_Rq 1;
BA_ "GenSigStartValueInteger" SG_ 1044 StePinOffst_An_Est 65534;
BA_ "ContentDependant" SG_ 1044 StePinOffst_An_Est 1;
BA_ "GenSigStartValue" SG_ 1044 StePinOffst_An_Est 65533;
BA_ "U_CX727_MY2021_Rx" SG_ 1044 StePinOffst_An_Est 1;
BA_ "U_P702_MY2021_Rx" SG_ 1044 StePinOffst_An_Est 1;
BA_ "U_CX727_MY2021_Tx" SG_ 1044 StePinOffst_An_Est 1;
BA_ "U_P702_MY2021_Tx" SG_ 1044 StePinOffst_An_Est 1;
BA_ "ContentDependant" SG_ 1044 StePinOffst_No_Cs 1;
BA_ "MetaData" SG_ 1044 StePinOffst_No_Cs 1;
BA_ "U_CX727_MY2021_Rx" SG_ 1044 StePinOffst_No_Cs 1;
BA_ "U_P702_MY2021_Rx" SG_ 1044 StePinOffst_No_Cs 1;
BA_ "U_CX727_MY2021_Tx" SG_ 1044 StePinOffst_No_Cs 1;
BA_ "U_P702_MY2021_Tx" SG_ 1044 StePinOffst_No_Cs 1;
BA_ "CrossOver_InfoCAN" SG_ 1044 StePinOffst_No_Cnt 1;
BA_ "MetaData" SG_ 1044 StePinOffst_No_Cnt 1;
BA_ "U_CX727_MY2021_Rx" SG_ 1044 StePinOffst_No_Cnt 1;
BA_ "U_P702_MY2021_Rx" SG_ 1044 StePinOffst_No_Cnt 1;
BA_ "U_CX727_MY2021_Tx" SG_ 1044 StePinOffst_No_Cnt 1;
BA_ "U_P702_MY2021_Tx" SG_ 1044 StePinOffst_No_Cnt 1;
BA_ "U_CX727_MY2021_Rx" SG_ 1044 StePinOffst_D_Stat 1;
BA_ "U_P702_MY2021_Rx" SG_ 1044 StePinOffst_D_Stat 1;
BA_ "U_CX727_MY2021_Tx" SG_ 1044 StePinOffst_D_Stat 1;
BA_ "U_P702_MY2021_Tx" SG_ 1044 StePinOffst_D_Stat 1;
BA_ "GenSigStartValueInteger" SG_ 1042 VehRol_An_Dsply 64;
BA_ "U_P702_MY2021_Tx" SG_ 1042 VehRol_An_Dsply 1;
BA_ "GenSigStartValueInteger" SG_ 1042 VehPtch_An_Dsply 64;
BA_ "U_P702_MY2021_Rx" SG_ 1042 VehPtch_An_Dsply 1;
BA_ "U_P702_MY2021_Tx" SG_ 1042 VehPtch_An_Dsply 1;
BA_ "U_P702_MY2021_Tx" SG_ 1042 TrlrBrk_Pc_Rq 1;
BA_ "ContentDependant" SG_ 534 BrkObdData_No_Actl 1;
BA_ "U_CX727_MY2021_Tx" SG_ 534 BrkObdData_No_Actl 1;
BA_ "U_P702_MY2021_Tx" SG_ 534 BrkObdData_No_Actl 1;
BA_ "ContentDependant" SG_ 534 BrkObdIndex_No_Actl 1;
BA_ "U_CX727_MY2021_Tx" SG_ 534 BrkObdIndex_No_Actl 1;
BA_ "U_P702_MY2021_Tx" SG_ 534 BrkObdIndex_No_Actl 1;
BA_ "CrossOver_InfoCAN" SG_ 534 WhlRotatRr_No_Cnt 1;
BA_ "U_P702_MY2021_Rx" SG_ 534 WhlRotatRr_No_Cnt 1;
BA_ "U_CX727_MY2021_Tx" SG_ 534 WhlRotatRr_No_Cnt 1;
BA_ "U_P702_MY2021_Tx" SG_ 534 WhlRotatRr_No_Cnt 1;
BA_ "CrossOver_InfoCAN" SG_ 534 WhlDirRr_D_Actl 1;
BA_ "U_CX727_MY2021_Rx" SG_ 534 WhlDirRr_D_Actl 1;
BA_ "U_P702_MY2021_Rx" SG_ 534 WhlDirRr_D_Actl 1;
BA_ "U_T6_MCA_MY2020_Rx" SG_ 534 WhlDirRr_D_Actl 1;
BA_ "U_CX727_MY2021_Tx" SG_ 534 WhlDirRr_D_Actl 1;
BA_ "U_P702_MY2021_Tx" SG_ 534 WhlDirRr_D_Actl 1;
BA_ "CrossOver_InfoCAN" SG_ 534 WhlDirRl_D_Actl 1;
BA_ "U_P702_MY2021_Rx" SG_ 534 WhlDirRl_D_Actl 1;
BA_ "U_T6_MCA_MY2020_Rx" SG_ 534 WhlDirRl_D_Actl 1;
BA_ "U_CX727_MY2021_Rx" SG_ 534 WhlDirRl_D_Actl 1;
BA_ "U_CX727_MY2021_Tx" SG_ 534 WhlDirRl_D_Actl 1;
BA_ "U_P702_MY2021_Tx" SG_ 534 WhlDirRl_D_Actl 1;
BA_ "CrossOver_InfoCAN" SG_ 534 WhlDirFr_D_Actl 1;
BA_ "U_CX727_MY2021_Rx" SG_ 534 WhlDirFr_D_Actl 1;
BA_ "U_P702_MY2021_Rx" SG_ 534 WhlDirFr_D_Actl 1;
BA_ "U_T6_MCA_MY2020_Rx" SG_ 534 WhlDirFr_D_Actl 1;
BA_ "U_CX727_MY2021_Tx" SG_ 534 WhlDirFr_D_Actl 1;
BA_ "U_P702_MY2021_Tx" SG_ 534 WhlDirFr_D_Actl 1;
BA_ "CrossOver_InfoCAN" SG_ 534 WhlDirFl_D_Actl 1;
BA_ "U_CX727_MY2021_Rx" SG_ 534 WhlDirFl_D_Actl 1;
BA_ "U_P702_MY2021_Rx" SG_ 534 WhlDirFl_D_Actl 1;
BA_ "U_T6_MCA_MY2020_Rx" SG_ 534 WhlDirFl_D_Actl 1;
BA_ "U_CX727_MY2021_Tx" SG_ 534 WhlDirFl_D_Actl 1;
BA_ "U_P702_MY2021_Tx" SG_ 534 WhlDirFl_D_Actl 1;
BA_ "CrossOver_InfoCAN" SG_ 534 WhlRotatRl_No_Cnt 1;
BA_ "U_P702_MY2021_Rx" SG_ 534 WhlRotatRl_No_Cnt 1;
BA_ "U_CX727_MY2021_Tx" SG_ 534 WhlRotatRl_No_Cnt 1;
BA_ "U_P702_MY2021_Tx" SG_ 534 WhlRotatRl_No_Cnt 1;
BA_ "CrossOver_InfoCAN" SG_ 534 WhlRotatFr_No_Cnt 1;
BA_ "U_P702_MY2021_Rx" SG_ 534 WhlRotatFr_No_Cnt 1;
BA_ "U_CX727_MY2021_Tx" SG_ 534 WhlRotatFr_No_Cnt 1;
BA_ "U_P702_MY2021_Tx" SG_ 534 WhlRotatFr_No_Cnt 1;
BA_ "CrossOver_InfoCAN" SG_ 534 WhlRotatFl_No_Cnt 1;
BA_ "U_P702_MY2021_Rx" SG_ 534 WhlRotatFl_No_Cnt 1;
BA_ "U_CX727_MY2021_Tx" SG_ 534 WhlRotatFl_No_Cnt 1;
BA_ "U_P702_MY2021_Tx" SG_ 534 WhlRotatFl_No_Cnt 1;
BA_ "GenSigStartValueInteger" SG_ 531 VehStop_D_Stat 2;
BA_ "GenSigStartValue" SG_ 531 VehStop_D_Stat 2;
BA_ "U_CX727_MY2021_Tx" SG_ 531 VehStop_D_Stat 1;
BA_ "U_P702_MY2021_Tx" SG_ 531 VehStop_D_Stat 1;
BA_ "CrossOver_InfoCAN" SG_ 531 TracCtlPtActv_B_Actl 1;
BA_ "U_P702_MY2021_Rx" SG_ 531 TracCtlPtActv_B_Actl 1;
BA_ "U_T6_MCA_MY2020_Rx" SG_ 531 TracCtlPtActv_B_Actl 1;
BA_ "U_CX727_MY2021_Tx" SG_ 531 TracCtlPtActv_B_Actl 1;
BA_ "U_P702_MY2021_Tx" SG_ 531 TracCtlPtActv_B_Actl 1;
BA_ "CrossOver_InfoCAN" SG_ 531 LscmbbMntr_B_Err 1;
BA_ "U_P702_MY2021_Tx" SG_ 531 LscmbbMntr_B_Err 1;
BA_ "CrossOver_InfoCAN" SG_ 531 LscmbbBrkDis_B_Actl 1;
BA_ "U_P702_MY2021_Tx" SG_ 531 LscmbbBrkDis_B_Actl 1;
BA_ "CrossOver_InfoCAN" SG_ 531 LscmbbDeny_B_ActlBrk 1;
BA_ "U_P702_MY2021_Tx" SG_ 531 LscmbbDeny_B_ActlBrk 1;
BA_ "WakeupSignal" SG_ 531 PrkBrkYwLamp_D_Rq 1;
BA_ "CrossOver_InfoCAN" SG_ 531 PrkBrkYwLamp_D_Rq 1;
BA_ "U_CX727_MY2021_Tx" SG_ 531 PrkBrkYwLamp_D_Rq 1;
BA_ "U_P702_MY2021_Tx" SG_ 531 PrkBrkYwLamp_D_Rq 1;
BA_ "WakeupSignal" SG_ 531 PrkBrkRedLamp_D_Rq 1;
BA_ "CrossOver_InfoCAN" SG_ 531 PrkBrkRedLamp_D_Rq 1;
BA_ "U_CX727_MY2021_Tx" SG_ 531 PrkBrkRedLamp_D_Rq 1;
BA_ "U_P702_MY2021_Tx" SG_ 531 PrkBrkRedLamp_D_Rq 1;
BA_ "CrossOver_InfoCAN" SG_ 531 LscmbbBrkDecel_B_Actl 1;
BA_ "U_P702_MY2021_Tx" SG_ 531 LscmbbBrkDecel_B_Actl 1;
BA_ "CrossOver_InfoCAN" SG_ 531 AbsActv_B_Actl 1;
BA_ "U_CX727_MY2021_Rx" SG_ 531 AbsActv_B_Actl 1;
BA_ "U_P702_MY2021_Rx" SG_ 531 AbsActv_B_Actl 1;
BA_ "U_T6_MCA_MY2020_Rx" SG_ 531 AbsActv_B_Actl 1;
BA_ "U_CX727_MY2021_Tx" SG_ 531 AbsActv_B_Actl 1;
BA_ "U_P702_MY2021_Tx" SG_ 531 AbsActv_B_Actl 1;
BA_ "CrossOver_InfoCAN" SG_ 531 StabCtlBrkActv_B_Actl 1;
BA_ "U_P702_MY2021_Rx" SG_ 531 StabCtlBrkActv_B_Actl 1;
BA_ "U_T6_MCA_MY2020_Rx" SG_ 531 StabCtlBrkActv_B_Actl 1;
BA_ "U_CX727_MY2021_Rx" SG_ 531 StabCtlBrkActv_B_Actl 1;
BA_ "U_CX727_MY2021_Tx" SG_ 531 StabCtlBrkActv_B_Actl 1;
BA_ "U_P702_MY2021_Tx" SG_ 531 StabCtlBrkActv_B_Actl 1;
BA_ "ECGUsedRxSignal" SG_ 531 StabCtlBrkActv_B_Actl 1;
BA_ "CrossOver_InfoCAN" SG_ 531 CmbbBrkPrchg_B_Actl 1;
BA_ "U_CX727_MY2021_Tx" SG_ 531 CmbbBrkPrchg_B_Actl 1;
BA_ "U_P702_MY2021_Tx" SG_ 531 CmbbBrkPrchg_B_Actl 1;
BA_ "CrossOver_InfoCAN" SG_ 531 CmbbBrkDecel_B_Actl 1;
BA_ "U_CX727_MY2021_Tx" SG_ 531 CmbbBrkDecel_B_Actl 1;
BA_ "U_P702_MY2021_Tx" SG_ 531 CmbbBrkDecel_B_Actl 1;
BA_ "CrossOver_InfoCAN" SG_ 531 CmbbBaSensInc_B_Actl 1;
BA_ "U_CX727_MY2021_Tx" SG_ 531 CmbbBaSensInc_B_Actl 1;
BA_ "U_P702_MY2021_Tx" SG_ 531 CmbbBaSensInc_B_Actl 1;
BA_ "CrossOver_InfoCAN" SG_ 531 AccBrkWarm_B_Actl 1;
BA_ "U_CX727_MY2021_Tx" SG_ 531 AccBrkWarm_B_Actl 1;
BA_ "U_P702_MY2021_Tx" SG_ 531 AccBrkWarm_B_Actl 1;
BA_ "CrossOver_InfoCAN" SG_ 531 AccBrkTotTqMn_B_Actl 1;
BA_ "U_CX727_MY2021_Tx" SG_ 531 AccBrkTotTqMn_B_Actl 1;
BA_ "U_P702_MY2021_Tx" SG_ 531 AccBrkTotTqMn_B_Actl 1;
BA_ "CrossOver_InfoCAN" SG_ 531 AccBrkPrchgActv_B_Actl 1;
BA_ "U_CX727_MY2021_Tx" SG_ 531 AccBrkPrchgActv_B_Actl 1;
BA_ "U_P702_MY2021_Tx" SG_ 531 AccBrkPrchgActv_B_Actl 1;
BA_ "CrossOver_InfoCAN" SG_ 531 AccBrkDis_B_Actl 1;
BA_ "U_CX727_MY2021_Tx" SG_ 531 AccBrkDis_B_Actl 1;
BA_ "U_P702_MY2021_Tx" SG_ 531 AccBrkDis_B_Actl 1;
BA_ "CrossOver_InfoCAN" SG_ 531 AccBrkDeny_B_Actl 1;
BA_ "U_P702_MY2021_Rx" SG_ 531 AccBrkDeny_B_Actl 1;
BA_ "U_T6_MCA_MY2020_Rx" SG_ 531 AccBrkDeny_B_Actl 1;
BA_ "U_CX727_MY2021_Tx" SG_ 531 AccBrkDeny_B_Actl 1;
BA_ "U_P702_MY2021_Tx" SG_ 531 AccBrkDeny_B_Actl 1;
BA_ "CrossOver_InfoCAN" SG_ 531 AccBrkActv_B_Actl 1;
BA_ "U_P702_MY2021_Rx" SG_ 531 AccBrkActv_B_Actl 1;
BA_ "U_T6_MCA_MY2020_Rx" SG_ 531 AccBrkActv_B_Actl 1;
BA_ "U_CX727_MY2021_Tx" SG_ 531 AccBrkActv_B_Actl 1;
BA_ "U_P702_MY2021_Tx" SG_ 531 AccBrkActv_B_Actl 1;
BA_ "CrossOver_InfoCAN" SG_ 531 PrplDrgCtlActv_B_Actl 1;
BA_ "U_P702_MY2021_Rx" SG_ 531 PrplDrgCtlActv_B_Actl 1;
BA_ "U_T6_MCA_MY2020_Rx" SG_ 531 PrplDrgCtlActv_B_Actl 1;
BA_ "U_CX727_MY2021_Tx" SG_ 531 PrplDrgCtlActv_B_Actl 1;
BA_ "U_P702_MY2021_Tx" SG_ 531 PrplDrgCtlActv_B_Actl 1;
BA_ "CrossOver_InfoCAN" SG_ 531 PrplWhlTot_Tq_RqMx 1;
BA_ "U_P702_MY2021_Rx" SG_ 531 PrplWhlTot_Tq_RqMx 1;
BA_ "U_T6_MCA_MY2020_Rx" SG_ 531 PrplWhlTot_Tq_RqMx 1;
BA_ "U_CX727_MY2021_Tx" SG_ 531 PrplWhlTot_Tq_RqMx 1;
BA_ "U_P702_MY2021_Tx" SG_ 531 PrplWhlTot_Tq_RqMx 1;
BA_ "CrossOver_InfoCAN" SG_ 531 LscmbbBaSensInc_B_Actl 1;
BA_ "U_P702_MY2021_Tx" SG_ 531 LscmbbBaSensInc_B_Actl 1;
BA_ "CrossOver_InfoCAN" SG_ 531 CmbbBrkDis_B_Actl 1;
BA_ "U_CX727_MY2021_Rx" SG_ 531 CmbbBrkDis_B_Actl 1;
BA_ "U_P702_MY2021_Rx" SG_ 531 CmbbBrkDis_B_Actl 1;
BA_ "U_CX727_MY2021_Tx" SG_ 531 CmbbBrkDis_B_Actl 1;
BA_ "U_P702_MY2021_Tx" SG_ 531 CmbbBrkDis_B_Actl 1;
BA_ "CrossOver_InfoCAN" SG_ 531 CmbbDeny_B_ActlBrk 1;
BA_ "U_P702_MY2021_Rx" SG_ 531 CmbbDeny_B_ActlBrk 1;
BA_ "U_T6_MCA_MY2020_Rx" SG_ 531 CmbbDeny_B_ActlBrk 1;
BA_ "U_CX727_MY2021_Rx" SG_ 531 CmbbDeny_B_ActlBrk 1;
BA_ "U_CX727_MY2021_Tx" SG_ 531 CmbbDeny_B_ActlBrk 1;
BA_ "U_P702_MY2021_Tx" SG_ 531 CmbbDeny_B_ActlBrk 1;
BA_ "CrossOver_InfoCAN" SG_ 531 CcDis_B_Cmd 1;
BA_ "U_P702_MY2021_Rx" SG_ 531 CcDis_B_Cmd 1;
BA_ "U_T6_MCA_MY2020_Rx" SG_ 531 CcDis_B_Cmd 1;
BA_ "U_CX727_MY2021_Tx" SG_ 531 CcDis_B_Cmd 1;
BA_ "U_P702_MY2021_Tx" SG_ 531 CcDis_B_Cmd 1;
BA_ "CrossOver_InfoCAN" SG_ 531 VehLongOvrGnd_A_Est 1;
BA_ "GenSigStartValueInteger" SG_ 531 VehLongOvrGnd_A_Est 511;
BA_ "U_P702_MY2021_Rx" SG_ 531 VehLongOvrGnd_A_Est 1;
BA_ "U_CX727_MY2021_Tx" SG_ 531 VehLongOvrGnd_A_Est 1;
BA_ "U_P702_MY2021_Tx" SG_ 531 VehLongOvrGnd_A_Est 1;
BA_ "CrossOver_InfoCAN" SG_ 531 LscmbBrkPrchg_B_Actl 1;
BA_ "U_P702_MY2021_Tx" SG_ 531 LscmbBrkPrchg_B_Actl 1;
BA_ "CrossOver_InfoCAN" SG_ 531 AccStopActv_B_ActlBrk 1;
BA_ "U_P702_MY2021_Rx" SG_ 531 AccStopActv_B_ActlBrk 1;
BA_ "U_T6_MCA_MY2020_Rx" SG_ 531 AccStopActv_B_ActlBrk 1;
BA_ "U_CX727_MY2021_Tx" SG_ 531 AccStopActv_B_ActlBrk 1;
BA_ "U_P702_MY2021_Tx" SG_ 531 AccStopActv_B_ActlBrk 1;
BA_ "CrossOver_InfoCAN" SG_ 531 AccDis_B_ActlEpb 1;
BA_ "U_CX727_MY2021_Tx" SG_ 531 AccDis_B_ActlEpb 1;
BA_ "U_P702_MY2021_Tx" SG_ 531 AccDis_B_ActlEpb 1;
BA_ "WakeupSignal" SG_ 531 PrkBrkMsgTxt_D_Rq 1;
BA_ "CrossOver_InfoCAN" SG_ 531 PrkBrkMsgTxt_D_Rq 1;
BA_ "U_CX727_MY2021_Tx" SG_ 531 PrkBrkMsgTxt_D_Rq 1;
BA_ "U_P702_MY2021_Tx" SG_ 531 PrkBrkMsgTxt_D_Rq 1;
BA_ "CrossOver_InfoCAN" SG_ 531 PrkBrkStatus 1;
BA_ "GenSigStartValueInteger" SG_ 531 PrkBrkStatus 7;
BA_ "GenSigStartValue" SG_ 531 PrkBrkStatus 7;
BA_ "U_P702_MY2021_Rx" SG_ 531 PrkBrkStatus 1;
BA_ "U_T6_MCA_MY2020_Rx" SG_ 531 PrkBrkStatus 1;
BA_ "U_CX727_MY2021_Tx" SG_ 531 PrkBrkStatus 1;
BA_ "U_P702_MY2021_Tx" SG_ 531 PrkBrkStatus 1;
BA_ "ECGUsedRxSignal" SG_ 531 PrkBrkStatus 1;
BA_ "CrossOver_InfoCAN" SG_ 1034 VehicleGGCCData 1;
BA_ "U_P702_MY2021_Rx" SG_ 1034 VehicleGGCCData 1;
BA_ "U_T6_MCA_MY2020_Rx" SG_ 1034 VehicleGGCCData 1;
BA_ "U_CX727_MY2021_Rx" SG_ 1034 VehicleGGCCData 1;
BA_ "ECGUsedRxSignal" SG_ 1090 Mtr2State_D_ActlMntr 1;
BA_ "U_CX727_MY2021_Tx" SG_ 1090 Mtr2State_D_ActlMntr 1;
BA_ "GenSigStartValueInteger" SG_ 1090 Inv1Ain_I_ActlMntr 32766;
BA_ "GenSigStartValue" SG_ 1090 Inv1Ain_I_ActlMntr 32765;
BA_ "ECGUsedRxSignal" SG_ 1090 Inv1Ain_I_ActlMntr 1;
BA_ "U_CX727_MY2021_Tx" SG_ 1090 Inv1Ain_I_ActlMntr 1;
BA_ "ECGUsedRxSignal" SG_ 1090 HybVehMde_D_ActlMntr 1;
BA_ "U_CX727_MY2021_Tx" SG_ 1090 HybVehMde_D_ActlMntr 1;
BA_ "ECGUsedRxSignal" SG_ 1090 ChrgStat_D_ActlMntr 1;
BA_ "U_CX727_MY2021_Tx" SG_ 1090 ChrgStat_D_ActlMntr 1;
BA_ "CrossOver_InfoCAN" SG_ 1090 VehElRnge_L_Dsply 1;
BA_ "GenSigStartValueInteger" SG_ 1090 VehElRnge_L_Dsply 4095;
BA_ "GenSigStartValue" SG_ 1090 VehElRnge_L_Dsply 4093;
BA_ "U_P702_MY2021_Tx" SG_ 1090 VehElRnge_L_Dsply 1;
BA_ "ECGUsedRxSignal" SG_ 1090 VehElRnge_L_Dsply 1;
BA_ "U_P702_MY2021_Tx" SG_ 869 PwrFlowTxt_D_Dsply 1;
BA_ "U_P702_MY2021_Tx" SG_ 869 EngOnMsg2_D_Dsply 1;
BA_ "U_P702_MY2021_Tx" SG_ 869 EngOnMsg1_D_Dsply 1;
BA_ "U_P702_MY2021_Tx" SG_ 869 FuelMaintMde_D_Dsply 1;
BA_ "CrossOver_InfoCAN" SG_ 869 EffWhlLvl2_Pc_Dsply 1;
BA_ "GenSigStartValueInteger" SG_ 869 EffWhlLvl2_Pc_Dsply 511;
BA_ "U_P702_MY2021_Tx" SG_ 869 EffWhlLvl2_Pc_Dsply 1;
BA_ "CrossOver_InfoCAN" SG_ 869 EffWhlThres_Pc_Dsply 1;
BA_ "U_P702_MY2021_Tx" SG_ 869 EffWhlThres_Pc_Dsply 1;
BA_ "CrossOver_InfoCAN" SG_ 869 EngPwLvl_Pc_Dsply 1;
BA_ "U_P702_MY2021_Tx" SG_ 869 EngPwLvl_Pc_Dsply 1;
BA_ "CrossOver_InfoCAN" SG_ 869 EngActv_B_Dsply 1;
BA_ "U_P702_MY2021_Tx" SG_ 869 EngActv_B_Dsply 1;
BA_ "CrossOver_InfoCAN" SG_ 869 EffWhlThresOn_B_Dsply 1;
BA_ "U_P702_MY2021_Tx" SG_ 869 EffWhlThresOn_B_Dsply 1;
BA_ "GenSigSendType" SG_ 374 GearEngag_D_Actl 3;
BA_ "U_P702_MY2021_Tx" SG_ 374 GearEngag_D_Actl 1;
BA_ "GenSigStartValueInteger" SG_ 374 TrnRng_D_Rq 14;
BA_ "ContentDependant" SG_ 374 TrnRng_D_Rq 1;
BA_ "GenSigStartValue" SG_ 374 TrnRng_D_Rq 14;
BA_ "GenSigSendType" SG_ 374 TrnRng_D_Rq 3;
BA_ "U_P702_MY2021_Rx" SG_ 374 TrnRng_D_Rq 1;
BA_ "U_T6_MCA_MY2020_Rx" SG_ 374 TrnRng_D_Rq 1;
BA_ "U_P702_MY2021_Tx" SG_ 374 TrnRng_D_Rq 1;
BA_ "U_T6_MCA_MY2020_Tx" SG_ 374 TrnRng_D_Rq 1;
BA_ "ContentDependant" SG_ 374 TrnPrkSys_D_Actl 1;
BA_ "GenSigSendType" SG_ 374 TrnPrkSys_D_Actl 3;
BA_ "U_P702_MY2021_Rx" SG_ 374 TrnPrkSys_D_Actl 1;
BA_ "U_T6_MCA_MY2020_Rx" SG_ 374 TrnPrkSys_D_Actl 1;
BA_ "U_P702_MY2021_Tx" SG_ 374 TrnPrkSys_D_Actl 1;
BA_ "U_T6_MCA_MY2020_Tx" SG_ 374 TrnPrkSys_D_Actl 1;
BA_ "ContentDependant" SG_ 374 GearLvr_D_ActlDrv 1;
BA_ "GenSigSendType" SG_ 374 GearLvr_D_ActlDrv 3;
BA_ "U_P702_MY2021_Rx" SG_ 374 GearLvr_D_ActlDrv 1;
BA_ "U_T6_MCA_MY2020_Rx" SG_ 374 GearLvr_D_ActlDrv 1;
BA_ "U_P702_MY2021_Tx" SG_ 374 GearLvr_D_ActlDrv 1;
BA_ "U_T6_MCA_MY2020_Tx" SG_ 374 GearLvr_D_ActlDrv 1;
BA_ "ContentDependant" SG_ 374 GearPos_No_Cs 1;
BA_ "MetaData" SG_ 374 GearPos_No_Cs 1;
BA_ "U_P702_MY2021_Rx" SG_ 374 GearPos_No_Cs 1;
BA_ "U_T6_MCA_MY2020_Rx" SG_ 374 GearPos_No_Cs 1;
BA_ "U_CX727_MY2021_Rx" SG_ 374 GearPos_No_Cs 1;
BA_ "U_P702_MY2021_Tx" SG_ 374 GearPos_No_Cs 1;
BA_ "U_T6_MCA_MY2020_Tx" SG_ 374 GearPos_No_Cs 1;
BA_ "CrossOver_InfoCAN" SG_ 374 GearPos_D_Trg 1;
BA_ "GenSigStartValueInteger" SG_ 374 GearPos_D_Trg 15;
BA_ "ContentDependant" SG_ 374 GearPos_D_Trg 1;
BA_ "GenSigStartValue" SG_ 374 GearPos_D_Trg 15;
BA_ "GenSigSendType" SG_ 374 GearPos_D_Trg 3;
BA_ "U_P702_MY2021_Rx" SG_ 374 GearPos_D_Trg 1;
BA_ "U_T6_MCA_MY2020_Rx" SG_ 374 GearPos_D_Trg 1;
BA_ "U_CX727_MY2021_Rx" SG_ 374 GearPos_D_Trg 1;
BA_ "U_P702_MY2021_Tx" SG_ 374 GearPos_D_Trg 1;
BA_ "U_T6_MCA_MY2020_Tx" SG_ 374 GearPos_D_Trg 1;
BA_ "ContentDependant" SG_ 374 GearPos_No_Cnt 1;
BA_ "MetaData" SG_ 374 GearPos_No_Cnt 1;
BA_ "U_P702_MY2021_Rx" SG_ 374 GearPos_No_Cnt 1;
BA_ "U_T6_MCA_MY2020_Rx" SG_ 374 GearPos_No_Cnt 1;
BA_ "U_CX727_MY2021_Rx" SG_ 374 GearPos_No_Cnt 1;
BA_ "U_P702_MY2021_Tx" SG_ 374 GearPos_No_Cnt 1;
BA_ "U_T6_MCA_MY2020_Tx" SG_ 374 GearPos_No_Cnt 1;
BA_ "U_P702_MY2021_Tx" SG_ 374 TrnIgnOffDly_T_Rq 1;
BA_ "U_T6_MCA_MY2020_Tx" SG_ 374 TrnIgnOffDly_T_Rq 1;
BA_ "GenSigStartValueInteger" SG_ 374 GearPos_D_Actl 15;
BA_ "ContentDependant" SG_ 374 GearPos_D_Actl 1;
BA_ "GenSigStartValue" SG_ 374 GearPos_D_Actl 15;
BA_ "GenSigSendType" SG_ 374 GearPos_D_Actl 3;
BA_ "U_P702_MY2021_Rx" SG_ 374 GearPos_D_Actl 1;
BA_ "U_T6_MCA_MY2020_Rx" SG_ 374 GearPos_D_Actl 1;
BA_ "U_CX727_MY2021_Rx" SG_ 374 GearPos_D_Actl 1;
BA_ "U_P702_MY2021_Tx" SG_ 374 GearPos_D_Actl 1;
BA_ "U_T6_MCA_MY2020_Tx" SG_ 374 GearPos_D_Actl 1;
BA_ "ContentDependant" SG_ 603 WhlDirAvgDrv_D_Actl 1;
BA_ "U_P702_MY2021_Tx" SG_ 603 WhlDirAvgDrv_D_Actl 1;
BA_ "ContentDependant" SG_ 603 PrplTqMnRgen_B_Actl 1;
BA_ "U_P702_MY2021_Tx" SG_ 603 PrplTqMnRgen_B_Actl 1;
BA_ "ContentDependant" SG_ 603 BattTracCnnct_D_Rq 1;
BA_ "U_P702_MY2021_Tx" SG_ 603 BattTracCnnct_D_Rq 1;
BA_ "CrossOver_InfoCAN" SG_ 872 PlgActvArb_B_Dsply 1;
BA_ "U_P702_MY2021_Tx" SG_ 872 PlgActvArb_B_Dsply 1;
BA_ "ECGUsedRxSignal" SG_ 872 PlgActvArb_B_Dsply 1;
BA_ "U_P702_MY2021_Tx" SG_ 872 HybMdeStat_D_Dsply 1;
BA_ "ECGUsedRxSignal" SG_ 872 HybMdeStat_D_Dsply 1;
BA_ "ContentDependant" SG_ 560 SelDrvMdeSwtch_D_Stat3 1;
BA_ "U_P702_MY2021_Rx" SG_ 560 SelDrvMdeSwtch_D_Stat3 1;
BA_ "U_P702_MY2021_Tx" SG_ 560 SelDrvMdeSwtch_D_Stat3 1;
BA_ "U_T6_MCA_MY2020_Tx" SG_ 560 SelDrvMdeSwtch_D_Stat3 1;
BA_ "CrossOver_InfoCAN" SG_ 560 TrnSrvcRqd_B_Rq 1;
BA_ "ContentDependant" SG_ 560 TrnSrvcRqd_B_Rq 1;
BA_ "U_P702_MY2021_Tx" SG_ 560 TrnSrvcRqd_B_Rq 1;
BA_ "U_T6_MCA_MY2020_Tx" SG_ 560 TrnSrvcRqd_B_Rq 1;
BA_ "ECGUsedRxSignal" SG_ 560 TrnSrvcRqd_B_Rq 1;
BA_ "ContentDependant" SG_ 560 TrnShifActv_B_Actl 1;
BA_ "U_P702_MY2021_Rx" SG_ 560 TrnShifActv_B_Actl 1;
BA_ "U_T6_MCA_MY2020_Rx" SG_ 560 TrnShifActv_B_Actl 1;
BA_ "U_CX727_MY2021_Rx" SG_ 560 TrnShifActv_B_Actl 1;
BA_ "U_P702_MY2021_Tx" SG_ 560 TrnShifActv_B_Actl 1;
BA_ "U_T6_MCA_MY2020_Tx" SG_ 560 TrnShifActv_B_Actl 1;
BA_ "CrossOver_InfoCAN" SG_ 560 GearLvrPos_D_Actl 1;
BA_ "GenSigStartValueInteger" SG_ 560 GearLvrPos_D_Actl 14;
BA_ "GenSigStartValue" SG_ 560 GearLvrPos_D_Actl 14;
BA_ "U_P702_MY2021_Rx" SG_ 560 GearLvrPos_D_Actl 1;
BA_ "U_T6_MCA_MY2020_Rx" SG_ 560 GearLvrPos_D_Actl 1;
BA_ "U_CX727_MY2021_Rx" SG_ 560 GearLvrPos_D_Actl 1;
BA_ "U_P702_MY2021_Tx" SG_ 560 GearLvrPos_D_Actl 1;
BA_ "U_T6_MCA_MY2020_Tx" SG_ 560 GearLvrPos_D_Actl 1;
BA_ "GenSigStartValueInteger" SG_ 560 GboxOil_Te_Actl 254;
BA_ "ContentDependant" SG_ 560 GboxOil_Te_Actl 1;
BA_ "GenSigStartValue" SG_ 560 GboxOil_Te_Actl 254;
BA_ "U_P702_MY2021_Rx" SG_ 560 GboxOil_Te_Actl 1;
BA_ "U_T6_MCA_MY2020_Rx" SG_ 560 GboxOil_Te_Actl 1;
BA_ "U_P702_MY2021_Tx" SG_ 560 GboxOil_Te_Actl 1;
BA_ "U_T6_MCA_MY2020_Tx" SG_ 560 GboxOil_Te_Actl 1;
BA_ "GenSigStartValueInteger" SG_ 369 TrnIpcDsplyRng2_D_Actl 15;
BA_ "GenSigStartValue" SG_ 369 TrnIpcDsplyRng2_D_Actl 15;
BA_ "U_P702_MY2021_Tx" SG_ 369 TrnIpcDsplyRng2_D_Actl 1;
BA_ "U_T6_MCA_MY2020_Tx" SG_ 369 TrnIpcDsplyRng2_D_Actl 1;
BA_ "U_P702_MY2021_Tx" SG_ 369 TrnIpcDsplyRng_D_Stat 1;
BA_ "U_T6_MCA_MY2020_Tx" SG_ 369 TrnIpcDsplyRng_D_Stat 1;
BA_ "CrossOver_InfoCAN" SG_ 369 TrnIpcDsplyGear_D_Actl 1;
BA_ "GenSigStartValueInteger" SG_ 369 TrnIpcDsplyGear_D_Actl 15;
BA_ "GenSigStartValue" SG_ 369 TrnIpcDsplyGear_D_Actl 15;
BA_ "U_P702_MY2021_Tx" SG_ 369 TrnIpcDsplyGear_D_Actl 1;
BA_ "U_T6_MCA_MY2020_Tx" SG_ 369 TrnIpcDsplyGear_D_Actl 1;
BA_ "WakeupSignal" SG_ 369 TrnIpcDsplyMde_D_Stat 1;
BA_ "CrossOver_InfoCAN" SG_ 369 TrnIpcDsplyMde_D_Stat 1;
BA_ "U_P702_MY2021_Tx" SG_ 369 TrnIpcDsplyMde_D_Stat 1;
BA_ "U_T6_MCA_MY2020_Tx" SG_ 369 TrnIpcDsplyMde_D_Stat 1;
BA_ "WakeupSignal" SG_ 369 TrnIpcDsplyMde_D_Actl 1;
BA_ "CrossOver_InfoCAN" SG_ 369 TrnIpcDsplyMde_D_Actl 1;
BA_ "U_P702_MY2021_Tx" SG_ 369 TrnIpcDsplyMde_D_Actl 1;
BA_ "U_T6_MCA_MY2020_Tx" SG_ 369 TrnIpcDsplyMde_D_Actl 1;
BA_ "CrossOver_InfoCAN" SG_ 369 TrnIpcDsplyGear_D_Stat 1;
BA_ "U_P702_MY2021_Tx" SG_ 369 TrnIpcDsplyGear_D_Stat 1;
BA_ "U_T6_MCA_MY2020_Tx" SG_ 369 TrnIpcDsplyGear_D_Stat 1;
BA_ "GenSigStartValueInteger" SG_ 92 TrnLvrV_D_Rq 1;
BA_ "GenSigStartValue" SG_ 92 TrnLvrV_D_Rq 1;
BA_ "GenSigSendType" SG_ 92 TrnLvrV_D_Rq 3;
BA_ "U_P702_MY2021_Tx" SG_ 92 TrnLvrV_D_Rq 1;
BA_ "U_T6_MCA_MY2020_Tx" SG_ 92 TrnLvrV_D_Rq 1;
BA_ "GenSigStartValueInteger" SG_ 92 TrnSbwSysHlth_D_Actl 1;
BA_ "ContentDependant" SG_ 92 TrnSbwSysHlth_D_Actl 1;
BA_ "GenSigStartValue" SG_ 92 TrnSbwSysHlth_D_Actl 1;
BA_ "GenSigSendType" SG_ 92 TrnSbwSysHlth_D_Actl 3;
BA_ "U_P702_MY2021_Tx" SG_ 92 TrnSbwSysHlth_D_Actl 1;
BA_ "U_T6_MCA_MY2020_Tx" SG_ 92 TrnSbwSysHlth_D_Actl 1;
BA_ "CrossOver_InfoCAN" SG_ 92 TrnGearNtmAllow_B_Stat 1;
BA_ "ContentDependant" SG_ 92 TrnGearNtmAllow_B_Stat 1;
BA_ "GenSigSendType" SG_ 92 TrnGearNtmAllow_B_Stat 3;
BA_ "U_P702_MY2021_Tx" SG_ 92 TrnGearNtmAllow_B_Stat 1;
BA_ "U_T6_MCA_MY2020_Tx" SG_ 92 TrnGearNtmAllow_B_Stat 1;
BA_ "WakeupSignal" SG_ 92 TrnDtpCmd_D_Actl 1;
BA_ "GenSigStartValueInteger" SG_ 92 TrnDtpCmd_D_Actl 1;
BA_ "ContentDependant" SG_ 92 TrnDtpCmd_D_Actl 1;
BA_ "GenSigStartValue" SG_ 92 TrnDtpCmd_D_Actl 1;
BA_ "GenSigSendType" SG_ 92 TrnDtpCmd_D_Actl 3;
BA_ "U_P702_MY2021_Tx" SG_ 92 TrnDtpCmd_D_Actl 1;
BA_ "U_T6_MCA_MY2020_Tx" SG_ 92 TrnDtpCmd_D_Actl 1;
BA_ "GenSigSendType" SG_ 92 GearSelLck_D_Rq 3;
BA_ "U_P702_MY2021_Tx" SG_ 92 GearSelLck_D_Rq 1;
BA_ "U_T6_MCA_MY2020_Tx" SG_ 92 GearSelLck_D_Rq 1;
BA_ "ContentDependant" SG_ 92 TrnGearCmd_No_Cs 1;
BA_ "MetaData" SG_ 92 TrnGearCmd_No_Cs 1;
BA_ "U_P702_MY2021_Tx" SG_ 92 TrnGearCmd_No_Cs 1;
BA_ "U_T6_MCA_MY2020_Tx" SG_ 92 TrnGearCmd_No_Cs 1;
BA_ "ContentDependant" SG_ 92 TrnValidGear_D_Cnfm 1;
BA_ "GenSigSendType" SG_ 92 TrnValidGear_D_Cnfm 3;
BA_ "U_P702_MY2021_Tx" SG_ 92 TrnValidGear_D_Cnfm 1;
BA_ "U_T6_MCA_MY2020_Tx" SG_ 92 TrnValidGear_D_Cnfm 1;
BA_ "ContentDependant" SG_ 92 TrnNtrlTowCmd_D_Actl 1;
BA_ "GenSigSendType" SG_ 92 TrnNtrlTowCmd_D_Actl 3;
BA_ "U_CX727_MY2021_Rx" SG_ 92 TrnNtrlTowCmd_D_Actl 1;
BA_ "U_P702_MY2021_Rx" SG_ 92 TrnNtrlTowCmd_D_Actl 1;
BA_ "U_P702_MY2021_Tx" SG_ 92 TrnNtrlTowCmd_D_Actl 1;
BA_ "U_T6_MCA_MY2020_Tx" SG_ 92 TrnNtrlTowCmd_D_Actl 1;
BA_ "ContentDependant" SG_ 92 TrnGearCmd_Pc_ActlPt 1;
BA_ "U_P702_MY2021_Tx" SG_ 92 TrnGearCmd_Pc_ActlPt 1;
BA_ "U_T6_MCA_MY2020_Tx" SG_ 92 TrnGearCmd_Pc_ActlPt 1;
BA_ "ContentDependant" SG_ 92 TrnGear_D_RqPt 1;
BA_ "GenSigSendType" SG_ 92 TrnGear_D_RqPt 3;
BA_ "U_P702_MY2021_Tx" SG_ 92 TrnGear_D_RqPt 1;
BA_ "U_T6_MCA_MY2020_Tx" SG_ 92 TrnGear_D_RqPt 1;
BA_ "ContentDependant" SG_ 92 TrnCmdState_B_Actl 1;
BA_ "GenSigSendType" SG_ 92 TrnCmdState_B_Actl 3;
BA_ "U_P702_MY2021_Tx" SG_ 92 TrnCmdState_B_Actl 1;
BA_ "U_T6_MCA_MY2020_Tx" SG_ 92 TrnCmdState_B_Actl 1;
BA_ "ContentDependant" SG_ 92 TrnCmdCnt_B_Actl 1;
BA_ "U_P702_MY2021_Tx" SG_ 92 TrnCmdCnt_B_Actl 1;
BA_ "U_T6_MCA_MY2020_Tx" SG_ 92 TrnCmdCnt_B_Actl 1;
BA_ "GenSigStartValueInteger" SG_ 92 PrkBrkActv_D_RqTrnGear 1;
BA_ "ContentDependant" SG_ 92 PrkBrkActv_D_RqTrnGear 1;
BA_ "GenSigStartValue" SG_ 92 PrkBrkActv_D_RqTrnGear 1;
BA_ "GenSigSendType" SG_ 92 PrkBrkActv_D_RqTrnGear 3;
BA_ "U_CX727_MY2021_Rx" SG_ 92 PrkBrkActv_D_RqTrnGear 1;
BA_ "U_P702_MY2021_Rx" SG_ 92 PrkBrkActv_D_RqTrnGear 1;
BA_ "U_P702_MY2021_Tx" SG_ 92 PrkBrkActv_D_RqTrnGear 1;
BA_ "U_T6_MCA_MY2020_Tx" SG_ 92 PrkBrkActv_D_RqTrnGear 1;
BA_ "CrossOver_InfoCAN" SG_ 92 TrnGearMsgTxt_D_Rq 1;
BA_ "ContentDependant" SG_ 92 TrnGearMsgTxt_D_Rq 1;
BA_ "GenSigSendType" SG_ 92 TrnGearMsgTxt_D_Rq 3;
BA_ "U_P702_MY2021_Tx" SG_ 92 TrnGearMsgTxt_D_Rq 1;
BA_ "U_T6_MCA_MY2020_Tx" SG_ 92 TrnGearMsgTxt_D_Rq 1;
BA_ "ContentDependant" SG_ 92 TrnGearCmd_No_Cnt 1;
BA_ "MetaData" SG_ 92 TrnGearCmd_No_Cnt 1;
BA_ "U_P702_MY2021_Tx" SG_ 92 TrnGearCmd_No_Cnt 1;
BA_ "U_T6_MCA_MY2020_Tx" SG_ 92 TrnGearCmd_No_Cnt 1;
BA_ "U_P702_MY2021_Tx" SG_ 1087 BattRgenLoChrg_D_RqEng 1;
BA_ "GenSigSendType" SG_ 1087 BattRgenLoChrg_D_RqEng 3;
BA_ "GenSigSendType" SG_ 1087 AdasLcObtclAbrt_B_Stat 3;
BA_ "U_P702_MY2021_Tx" SG_ 1087 BattRgenLoDChrg_D_RqEng 1;
BA_ "GenSigSendType" SG_ 1087 BattRgenLoDChrg_D_RqEng 3;
BA_ "U_T6_MCA_MY2020_Tx" SG_ 1087 AirDamPos_D_Stat 1;
BA_ "U_P702_MY2021_Tx" SG_ 1087 AirDamPos_D_Stat 1;
BA_ "U_P702_MY2021_Rx" SG_ 1087 AirDamPos_D_Stat 1;
BA_ "GenSigSendType" SG_ 1087 FapLcInhbt_B_Rq 3;
BA_ "U_P702_MY2021_Tx" SG_ 1087 FapLcInhbt_B_Rq 1;
BA_ "U_T6_MCA_MY2020_Tx" SG_ 1087 FapLcInhbt_B_Rq 1;
BA_ "GenSigSendType" SG_ 1087 FapLcStopHold_B_Rq 3;
BA_ "U_CX727_MY2021_Rx" SG_ 1087 FapLcStopHold_B_Rq 1;
BA_ "U_P702_MY2021_Rx" SG_ 1087 FapLcStopHold_B_Rq 1;
BA_ "U_P702_MY2021_Tx" SG_ 1087 FapLcStopHold_B_Rq 1;
BA_ "U_T6_MCA_MY2020_Tx" SG_ 1087 FapLcStopHold_B_Rq 1;
BA_ "GenSigSendType" SG_ 1087 FapLcPrchgBrk_B_Rq 3;
BA_ "U_CX727_MY2021_Rx" SG_ 1087 FapLcPrchgBrk_B_Rq 1;
BA_ "U_P702_MY2021_Rx" SG_ 1087 FapLcPrchgBrk_B_Rq 1;
BA_ "U_P702_MY2021_Tx" SG_ 1087 FapLcPrchgBrk_B_Rq 1;
BA_ "U_T6_MCA_MY2020_Tx" SG_ 1087 FapLcPrchgBrk_B_Rq 1;
BA_ "GenSigSendType" SG_ 1087 FapLcObstcl_B_Stat 3;
BA_ "U_P702_MY2021_Tx" SG_ 1087 FapLcObstcl_B_Stat 1;
BA_ "U_T6_MCA_MY2020_Tx" SG_ 1087 FapLcObstcl_B_Stat 1;
BA_ "GenSigSendType" SG_ 1087 FapLcMaxGrdInhbt_B_Stat 3;
BA_ "U_P702_MY2021_Tx" SG_ 1087 FapLcMaxGrdInhbt_B_Stat 1;
BA_ "U_T6_MCA_MY2020_Tx" SG_ 1087 FapLcMaxGrdInhbt_B_Stat 1;
BA_ "GenSigSendType" SG_ 1087 FapLcMaxGrdAbrt_B_Stat 3;
BA_ "U_P702_MY2021_Tx" SG_ 1087 FapLcMaxGrdAbrt_B_Stat 1;
BA_ "U_T6_MCA_MY2020_Tx" SG_ 1087 FapLcMaxGrdAbrt_B_Stat 1;
BA_ "GenSigSendType" SG_ 1087 FapLcActv_B_Stat 3;
BA_ "U_P702_MY2021_Tx" SG_ 1087 FapLcActv_B_Stat 1;
BA_ "U_T6_MCA_MY2020_Tx" SG_ 1087 FapLcActv_B_Stat 1;
BA_ "GenSigSendType" SG_ 1100 EngExhMdeQuiet_D2_Stat 3;
BA_ "U_T6_MCA_MY2020_Tx" SG_ 1100 HvacCmprLim_D_Stat 1;
BA_ "U_P702_MY2021_Tx" SG_ 1100 HvacCmprLim_D_Stat 1;
BA_ "GenSigStartValueInteger" SG_ 1100 WakeAlarm1_T_Rq 32767;
BA_ "GenSigStartValue" SG_ 1100 WakeAlarm1_T_Rq 32767;
BA_ "U_P702_MY2021_Tx" SG_ 1100 WakeAlarm1_T_Rq 1;
BA_ "U_T6_MCA_MY2020_Tx" SG_ 1100 WakeAlarm1_T_Rq 1;
BA_ "WakeupSignal" SG_ 1100 WakeAlarm1_B_Typ 1;
BA_ "GenSigSendType" SG_ 1100 WakeAlarm1_B_Typ 3;
BA_ "U_P702_MY2021_Tx" SG_ 1100 WakeAlarm1_B_Typ 1;
BA_ "U_T6_MCA_MY2020_Tx" SG_ 1100 WakeAlarm1_B_Typ 1;
BA_ "GenSigSendType" SG_ 1100 Veh_V_DsplyTrailCtlSet 3;
BA_ "U_P702_MY2021_Tx" SG_ 1100 Veh_V_DsplyTrailCtlSet 1;
BA_ "U_T6_MCA_MY2020_Tx" SG_ 1100 Veh_V_DsplyTrailCtlSet 1;
BA_ "GenSigSendType" SG_ 1100 TrailCtlPt_B_Falt 3;
BA_ "U_P702_MY2021_Rx" SG_ 1100 TrailCtlPt_B_Falt 1;
BA_ "U_P702_MY2021_Tx" SG_ 1100 TrailCtlPt_B_Falt 1;
BA_ "U_T6_MCA_MY2020_Tx" SG_ 1100 TrailCtlPt_B_Falt 1;
BA_ "GenSigSendType" SG_ 1100 AutoTowAllw_D_StatMnu 3;
BA_ "U_P702_MY2021_Tx" SG_ 1100 AutoTowAllw_D_StatMnu 1;
BA_ "GenSigSendType" SG_ 1100 AutoTowActv_B_Stat 3;
BA_ "U_P702_MY2021_Tx" SG_ 1100 AutoTowActv_B_Stat 1;
BA_ "GenSigStartValueInteger" SG_ 1100 GrossTrainWeight_M_Est 254;
BA_ "GenSigStartValue" SG_ 1100 GrossTrainWeight_M_Est 254;
BA_ "U_P702_MY2021_Rx" SG_ 1100 GrossTrainWeight_M_Est 1;
BA_ "U_T6_MCA_MY2020_Rx" SG_ 1100 GrossTrainWeight_M_Est 1;
BA_ "U_P702_MY2021_Tx" SG_ 1100 GrossTrainWeight_M_Est 1;
BA_ "U_T6_MCA_MY2020_Tx" SG_ 1100 GrossTrainWeight_M_Est 1;
BA_ "GenSigStartValueInteger" SG_ 1086 EngMnfld_P_Actl 2068;
BA_ "U_P702_MY2021_Tx" SG_ 1086 EngMnfld_P_Actl 1;
BA_ "U_T6_MCA_MY2020_Tx" SG_ 1086 EngMnfld_P_Actl 1;
BA_ "U_P702_MY2021_Tx" SG_ 1086 FuelPumpPwr_B_Rq 1;
BA_ "U_T6_MCA_MY2020_Tx" SG_ 1086 FuelPumpPwr_B_Rq 1;
BA_ "U_P702_MY2021_Tx" SG_ 1086 BattULoChrg_U_Cmd 1;
BA_ "U_T6_MCA_MY2020_Tx" SG_ 1086 BattULoChrg_U_Cmd 1;
BA_ "ContentDependant" SG_ 1086 ElLoadCtl_D_Rq 1;
BA_ "U_P702_MY2021_Tx" SG_ 1086 ElLoadCtl_D_Rq 1;
BA_ "U_T6_MCA_MY2020_Tx" SG_ 1086 ElLoadCtl_D_Rq 1;
BA_ "U_P702_MY2021_Tx" SG_ 1071 EngAout_N_Dsply 1;
BA_ "U_T6_MCA_MY2020_Tx" SG_ 1071 EngAout_N_Dsply 1;
BA_ "CrossOver_InfoCAN" SG_ 1071 CluPdl_PcRate_Actl 1;
BA_ "ContentDependant" SG_ 1071 CluPdl_PcRate_Actl 1;
BA_ "U_P702_MY2021_Tx" SG_ 1071 CluPdl_PcRate_Actl 1;
BA_ "U_T6_MCA_MY2020_Tx" SG_ 1071 CluPdl_PcRate_Actl 1;
BA_ "CrossOver_InfoCAN" SG_ 1071 CluPdlPosPcMeas_D_Qf 1;
BA_ "GenSigStartValueInteger" SG_ 1071 CluPdlPosPcMeas_D_Qf 1;
BA_ "ContentDependant" SG_ 1071 CluPdlPosPcMeas_D_Qf 1;
BA_ "MetaData" SG_ 1071 CluPdlPosPcMeas_D_Qf 1;
BA_ "GenSigStartValue" SG_ 1071 CluPdlPosPcMeas_D_Qf 1;
BA_ "U_P702_MY2021_Rx" SG_ 1071 CluPdlPosPcMeas_D_Qf 1;
BA_ "U_P702_MY2021_Tx" SG_ 1071 CluPdlPosPcMeas_D_Qf 1;
BA_ "U_T6_MCA_MY2020_Tx" SG_ 1071 CluPdlPosPcMeas_D_Qf 1;
BA_ "CrossOver_InfoCAN" SG_ 1071 CluPdlPos_Pc_Meas 1;
BA_ "ContentDependant" SG_ 1071 CluPdlPos_Pc_Meas 1;
BA_ "U_P702_MY2021_Rx" SG_ 1071 CluPdlPos_Pc_Meas 1;
BA_ "U_P702_MY2021_Tx" SG_ 1071 CluPdlPos_Pc_Meas 1;
BA_ "U_T6_MCA_MY2020_Tx" SG_ 1071 CluPdlPos_Pc_Meas 1;
BA_ "CrossOver_InfoCAN" SG_ 1071 EngAoutIdl_N_Ntrl 1;
BA_ "ContentDependant" SG_ 1071 EngAoutIdl_N_Ntrl 1;
BA_ "U_CX727_MY2021_Rx" SG_ 1071 EngAoutIdl_N_Ntrl 1;
BA_ "U_P702_MY2021_Rx" SG_ 1071 EngAoutIdl_N_Ntrl 1;
BA_ "U_P702_MY2021_Tx" SG_ 1071 EngAoutIdl_N_Ntrl 1;
BA_ "U_T6_MCA_MY2020_Tx" SG_ 1071 EngAoutIdl_N_Ntrl 1;
BA_ "U_T6_MCA_MY2020_Tx" SG_ 1069 SlMde_D_Stat 1;
BA_ "U_P702_MY2021_Tx" SG_ 1069 SlMde_D_Stat 1;
BA_ "U_T6_MCA_MY2020_Tx" SG_ 1069 SlMde_D_RqDsply 1;
BA_ "U_P702_MY2021_Tx" SG_ 1069 SlMde_D_RqDsply 1;
BA_ "U_T6_MCA_MY2020_Tx" SG_ 1069 IsaOffst_D_Stat 1;
BA_ "U_P702_MY2021_Tx" SG_ 1069 IsaOffst_D_Stat 1;
BA_ "CrossOver_InfoCAN" SG_ 1069 GrllShtrPos_D_Cmd 1;
BA_ "U_P702_MY2021_Tx" SG_ 1069 GrllShtrPos_D_Cmd 1;
BA_ "U_T6_MCA_MY2020_Tx" SG_ 1069 GrllShtrPos_D_Cmd 1;
BA_ "CrossOver_InfoCAN" SG_ 1069 GrllShtrPos_B_Falt 1;
BA_ "U_P702_MY2021_Tx" SG_ 1069 GrllShtrPos_B_Falt 1;
BA_ "U_T6_MCA_MY2020_Tx" SG_ 1069 GrllShtrPos_B_Falt 1;
BA_ "CrossOver_InfoCAN" SG_ 1069 ObdWarmUp_B_Complt 1;
BA_ "ContentDependant" SG_ 1069 ObdWarmUp_B_Complt 1;
BA_ "U_P702_MY2021_Tx" SG_ 1069 ObdWarmUp_B_Complt 1;
BA_ "CrossOver_InfoCAN" SG_ 1069 EngMsgTxt_D_Rq 1;
BA_ "ContentDependant" SG_ 1069 EngMsgTxt_D_Rq 1;
BA_ "U_P702_MY2021_Tx" SG_ 1069 EngMsgTxt_D_Rq 1;
BA_ "U_T6_MCA_MY2020_Tx" SG_ 1069 EngMsgTxt_D_Rq 1;
BA_ "CrossOver_InfoCAN" SG_ 1069 EngClnt_Te_ActlDiag 1;
BA_ "ContentDependant" SG_ 1069 EngClnt_Te_ActlDiag 1;
BA_ "U_P702_MY2021_Rx" SG_ 1069 EngClnt_Te_ActlDiag 1;
BA_ "U_T6_MCA_MY2020_Rx" SG_ 1069 EngClnt_Te_ActlDiag 1;
BA_ "U_P702_MY2021_Tx" SG_ 1069 EngClnt_Te_ActlDiag 1;
BA_ "U_T6_MCA_MY2020_Tx" SG_ 1069 EngClnt_Te_ActlDiag 1;
BA_ "CrossOver_InfoCAN" SG_ 1069 EngLoad_Pc_CalcDiag 1;
BA_ "ContentDependant" SG_ 1069 EngLoad_Pc_CalcDiag 1;
BA_ "U_P702_MY2021_Rx" SG_ 1069 EngLoad_Pc_CalcDiag 1;
BA_ "U_T6_MCA_MY2020_Rx" SG_ 1069 EngLoad_Pc_CalcDiag 1;
BA_ "U_P702_MY2021_Tx" SG_ 1069 EngLoad_Pc_CalcDiag 1;
BA_ "U_T6_MCA_MY2020_Tx" SG_ 1069 EngLoad_Pc_CalcDiag 1;
BA_ "CrossOver_InfoCAN" SG_ 1069 EngAirIn_Te_Actl 1;
BA_ "U_P702_MY2021_Rx" SG_ 1069 EngAirIn_Te_Actl 1;
BA_ "U_T6_MCA_MY2020_Rx" SG_ 1069 EngAirIn_Te_Actl 1;
BA_ "U_P702_MY2021_Tx" SG_ 1069 EngAirIn_Te_Actl 1;
BA_ "U_T6_MCA_MY2020_Tx" SG_ 1069 EngAirIn_Te_Actl 1;
BA_ "CrossOver_InfoCAN" SG_ 1069 ApedPos_Pc_ActlDiag 1;
BA_ "ContentDependant" SG_ 1069 ApedPos_Pc_ActlDiag 1;
BA_ "U_P702_MY2021_Rx" SG_ 1069 ApedPos_Pc_ActlDiag 1;
BA_ "U_T6_MCA_MY2020_Rx" SG_ 1069 ApedPos_Pc_ActlDiag 1;
BA_ "U_P702_MY2021_Tx" SG_ 1069 ApedPos_Pc_ActlDiag 1;
BA_ "U_T6_MCA_MY2020_Tx" SG_ 1069 ApedPos_Pc_ActlDiag 1;
BA_ "U_P702_MY2021_Tx" SG_ 1060 RearDiffOilTeWarn_B_Rq 1;
BA_ "U_T6_MCA_MY2020_Tx" SG_ 1060 RearDiffOilTeWarn_B_Rq 1;
BA_ "GenSigStartValueInteger" SG_ 1060 RearDiffOil_Te_Actl 77;
BA_ "GenSigStartValue" SG_ 1060 RearDiffOil_Te_Actl 77;
BA_ "U_P702_MY2021_Tx" SG_ 1060 RearDiffOil_Te_Actl 1;
BA_ "U_T6_MCA_MY2020_Tx" SG_ 1060 RearDiffOil_Te_Actl 1;
BA_ "U_P702_MY2021_Tx" SG_ 1060 BpedDrvMsgTxt_B_Dsply 1;
BA_ "U_T6_MCA_MY2020_Tx" SG_ 1060 BpedDrvMsgTxt_B_Dsply 1;
BA_ "GenSigStartValueInteger" SG_ 1060 FuelLvl_Pc_DsplyEng 48;
BA_ "U_P702_MY2021_Tx" SG_ 1060 FuelLvl_Pc_DsplyEng 1;
BA_ "U_T6_MCA_MY2020_Tx" SG_ 1060 FuelLvl_Pc_DsplyEng 1;
BA_ "U_P702_MY2021_Tx" SG_ 1060 FuelLvlWarn_D_ActlEng 1;
BA_ "U_T6_MCA_MY2020_Tx" SG_ 1060 FuelLvlWarn_D_ActlEng 1;
BA_ "U_P702_MY2021_Tx" SG_ 1060 FuelRange_L_DsplyEng 1;
BA_ "U_T6_MCA_MY2020_Tx" SG_ 1060 FuelRange_L_DsplyEng 1;
BA_ "U_P702_MY2021_Rx" SG_ 1060 SelDrvMdePt_D_Stat 1;
BA_ "U_P702_MY2021_Tx" SG_ 1060 SelDrvMdePt_D_Stat 1;
BA_ "U_T6_MCA_MY2020_Tx" SG_ 1060 SelDrvMdePt_D_Stat 1;
BA_ "CrossOver_InfoCAN" SG_ 1057 FohEng_D_Rq 1;
BA_ "GenSigStartValueInteger" SG_ 1057 FohEng_D_Rq 2;
BA_ "ContentDependant" SG_ 1057 FohEng_D_Rq 1;
BA_ "GenSigStartValue" SG_ 1057 FohEng_D_Rq 2;
BA_ "U_P702_MY2021_Tx" SG_ 1057 FohEng_D_Rq 1;
BA_ "U_T6_MCA_MY2020_Tx" SG_ 1057 FohEng_D_Rq 1;
BA_ "U_P702_MY2021_Tx" SG_ 1057 EngIdlShutDwnTxt_D_Rq 1;
BA_ "U_T6_MCA_MY2020_Tx" SG_ 1057 EngIdlShutDwnTxt_D_Rq 1;
BA_ "CrossOver_InfoCAN" SG_ 1057 EngIdlShutDown_D_Stat 1;
BA_ "ContentDependant" SG_ 1057 EngIdlShutDown_D_Stat 1;
BA_ "U_P702_MY2021_Tx" SG_ 1057 EngIdlShutDown_D_Stat 1;
BA_ "U_T6_MCA_MY2020_Tx" SG_ 1057 EngIdlShutDown_D_Stat 1;
BA_ "ECGUsedRxSignal" SG_ 1057 EngIdlShutDown_D_Stat 1;
BA_ "CrossOver_InfoCAN" SG_ 1057 FUEL_ALCOHOL_PERCNT 1;
BA_ "GenSigStartValueInteger" SG_ 1057 FUEL_ALCOHOL_PERCNT 255;
BA_ "ContentDependant" SG_ 1057 FUEL_ALCOHOL_PERCNT 1;
BA_ "GenSigStartValue" SG_ 1057 FUEL_ALCOHOL_PERCNT 255;
BA_ "U_P702_MY2021_Tx" SG_ 1057 FUEL_ALCOHOL_PERCNT 1;
BA_ "U_T6_MCA_MY2020_Tx" SG_ 1057 FUEL_ALCOHOL_PERCNT 1;
BA_ "CrossOver_InfoCAN" SG_ 1057 TrnTotTq_Rt_Est 1;
BA_ "ContentDependant" SG_ 1057 TrnTotTq_Rt_Est 1;
BA_ "U_P702_MY2021_Tx" SG_ 1057 TrnTotTq_Rt_Est 1;
BA_ "U_T6_MCA_MY2020_Tx" SG_ 1057 TrnTotTq_Rt_Est 1;
BA_ "CrossOver_InfoCAN" SG_ 1057 TrnTotLss_Tq_Est 1;
BA_ "ContentDependant" SG_ 1057 TrnTotLss_Tq_Est 1;
BA_ "U_P702_MY2021_Tx" SG_ 1057 TrnTotLss_Tq_Est 1;
BA_ "U_T6_MCA_MY2020_Tx" SG_ 1057 TrnTotLss_Tq_Est 1;
BA_ "CrossOver_InfoCAN" SG_ 1057 ECMMILRequest 1;
BA_ "U_P702_MY2021_Tx" SG_ 1057 ECMMILRequest 1;
BA_ "U_T6_MCA_MY2020_Tx" SG_ 1057 ECMMILRequest 1;
BA_ "CrossOver_InfoCAN" SG_ 1057 AirCondFluidHi_P_Actl 1;
BA_ "U_P702_MY2021_Tx" SG_ 1057 AirCondFluidHi_P_Actl 1;
BA_ "U_T6_MCA_MY2020_Tx" SG_ 1057 AirCondFluidHi_P_Actl 1;
BA_ "CrossOver_InfoCAN" SG_ 1057 OilPressureWarning 1;
BA_ "U_P702_MY2021_Tx" SG_ 1057 OilPressureWarning 1;
BA_ "U_T6_MCA_MY2020_Tx" SG_ 1057 OilPressureWarning 1;
BA_ "CrossOver_InfoCAN" SG_ 1057 VehVLimStat_D_Actl 1;
BA_ "ContentDependant" SG_ 1057 VehVLimStat_D_Actl 1;
BA_ "U_P702_MY2021_Rx" SG_ 1057 VehVLimStat_D_Actl 1;
BA_ "U_T6_MCA_MY2020_Rx" SG_ 1057 VehVLimStat_D_Actl 1;
BA_ "U_P702_MY2021_Tx" SG_ 1057 VehVLimStat_D_Actl 1;
BA_ "U_T6_MCA_MY2020_Tx" SG_ 1057 VehVLimStat_D_Actl 1;
BA_ "CrossOver_InfoCAN" SG_ 1057 VehVLimActv_B_Actl 1;
BA_ "ContentDependant" SG_ 1057 VehVLimActv_B_Actl 1;
BA_ "U_P702_MY2021_Rx" SG_ 1057 VehVLimActv_B_Actl 1;
BA_ "U_T6_MCA_MY2020_Rx" SG_ 1057 VehVLimActv_B_Actl 1;
BA_ "U_P702_MY2021_Tx" SG_ 1057 VehVLimActv_B_Actl 1;
BA_ "U_T6_MCA_MY2020_Tx" SG_ 1057 VehVLimActv_B_Actl 1;
BA_ "CrossOver_InfoCAN" SG_ 1057 CoolantFanStepAct 1;
BA_ "U_P702_MY2021_Tx" SG_ 1057 CoolantFanStepAct 1;
BA_ "U_T6_MCA_MY2020_Tx" SG_ 1057 CoolantFanStepAct 1;
BA_ "ContentDependant" SG_ 562 GearNtrl_No_Cs 1;
BA_ "MetaData" SG_ 562 GearNtrl_No_Cs 1;
BA_ "U_P702_MY2021_Tx" SG_ 562 GearNtrl_No_Cs 1;
BA_ "U_T6_MCA_MY2020_Tx" SG_ 562 GearNtrl_No_Cs 1;
BA_ "ContentDependant" SG_ 562 GearNtrl_No_Cnt 1;
BA_ "MetaData" SG_ 562 GearNtrl_No_Cnt 1;
BA_ "U_P702_MY2021_Tx" SG_ 562 GearNtrl_No_Cnt 1;
BA_ "U_T6_MCA_MY2020_Tx" SG_ 562 GearNtrl_No_Cnt 1;
BA_ "GenSigStartValueInteger" SG_ 562 GearNtrl_D_Stat 2;
BA_ "GenSigStartValue" SG_ 562 GearNtrl_D_Stat 2;
BA_ "GenSigSendType" SG_ 562 GearNtrl_D_Stat 3;
BA_ "U_P702_MY2021_Tx" SG_ 562 GearNtrl_D_Stat 1;
BA_ "U_T6_MCA_MY2020_Tx" SG_ 562 GearNtrl_D_Stat 1;
BA_ "CrossOver_InfoCAN" SG_ 516 EngAoutNActl_D_QF 1;
BA_ "GenSigStartValueInteger" SG_ 516 EngAoutNActl_D_QF 1;
BA_ "MetaData" SG_ 516 EngAoutNActl_D_QF 1;
BA_ "GenSigStartValue" SG_ 516 EngAoutNActl_D_QF 1;
BA_ "U_P702_MY2021_Rx" SG_ 516 EngAoutNActl_D_QF 1;
BA_ "U_T6_MCA_MY2020_Rx" SG_ 516 EngAoutNActl_D_QF 1;
BA_ "U_P702_MY2021_Tx" SG_ 516 EngAoutNActl_D_QF 1;
BA_ "U_T6_MCA_MY2020_Tx" SG_ 516 EngAoutNActl_D_QF 1;
BA_ "CrossOver_InfoCAN" SG_ 516 EngAout3_N_Actl 1;
BA_ "ContentDependant" SG_ 516 EngAout3_N_Actl 1;
BA_ "U_P702_MY2021_Tx" SG_ 516 EngAout3_N_Actl 1;
BA_ "CrossOver_InfoCAN" SG_ 516 ApedPos_PcRate_ActlArb 1;
BA_ "U_P702_MY2021_Rx" SG_ 516 ApedPos_PcRate_ActlArb 1;
BA_ "U_T6_MCA_MY2020_Rx" SG_ 516 ApedPos_PcRate_ActlArb 1;
BA_ "U_P702_MY2021_Tx" SG_ 516 ApedPos_PcRate_ActlArb 1;
BA_ "U_T6_MCA_MY2020_Tx" SG_ 516 ApedPos_PcRate_ActlArb 1;
BA_ "CrossOver_InfoCAN" SG_ 516 ApedPos_Pc_ActlArb 1;
BA_ "U_P702_MY2021_Rx" SG_ 516 ApedPos_Pc_ActlArb 1;
BA_ "U_T6_MCA_MY2020_Rx" SG_ 516 ApedPos_Pc_ActlArb 1;
BA_ "U_CX727_MY2021_Rx" SG_ 516 ApedPos_Pc_ActlArb 1;
BA_ "U_P702_MY2021_Tx" SG_ 516 ApedPos_Pc_ActlArb 1;
BA_ "U_T6_MCA_MY2020_Tx" SG_ 516 ApedPos_Pc_ActlArb 1;
BA_ "ECGUsedRxSignal" SG_ 516 ApedPos_Pc_ActlArb 1;
BA_ "CrossOver_InfoCAN" SG_ 516 ApedPosPcActl_D_Qf 1;
BA_ "GenSigStartValueInteger" SG_ 516 ApedPosPcActl_D_Qf 1;
BA_ "MetaData" SG_ 516 ApedPosPcActl_D_Qf 1;
BA_ "GenSigStartValue" SG_ 516 ApedPosPcActl_D_Qf 1;
BA_ "U_P702_MY2021_Rx" SG_ 516 ApedPosPcActl_D_Qf 1;
BA_ "U_T6_MCA_MY2020_Rx" SG_ 516 ApedPosPcActl_D_Qf 1;
BA_ "U_CX727_MY2021_Rx" SG_ 516 ApedPosPcActl_D_Qf 1;
BA_ "U_P702_MY2021_Tx" SG_ 516 ApedPosPcActl_D_Qf 1;
BA_ "U_T6_MCA_MY2020_Tx" SG_ 516 ApedPosPcActl_D_Qf 1;
BA_ "CrossOver_InfoCAN" SG_ 516 EngAout_N_Actl 1;
BA_ "U_P702_MY2021_Rx" SG_ 516 EngAout_N_Actl 1;
BA_ "U_T6_MCA_MY2020_Rx" SG_ 516 EngAout_N_Actl 1;
BA_ "U_CX727_MY2021_Rx" SG_ 516 EngAout_N_Actl 1;
BA_ "U_P702_MY2021_Tx" SG_ 516 EngAout_N_Actl 1;
BA_ "U_T6_MCA_MY2020_Tx" SG_ 516 EngAout_N_Actl 1;
BA_ "ECGUsedRxSignal" SG_ 516 EngAout_N_Actl 1;
BA_ "CrossOver_InfoCAN" SG_ 516 ApedPosPcActl_No_Cnt 1;
BA_ "ContentDependant" SG_ 516 ApedPosPcActl_No_Cnt 1;
BA_ "MetaData" SG_ 516 ApedPosPcActl_No_Cnt 1;
BA_ "U_P702_MY2021_Tx" SG_ 516 ApedPosPcActl_No_Cnt 1;
BA_ "U_T6_MCA_MY2020_Tx" SG_ 516 ApedPosPcActl_No_Cnt 1;
BA_ "CrossOver_InfoCAN" SG_ 516 ApedPosPcActl_No_Cs 1;
BA_ "ContentDependant" SG_ 516 ApedPosPcActl_No_Cs 1;
BA_ "MetaData" SG_ 516 ApedPosPcActl_No_Cs 1;
BA_ "U_P702_MY2021_Tx" SG_ 516 ApedPosPcActl_No_Cs 1;
BA_ "U_T6_MCA_MY2020_Tx" SG_ 516 ApedPosPcActl_No_Cs 1;
BA_ "U_P702_MY2021_Tx" SG_ 514 StrtrMtrDlyStrt_B_Stat 1;
BA_ "U_T6_MCA_MY2020_Tx" SG_ 514 StrtrMtrDlyStrt_B_Stat 1;
BA_ "U_P702_MY2021_Rx" SG_ 514 VehVTrlrAid_B_Avail 1;
BA_ "U_P702_MY2021_Tx" SG_ 514 VehVTrlrAid_B_Avail 1;
BA_ "U_T6_MCA_MY2020_Tx" SG_ 514 VehVTrlrAid_B_Avail 1;
BA_ "CrossOver_InfoCAN" SG_ 514 StrtrMtrCtlMsgTxt_D_Rq 1;
BA_ "U_P702_MY2021_Tx" SG_ 514 StrtrMtrCtlMsgTxt_D_Rq 1;
BA_ "U_T6_MCA_MY2020_Tx" SG_ 514 StrtrMtrCtlMsgTxt_D_Rq 1;
BA_ "CrossOver_InfoCAN" SG_ 514 VehVActlEng_No_Cs 1;
BA_ "MetaData" SG_ 514 VehVActlEng_No_Cs 1;
BA_ "U_CX727_MY2021_Rx" SG_ 514 VehVActlEng_No_Cs 1;
BA_ "U_P702_MY2021_Rx" SG_ 514 VehVActlEng_No_Cs 1;
BA_ "U_P702_MY2021_Tx" SG_ 514 VehVActlEng_No_Cs 1;
BA_ "U_T6_MCA_MY2020_Tx" SG_ 514 VehVActlEng_No_Cs 1;
BA_ "CrossOver_InfoCAN" SG_ 514 VehVActlEng_No_Cnt 1;
BA_ "MetaData" SG_ 514 VehVActlEng_No_Cnt 1;
BA_ "U_CX727_MY2021_Rx" SG_ 514 VehVActlEng_No_Cnt 1;
BA_ "U_P702_MY2021_Rx" SG_ 514 VehVActlEng_No_Cnt 1;
BA_ "U_P702_MY2021_Tx" SG_ 514 VehVActlEng_No_Cnt 1;
BA_ "U_T6_MCA_MY2020_Tx" SG_ 514 VehVActlEng_No_Cnt 1;
BA_ "CrossOver_InfoCAN" SG_ 514 Veh_V_RqCcSet 1;
BA_ "U_P702_MY2021_Rx" SG_ 514 Veh_V_RqCcSet 1;
BA_ "U_T6_MCA_MY2020_Rx" SG_ 514 Veh_V_RqCcSet 1;
BA_ "U_CX727_MY2021_Rx" SG_ 514 Veh_V_RqCcSet 1;
BA_ "U_P702_MY2021_Tx" SG_ 514 Veh_V_RqCcSet 1;
BA_ "U_T6_MCA_MY2020_Tx" SG_ 514 Veh_V_RqCcSet 1;
BA_ "CrossOver_InfoCAN" SG_ 514 VehVActlEng_D_Qf 1;
BA_ "MetaData" SG_ 514 VehVActlEng_D_Qf 1;
BA_ "U_P702_MY2021_Rx" SG_ 514 VehVActlEng_D_Qf 1;
BA_ "U_T6_MCA_MY2020_Rx" SG_ 514 VehVActlEng_D_Qf 1;
BA_ "U_CX727_MY2021_Rx" SG_ 514 VehVActlEng_D_Qf 1;
BA_ "U_P702_MY2021_Tx" SG_ 514 VehVActlEng_D_Qf 1;
BA_ "U_T6_MCA_MY2020_Tx" SG_ 514 VehVActlEng_D_Qf 1;
BA_ "CrossOver_InfoCAN" SG_ 514 Veh_V_ActlEng 1;
BA_ "U_P702_MY2021_Rx" SG_ 514 Veh_V_ActlEng 1;
BA_ "U_T6_MCA_MY2020_Rx" SG_ 514 Veh_V_ActlEng 1;
BA_ "U_CX727_MY2021_Rx" SG_ 514 Veh_V_ActlEng 1;
BA_ "U_P702_MY2021_Tx" SG_ 514 Veh_V_ActlEng 1;
BA_ "U_T6_MCA_MY2020_Tx" SG_ 514 Veh_V_ActlEng 1;
BA_ "ECGUsedRxSignal" SG_ 514 Veh_V_ActlEng 1;
BA_ "CrossOver_InfoCAN" SG_ 514 GearRvrse_D_Actl 1;
BA_ "GenSigStartValueInteger" SG_ 514 GearRvrse_D_Actl 7;
BA_ "GenSigStartValue" SG_ 514 GearRvrse_D_Actl 7;
BA_ "U_CX727_MY2021_Rx" SG_ 514 GearRvrse_D_Actl 1;
BA_ "U_P702_MY2021_Rx" SG_ 514 GearRvrse_D_Actl 1;
BA_ "U_P702_MY2021_Tx" SG_ 514 GearRvrse_D_Actl 1;
BA_ "U_T6_MCA_MY2020_Tx" SG_ 514 GearRvrse_D_Actl 1;
BA_ "ECGUsedRxSignal" SG_ 514 GearRvrse_D_Actl 1;
BA_ "U_P702_MY2021_Tx" SG_ 514 StrtrMtrCtlMsgTxt_D2_Rq 1;
BA_ "U_T6_MCA_MY2020_Tx" SG_ 514 StrtrMtrCtlMsgTxt_D2_Rq 1;
BA_ "ContentDependant" SG_ 512 PrplWhlTotTqRq_No_Cs 1;
BA_ "MetaData" SG_ 512 PrplWhlTotTqRq_No_Cs 1;
BA_ "U_P702_MY2021_Rx" SG_ 512 PrplWhlTotTqRq_No_Cs 1;
BA_ "U_P702_MY2021_Tx" SG_ 512 PrplWhlTotTqRq_No_Cs 1;
BA_ "ContentDependant" SG_ 512 PrplWhlTotTqRq_No_Cnt 1;
BA_ "MetaData" SG_ 512 PrplWhlTotTqRq_No_Cnt 1;
BA_ "U_P702_MY2021_Rx" SG_ 512 PrplWhlTotTqRq_No_Cnt 1;
BA_ "U_P702_MY2021_Tx" SG_ 512 PrplWhlTotTqRq_No_Cnt 1;
BA_ "U_CX727_MY2021_Rx" SG_ 512 PrplWhlTot_Tq_Rq 1;
BA_ "U_P702_MY2021_Rx" SG_ 512 PrplWhlTot_Tq_Rq 1;
BA_ "U_P702_MY2021_Tx" SG_ 512 PrplWhlTot_Tq_Rq 1;
BA_ "U_T6_MCA_MY2020_Tx" SG_ 512 PrplWhlTot_Tq_Rq 1;
BA_ "U_CX727_MY2021_Rx" SG_ 512 PrplWhlTot_Tq_LimMn 1;
BA_ "U_P702_MY2021_Rx" SG_ 512 PrplWhlTot_Tq_LimMn 1;
BA_ "U_P702_MY2021_Tx" SG_ 512 PrplWhlTot_Tq_LimMn 1;
BA_ "U_T6_MCA_MY2020_Tx" SG_ 512 PrplWhlTot_Tq_LimMn 1;
BA_ "U_T6_MCA_MY2020_Tx" SG_ 512 PtDrvMde_D_Stat 1;
BA_ "U_P702_MY2021_Tx" SG_ 512 PtDrvMde_D_Stat 1;
BA_ "WakeupSignal" SG_ 380 EngOilLvlWarn_D_Rq1 1;
BA_ "CrossOver_InfoCAN" SG_ 380 EngOilLvlWarn_D_Rq1 1;
BA_ "U_P702_MY2021_Tx" SG_ 380 EngOilLvlWarn_D_Rq1 1;
BA_ "U_T6_MCA_MY2020_Tx" SG_ 380 EngOilLvlWarn_D_Rq1 1;
BA_ "CrossOver_InfoCAN" SG_ 380 EngExhBrkOnLamp_B_Rq 1;
BA_ "U_P702_MY2021_Tx" SG_ 380 EngExhBrkOnLamp_B_Rq 1;
BA_ "U_T6_MCA_MY2020_Tx" SG_ 380 EngExhBrkOnLamp_B_Rq 1;
BA_ "CrossOver_InfoCAN" SG_ 380 EngExhBrkAutoLamp_B_Rq 1;
BA_ "U_P702_MY2021_Tx" SG_ 380 EngExhBrkAutoLamp_B_Rq 1;
BA_ "U_T6_MCA_MY2020_Tx" SG_ 380 EngExhBrkAutoLamp_B_Rq 1;
BA_ "CrossOver_InfoCAN" SG_ 380 EngAout_N_MxAllw 1;
BA_ "U_P702_MY2021_Tx" SG_ 380 EngAout_N_MxAllw 1;
BA_ "U_T6_MCA_MY2020_Tx" SG_ 380 EngAout_N_MxAllw 1;
BA_ "CrossOver_InfoCAN" SG_ 380 EngExhBrkMde_D_Actl 1;
BA_ "U_P702_MY2021_Rx" SG_ 380 EngExhBrkMde_D_Actl 1;
BA_ "U_T6_MCA_MY2020_Rx" SG_ 380 EngExhBrkMde_D_Actl 1;
BA_ "U_P702_MY2021_Tx" SG_ 380 EngExhBrkMde_D_Actl 1;
BA_ "U_T6_MCA_MY2020_Tx" SG_ 380 EngExhBrkMde_D_Actl 1;
BA_ "U_P702_MY2021_Tx" SG_ 377 HvacAirFullOut_B_Rq 1;
BA_ "CrossOver_InfoCAN" SG_ 377 FuelFlw_Vl_Dsply 1;
BA_ "ContentDependant" SG_ 377 FuelFlw_Vl_Dsply 1;
BA_ "U_P702_MY2021_Tx" SG_ 377 FuelFlw_Vl_Dsply 1;
BA_ "U_T6_MCA_MY2020_Tx" SG_ 377 FuelFlw_Vl_Dsply 1;
BA_ "ECGUsedRxSignal" SG_ 377 FuelFlw_Vl_Dsply 1;
BA_ "CrossOver_InfoCAN" SG_ 377 FuelFillInlet_B_Dsply 1;
BA_ "ContentDependant" SG_ 377 FuelFillInlet_B_Dsply 1;
BA_ "U_P702_MY2021_Tx" SG_ 377 FuelFillInlet_B_Dsply 1;
BA_ "U_T6_MCA_MY2020_Tx" SG_ 377 FuelFillInlet_B_Dsply 1;
BA_ "CrossOver_InfoCAN" SG_ 377 EngSrvcRqd_B_Rq 1;
BA_ "U_P702_MY2021_Tx" SG_ 377 EngSrvcRqd_B_Rq 1;
BA_ "U_T6_MCA_MY2020_Tx" SG_ 377 EngSrvcRqd_B_Rq 1;
BA_ "ECGUsedRxSignal" SG_ 377 EngSrvcRqd_B_Rq 1;
BA_ "CrossOver_InfoCAN" SG_ 377 OdoCount 1;
BA_ "ContentDependant" SG_ 377 OdoCount 1;
BA_ "U_P702_MY2021_Tx" SG_ 377 OdoCount 1;
BA_ "U_T6_MCA_MY2020_Tx" SG_ 377 OdoCount 1;
BA_ "CrossOver_InfoCAN" SG_ 377 EngOilLife_Pc_Actl 1;
BA_ "ContentDependant" SG_ 377 EngOilLife_Pc_Actl 1;
BA_ "U_P702_MY2021_Tx" SG_ 377 EngOilLife_Pc_Actl 1;
BA_ "U_T6_MCA_MY2020_Tx" SG_ 377 EngOilLife_Pc_Actl 1;
BA_ "ECGUsedRxSignal" SG_ 377 EngOilLife_Pc_Actl 1;
BA_ "CrossOver_InfoCAN" SG_ 377 FuelFilterLamp_B_Dsply 1;
BA_ "U_P702_MY2021_Tx" SG_ 377 FuelFilterLamp_B_Dsply 1;
BA_ "U_T6_MCA_MY2020_Tx" SG_ 377 FuelFilterLamp_B_Dsply 1;
BA_ "ECGUsedRxSignal" SG_ 377 FuelFilterLamp_B_Dsply 1;
BA_ "CrossOver_InfoCAN" SG_ 377 AirCondRec_B_Rq 1;
BA_ "ContentDependant" SG_ 377 AirCondRec_B_Rq 1;
BA_ "U_P702_MY2021_Tx" SG_ 377 AirCondRec_B_Rq 1;
BA_ "U_T6_MCA_MY2020_Tx" SG_ 377 AirCondRec_B_Rq 1;
BA_ "CrossOver_InfoCAN" SG_ 377 AirCondClutch_B_Stats 1;
BA_ "ContentDependant" SG_ 377 AirCondClutch_B_Stats 1;
BA_ "U_P702_MY2021_Tx" SG_ 377 AirCondClutch_B_Stats 1;
BA_ "U_T6_MCA_MY2020_Tx" SG_ 377 AirCondClutch_B_Stats 1;
BA_ "U_P702_MY2021_Tx" SG_ 376 GasPrtc_D_RqDsply 1;
BA_ "U_T6_MCA_MY2020_Tx" SG_ 376 GasPrtc_D_RqDsply 1;
BA_ "CrossOver_InfoCAN" SG_ 376 EngAout_Aa_Actl 1;
BA_ "ContentDependant" SG_ 376 EngAout_Aa_Actl 1;
BA_ "U_CX727_MY2021_Rx" SG_ 376 EngAout_Aa_Actl 1;
BA_ "U_P702_MY2021_Rx" SG_ 376 EngAout_Aa_Actl 1;
BA_ "U_P702_MY2021_Tx" SG_ 376 EngAout_Aa_Actl 1;
BA_ "U_T6_MCA_MY2020_Tx" SG_ 376 EngAout_Aa_Actl 1;
BA_ "U_CX727_MY2021_Rx" SG_ 376 DynoMde_B_Cmd 1;
BA_ "U_P702_MY2021_Rx" SG_ 376 DynoMde_B_Cmd 1;
BA_ "U_T6_MCA_MY2020_Rx" SG_ 376 DynoMde_B_Cmd 1;
BA_ "U_P702_MY2021_Tx" SG_ 376 DynoMde_B_Cmd 1;
BA_ "U_T6_MCA_MY2020_Tx" SG_ 376 DynoMde_B_Cmd 1;
BA_ "U_P702_MY2021_Tx" SG_ 376 AslIconDsply_D_Rq 1;
BA_ "U_T6_MCA_MY2020_Tx" SG_ 376 AslIconDsply_D_Rq 1;
BA_ "U_P702_MY2021_Tx" SG_ 376 AslChime_B_Rq 1;
BA_ "U_T6_MCA_MY2020_Tx" SG_ 376 AslChime_B_Rq 1;
BA_ "GenSigStartValueInteger" SG_ 376 HvacHtrCore2_Te_Actl 200;
BA_ "U_P702_MY2021_Tx" SG_ 376 HvacHtrCore2_Te_Actl 1;
BA_ "U_P702_MY2021_Tx" SG_ 376 EcssLamp_D_RqDsply 1;
BA_ "U_T6_MCA_MY2020_Tx" SG_ 376 EcssLamp_D_RqDsply 1;
BA_ "CrossOver_InfoCAN" SG_ 376 AirAmbTe_D_Qf 1;
BA_ "GenSigStartValueInteger" SG_ 376 AirAmbTe_D_Qf 1;
BA_ "MetaData" SG_ 376 AirAmbTe_D_Qf 1;
BA_ "GenSigStartValue" SG_ 376 AirAmbTe_D_Qf 1;
BA_ "U_P702_MY2021_Rx" SG_ 376 AirAmbTe_D_Qf 1;
BA_ "U_CX727_MY2021_Rx" SG_ 376 AirAmbTe_D_Qf 1;
BA_ "U_P702_MY2021_Tx" SG_ 376 AirAmbTe_D_Qf 1;
BA_ "U_T6_MCA_MY2020_Tx" SG_ 376 AirAmbTe_D_Qf 1;
BA_ "CrossOver_InfoCAN" SG_ 376 AirAmb_Te_ActlFilt 1;
BA_ "GenSigStartValueInteger" SG_ 376 AirAmb_Te_ActlFilt 512;
BA_ "U_P702_MY2021_Tx" SG_ 376 AirAmb_Te_ActlFilt 1;
BA_ "U_T6_MCA_MY2020_Tx" SG_ 376 AirAmb_Te_ActlFilt 1;
BA_ "ECGUsedRxSignal" SG_ 376 AirAmb_Te_ActlFilt 1;
BA_ "CrossOver_InfoCAN" SG_ 376 AirAmb_Te_Actl 1;
BA_ "GenSigStartValueInteger" SG_ 376 AirAmb_Te_Actl 512;
BA_ "U_P702_MY2021_Rx" SG_ 376 AirAmb_Te_Actl 1;
BA_ "U_CX727_MY2021_Rx" SG_ 376 AirAmb_Te_Actl 1;
BA_ "U_P702_MY2021_Tx" SG_ 376 AirAmb_Te_Actl 1;
BA_ "U_T6_MCA_MY2020_Tx" SG_ 376 AirAmb_Te_Actl 1;
BA_ "CrossOver_InfoCAN" SG_ 376 AirAmb_P_Actl 1;
BA_ "U_P702_MY2021_Rx" SG_ 376 AirAmb_P_Actl 1;
BA_ "U_T6_MCA_MY2020_Rx" SG_ 376 AirAmb_P_Actl 1;
BA_ "U_P702_MY2021_Tx" SG_ 376 AirAmb_P_Actl 1;
BA_ "U_T6_MCA_MY2020_Tx" SG_ 376 AirAmb_P_Actl 1;
BA_ "GenSigStartValueInteger" SG_ 359 PrplWhlRgenMn_Tq_Actl 4095;
BA_ "U_CX727_MY2021_Rx" SG_ 359 PrplWhlRgenMn_Tq_Actl 1;
BA_ "U_P702_MY2021_Rx" SG_ 359 PrplWhlRgenMn_Tq_Actl 1;
BA_ "U_P702_MY2021_Tx" SG_ 359 PrplWhlRgenMn_Tq_Actl 1;
BA_ "CrossOver_InfoCAN" SG_ 359 ElPw_D_StatStrtStop 1;
BA_ "U_P702_MY2021_Rx" SG_ 359 ElPw_D_StatStrtStop 1;
BA_ "U_P702_MY2021_Tx" SG_ 359 ElPw_D_StatStrtStop 1;
BA_ "U_T6_MCA_MY2020_Tx" SG_ 359 ElPw_D_StatStrtStop 1;
BA_ "CrossOver_InfoCAN" SG_ 359 TrnAin_Tq_Actl 1;
BA_ "ContentDependant" SG_ 359 TrnAin_Tq_Actl 1;
BA_ "U_CX727_MY2021_Rx" SG_ 359 TrnAin_Tq_Actl 1;
BA_ "U_P702_MY2021_Rx" SG_ 359 TrnAin_Tq_Actl 1;
BA_ "U_P702_MY2021_Tx" SG_ 359 TrnAin_Tq_Actl 1;
BA_ "U_T6_MCA_MY2020_Tx" SG_ 359 TrnAin_Tq_Actl 1;
BA_ "CrossOver_InfoCAN" SG_ 359 PrplWhlTot2_Tq_Actl 1;
BA_ "U_P702_MY2021_Rx" SG_ 359 PrplWhlTot2_Tq_Actl 1;
BA_ "U_CX727_MY2021_Rx" SG_ 359 PrplWhlTot2_Tq_Actl 1;
BA_ "U_P702_MY2021_Tx" SG_ 359 PrplWhlTot2_Tq_Actl 1;
BA_ "U_T6_MCA_MY2020_Tx" SG_ 359 PrplWhlTot2_Tq_Actl 1;
BA_ "ECGUsedRxSignal" SG_ 359 PrplWhlTot2_Tq_Actl 1;
BA_ "CrossOver_InfoCAN" SG_ 359 PwPckTq_D_Stat 1;
BA_ "U_P702_MY2021_Rx" SG_ 359 PwPckTq_D_Stat 1;
BA_ "U_T6_MCA_MY2020_Rx" SG_ 359 PwPckTq_D_Stat 1;
BA_ "U_CX727_MY2021_Rx" SG_ 359 PwPckTq_D_Stat 1;
BA_ "U_P702_MY2021_Tx" SG_ 359 PwPckTq_D_Stat 1;
BA_ "U_T6_MCA_MY2020_Tx" SG_ 359 PwPckTq_D_Stat 1;
BA_ "ECGUsedRxSignal" SG_ 359 PwPckTq_D_Stat 1;
BA_ "CrossOver_InfoCAN" SG_ 359 Eng_D_Stat 1;
BA_ "U_CX727_MY2021_Rx" SG_ 359 Eng_D_Stat 1;
BA_ "U_P702_MY2021_Rx" SG_ 359 Eng_D_Stat 1;
BA_ "U_P702_MY2021_Tx" SG_ 359 Eng_D_Stat 1;
BA_ "U_T6_MCA_MY2020_Tx" SG_ 359 Eng_D_Stat 1;
BA_ "ECGUsedRxSignal" SG_ 359 Eng_D_Stat 1;
BA_ "CrossOver_InfoCAN" SG_ 359 PlgActvArb_B_Actl 1;
BA_ "GenSigStartValueInteger" SG_ 359 PlgActvArb_B_Actl 1;
BA_ "ContentDependant" SG_ 359 PlgActvArb_B_Actl 1;
BA_ "GenSigStartValue" SG_ 359 PlgActvArb_B_Actl 1;
BA_ "ECGUsedRxSignal" SG_ 359 PlgActvArb_B_Actl 1;
BA_ "CrossOver_InfoCAN" SG_ 359 ElPw_D_Stat 1;
BA_ "U_P702_MY2021_Rx" SG_ 359 ElPw_D_Stat 1;
BA_ "U_T6_MCA_MY2020_Rx" SG_ 359 ElPw_D_Stat 1;
BA_ "U_CX727_MY2021_Rx" SG_ 359 ElPw_D_Stat 1;
BA_ "U_P702_MY2021_Tx" SG_ 359 ElPw_D_Stat 1;
BA_ "U_T6_MCA_MY2020_Tx" SG_ 359 ElPw_D_Stat 1;
BA_ "CrossOver_InfoCAN" SG_ 359 TrnAinTq_D_Qf 1;
BA_ "ContentDependant" SG_ 359 TrnAinTq_D_Qf 1;
BA_ "MetaData" SG_ 359 TrnAinTq_D_Qf 1;
BA_ "U_CX727_MY2021_Rx" SG_ 359 TrnAinTq_D_Qf 1;
BA_ "U_P702_MY2021_Rx" SG_ 359 TrnAinTq_D_Qf 1;
BA_ "U_P702_MY2021_Tx" SG_ 359 TrnAinTq_D_Qf 1;
BA_ "U_T6_MCA_MY2020_Tx" SG_ 359 TrnAinTq_D_Qf 1;
BA_ "CrossOver_InfoCAN" SG_ 358 StopStrtStdby_D_Indic 1;
BA_ "U_P702_MY2021_Tx" SG_ 358 StopStrtStdby_D_Indic 1;
BA_ "U_T6_MCA_MY2020_Tx" SG_ 358 StopStrtStdby_D_Indic 1;
BA_ "CrossOver_InfoCAN" SG_ 358 StopStrtIODTxt_D_Rq 1;
BA_ "U_P702_MY2021_Tx" SG_ 358 StopStrtIODTxt_D_Rq 1;
BA_ "U_T6_MCA_MY2020_Tx" SG_ 358 StopStrtIODTxt_D_Rq 1;
BA_ "CrossOver_InfoCAN" SG_ 358 StopStrtDrvMde_D_Indic 1;
BA_ "U_P702_MY2021_Tx" SG_ 358 StopStrtDrvMde_D_Indic 1;
BA_ "U_T6_MCA_MY2020_Tx" SG_ 358 StopStrtDrvMde_D_Indic 1;
BA_ "CrossOver_InfoCAN" SG_ 358 StopStrtMsgTxt_D_Rq 1;
BA_ "U_P702_MY2021_Tx" SG_ 358 StopStrtMsgTxt_D_Rq 1;
BA_ "U_T6_MCA_MY2020_Tx" SG_ 358 StopStrtMsgTxt_D_Rq 1;
BA_ "CrossOver_InfoCAN" SG_ 358 OdoTripVerify_L_Actl 1;
BA_ "U_P702_MY2021_Tx" SG_ 358 OdoTripVerify_L_Actl 1;
BA_ "U_T6_MCA_MY2020_Tx" SG_ 358 OdoTripVerify_L_Actl 1;
BA_ "CrossOver_InfoCAN" SG_ 358 HiElPwInhbt_B_Stat 1;
BA_ "ContentDependant" SG_ 358 HiElPwInhbt_B_Stat 1;
BA_ "U_P702_MY2021_Tx" SG_ 358 HiElPwInhbt_B_Stat 1;
BA_ "U_T6_MCA_MY2020_Tx" SG_ 358 HiElPwInhbt_B_Stat 1;
BA_ "CrossOver_InfoCAN" SG_ 358 AutoStopPtDelta_I_Est 1;
BA_ "GenSigStartValueInteger" SG_ 358 AutoStopPtDelta_I_Est 127;
BA_ "ContentDependant" SG_ 358 AutoStopPtDelta_I_Est 1;
BA_ "U_P702_MY2021_Tx" SG_ 358 AutoStopPtDelta_I_Est 1;
BA_ "U_T6_MCA_MY2020_Tx" SG_ 358 AutoStopPtDelta_I_Est 1;
BA_ "GenSigStartValueInteger" SG_ 357 BPedDrvAppl_D_QF 1;
BA_ "MetaData" SG_ 357 BPedDrvAppl_D_QF 1;
BA_ "GenSigStartValue" SG_ 357 BPedDrvAppl_D_QF 1;
BA_ "U_P702_MY2021_Rx" SG_ 357 BPedDrvAppl_D_QF 1;
BA_ "U_T6_MCA_MY2020_Rx" SG_ 357 BPedDrvAppl_D_QF 1;
BA_ "U_CX727_MY2021_Rx" SG_ 357 BPedDrvAppl_D_QF 1;
BA_ "U_P702_MY2021_Tx" SG_ 357 BPedDrvAppl_D_QF 1;
BA_ "U_T6_MCA_MY2020_Tx" SG_ 357 BPedDrvAppl_D_QF 1;
BA_ "U_P702_MY2021_Tx" SG_ 357 CmbbDeny_B_ActlPrpl 1;
BA_ "U_T6_MCA_MY2020_Tx" SG_ 357 CmbbDeny_B_ActlPrpl 1;
BA_ "U_P702_MY2021_Tx" SG_ 357 PrplTqMnSat_B_Actl 1;
BA_ "U_T6_MCA_MY2020_Tx" SG_ 357 PrplTqMnSat_B_Actl 1;
BA_ "CrossOver_InfoCAN" SG_ 357 BpedDrvAppl_D_Actl 1;
BA_ "GenSigStartValueInteger" SG_ 357 BpedDrvAppl_D_Actl 1;
BA_ "GenSigStartValue" SG_ 357 BpedDrvAppl_D_Actl 1;
BA_ "U_P702_MY2021_Rx" SG_ 357 BpedDrvAppl_D_Actl 1;
BA_ "U_T6_MCA_MY2020_Rx" SG_ 357 BpedDrvAppl_D_Actl 1;
BA_ "U_CX727_MY2021_Rx" SG_ 357 BpedDrvAppl_D_Actl 1;
BA_ "U_P702_MY2021_Tx" SG_ 357 BpedDrvAppl_D_Actl 1;
BA_ "U_T6_MCA_MY2020_Tx" SG_ 357 BpedDrvAppl_D_Actl 1;
BA_ "ECGUsedRxSignal" SG_ 357 BpedDrvAppl_D_Actl 1;
BA_ "U_P702_MY2021_Tx" SG_ 357 CmbbEngTqMn_B_Actl 1;
BA_ "U_T6_MCA_MY2020_Tx" SG_ 357 CmbbEngTqMn_B_Actl 1;
BA_ "CrossOver_InfoCAN" SG_ 357 Veh_V_DsplyCcSet 1;
BA_ "U_P702_MY2021_Tx" SG_ 357 Veh_V_DsplyCcSet 1;
BA_ "U_T6_MCA_MY2020_Tx" SG_ 357 Veh_V_DsplyCcSet 1;
BA_ "U_P702_MY2021_Tx" SG_ 357 AccEngStat_D_Actl 1;
BA_ "U_T6_MCA_MY2020_Tx" SG_ 357 AccEngStat_D_Actl 1;
BA_ "U_CX727_MY2021_Rx" SG_ 357 CcMde_D_Actl 1;
BA_ "U_P702_MY2021_Rx" SG_ 357 CcMde_D_Actl 1;
BA_ "U_T6_MCA_MY2020_Rx" SG_ 357 CcMde_D_Actl 1;
BA_ "U_P702_MY2021_Tx" SG_ 357 CcMde_D_Actl 1;
BA_ "U_T6_MCA_MY2020_Tx" SG_ 357 CcMde_D_Actl 1;
BA_ "CrossOver_InfoCAN" SG_ 357 CcStat_D_Actl 1;
BA_ "U_P702_MY2021_Rx" SG_ 357 CcStat_D_Actl 1;
BA_ "U_T6_MCA_MY2020_Rx" SG_ 357 CcStat_D_Actl 1;
BA_ "U_CX727_MY2021_Rx" SG_ 357 CcStat_D_Actl 1;
BA_ "U_P702_MY2021_Tx" SG_ 357 CcStat_D_Actl 1;
BA_ "U_T6_MCA_MY2020_Tx" SG_ 357 CcStat_D_Actl 1;
BA_ "U_P702_MY2021_Tx" SG_ 357 EngAout_N_MnAllw 1;
BA_ "CrossOver_InfoCAN" SG_ 357 CcOvrrdActv_B_Actl 1;
BA_ "U_P702_MY2021_Rx" SG_ 357 CcOvrrdActv_B_Actl 1;
BA_ "U_T6_MCA_MY2020_Rx" SG_ 357 CcOvrrdActv_B_Actl 1;
BA_ "U_CX727_MY2021_Rx" SG_ 357 CcOvrrdActv_B_Actl 1;
BA_ "U_P702_MY2021_Tx" SG_ 357 CcOvrrdActv_B_Actl 1;
BA_ "U_T6_MCA_MY2020_Tx" SG_ 357 CcOvrrdActv_B_Actl 1;
BA_ "U_CX727_MY2021_Rx" SG_ 357 AccStopMde_D_Rq 1;
BA_ "U_P702_MY2021_Rx" SG_ 357 AccStopMde_D_Rq 1;
BA_ "U_P702_MY2021_Tx" SG_ 357 AccStopMde_D_Rq 1;
BA_ "U_T6_MCA_MY2020_Tx" SG_ 357 AccStopMde_D_Rq 1;
BA_ "CrossOver_InfoCAN" SG_ 342 EngOvrhtMitgActv_D_Ind 1;
BA_ "ContentDependant" SG_ 342 EngOvrhtMitgActv_D_Ind 1;
BA_ "U_P702_MY2021_Tx" SG_ 342 EngOvrhtMitgActv_D_Ind 1;
BA_ "U_T6_MCA_MY2020_Tx" SG_ 342 EngOvrhtMitgActv_D_Ind 1;
BA_ "CrossOver_InfoCAN" SG_ 342 EngClntTe_D_Qf 1;
BA_ "MetaData" SG_ 342 EngClntTe_D_Qf 1;
BA_ "U_P702_MY2021_Rx" SG_ 342 EngClntTe_D_Qf 1;
BA_ "U_T6_MCA_MY2020_Rx" SG_ 342 EngClntTe_D_Qf 1;
BA_ "U_P702_MY2021_Tx" SG_ 342 EngClntTe_D_Qf 1;
BA_ "U_T6_MCA_MY2020_Tx" SG_ 342 EngClntTe_D_Qf 1;
BA_ "CrossOver_InfoCAN" SG_ 342 EngGoutLss_Tq_Est 1;
BA_ "ContentDependant" SG_ 342 EngGoutLss_Tq_Est 1;
BA_ "U_P702_MY2021_Tx" SG_ 342 EngGoutLss_Tq_Est 1;
BA_ "CrossOver_InfoCAN" SG_ 342 EngOil_Te_Actl 1;
BA_ "U_P702_MY2021_Tx" SG_ 342 EngOil_Te_Actl 1;
BA_ "U_T6_MCA_MY2020_Tx" SG_ 342 EngOil_Te_Actl 1;
BA_ "CrossOver_InfoCAN" SG_ 342 EngClnt_Te_Actl 1;
BA_ "U_P702_MY2021_Rx" SG_ 342 EngClnt_Te_Actl 1;
BA_ "U_T6_MCA_MY2020_Rx" SG_ 342 EngClnt_Te_Actl 1;
BA_ "U_P702_MY2021_Tx" SG_ 342 EngClnt_Te_Actl 1;
BA_ "U_T6_MCA_MY2020_Tx" SG_ 342 EngClnt_Te_Actl 1;
BA_ "ECGUsedRxSignal" SG_ 342 EngClnt_Te_Actl 1;
BA_ "U_P702_MY2021_Rx" SG_ 954 GenericSwtch3_No_Actl 1;
BA_ "ContentDependant" SG_ 954 GenericSwtch2_No_Actl 1;
BA_ "U_P702_MY2021_Rx" SG_ 954 GenericSwtch2_No_Actl 1;
BA_ "U_P702_MY2021_Rx" SG_ 954 GenericSwtch1_No_Actl 1;
BA_ "CrossOver_InfoCAN" SG_ 935 SodRight_D_Stat 1;
BA_ "GenSigStartValueInteger" SG_ 935 SodRight_D_Stat 2;
BA_ "GenSigStartValue" SG_ 935 SodRight_D_Stat 2;
BA_ "GenSigSendType" SG_ 935 SodRight_D_Stat 3;
BA_ "GenSigSendType" SG_ 935 CtaAlrtRight2_D_Stat 3;
BA_ "GenSigSendType" SG_ 935 BttRight_D_Stat 3;
BA_ "GenSigSendType" SG_ 935 BttRight_D_RqDrv 3;
BA_ "GenSigSendType" SG_ 935 CtaBrkRightMsgTxt_B_Rq 3;
BA_ "GenSigSendType" SG_ 935 CtaRightBrkEnbl_B_Rq 3;
BA_ "U_CX727_MY2021_Rx" SG_ 935 CtaRightBrkEnbl_B_Rq 1;
BA_ "U_P702_MY2021_Rx" SG_ 935 CtaRightBrkEnbl_B_Rq 1;
BA_ "GenSigSendType" SG_ 935 CtaRightBrkDecel_B_Rq 3;
BA_ "U_CX727_MY2021_Rx" SG_ 935 CtaRightBrkDecel_B_Rq 1;
BA_ "U_P702_MY2021_Rx" SG_ 935 CtaRightBrkDecel_B_Rq 1;
BA_ "CrossOver_InfoCAN" SG_ 935 Side_Detect_R_Illum 1;
BA_ "GenSigStartValueInteger" SG_ 935 Side_Detect_R_Illum 100;
BA_ "GenSigStartValue" SG_ 935 Side_Detect_R_Illum 100;
BA_ "CrossOver_InfoCAN" SG_ 935 CtaSnsRight_D_Stat 1;
BA_ "GenSigSendType" SG_ 935 CtaSnsRight_D_Stat 3;
BA_ "CrossOver_InfoCAN" SG_ 935 CtaAlrtRight_D_Stat 1;
BA_ "GenSigSendType" SG_ 935 CtaAlrtRight_D_Stat 3;
BA_ "CrossOver_InfoCAN" SG_ 935 CtaRight_D_Stat 1;
BA_ "GenSigSendType" SG_ 935 CtaRight_D_Stat 3;
BA_ "CrossOver_InfoCAN" SG_ 935 SodSnsRight_D_Stat 1;
BA_ "GenSigSendType" SG_ 935 SodSnsRight_D_Stat 3;
BA_ "CrossOver_InfoCAN" SG_ 935 SodAlrtRight_D_Stat 1;
BA_ "GenSigSendType" SG_ 935 SodAlrtRight_D_Stat 3;
BA_ "CrossOver_InfoCAN" SG_ 935 SodDetctRight_D_Stat 1;
BA_ "GenSigSendType" SG_ 935 SodDetctRight_D_Stat 3;
BA_ "CrossOver_InfoCAN" SG_ 935 SodWarnRight_Prd_Rq 1;
BA_ "GenSigStartValueInteger" SG_ 935 SodWarnRight_Prd_Rq 14;
BA_ "GenSigStartValue" SG_ 935 SodWarnRight_Prd_Rq 14;
BA_ "U_P702_MY2021_Rx" SG_ 1041 ElCmpr_Pw_Actl 1;
BA_ "U_CX727_MY2021_Rx" SG_ 1112 BattTracChrgSustn_B_Rq 1;
BA_ "U_P702_MY2021_Rx" SG_ 1112 BattTracCnnct_D_Cmd 1;
BA_ "U_P702_MY2021_Rx" SG_ 1112 BattTracHvilOpen_B_Stat 1;
BA_ "U_P702_MY2021_Rx" SG_ 1112 BattTracDcdcDis_B_Rq 1;
BA_ "GenSigStartValueInteger" SG_ 1112 BattTracDelta_Te_Actl 164;
BA_ "GenSigStartValue" SG_ 1112 BattTracDelta_Te_Actl 120;
BA_ "ContentDependant" SG_ 1112 BattTracClntPmp_D_Stat 1;
BA_ "CrossOver_InfoCAN" SG_ 1050 Outside_Air_Temp_Stat 1;
BA_ "GenSigStartValueInteger" SG_ 1050 Outside_Air_Temp_Stat 254;
BA_ "GenSigStartValue" SG_ 1050 Outside_Air_Temp_Stat 254;
BA_ "U_P702_MY2021_Rx" SG_ 1050 Outside_Air_Temp_Stat 1;
BA_ "U_T6_MCA_MY2020_Rx" SG_ 1050 Outside_Air_Temp_Stat 1;
BA_ "U_P702_MY2021_Rx" SG_ 1009 TrlrAidCancl_B_Rq 1;
BA_ "GenSigStartValueInteger" SG_ 1009 CenterStackRing_D_Actl 2;
BA_ "GenSigStartValue" SG_ 1009 CenterStackRing_D_Actl 2;
BA_ "CrossOver_InfoCAN" SG_ 1009 ValetMode_D_Stat 1;
BA_ "CrossOver_InfoCAN" SG_ 360 GsmSrvcRqd_B_Rq 1;
BA_ "ContentDependant" SG_ 360 GsmSrvcRqd_B_Rq 1;
BA_ "CrossOver_InfoCAN" SG_ 360 TrnGearPwmFalt_B_Actl 1;
BA_ "ContentDependant" SG_ 360 TrnGearPwmFalt_B_Actl 1;
BA_ "U_P702_MY2021_Rx" SG_ 360 TrnGearPwmFalt_B_Actl 1;
BA_ "U_T6_MCA_MY2020_Rx" SG_ 360 TrnGearPwmFalt_B_Actl 1;
BA_ "CrossOver_InfoCAN" SG_ 360 GearButtnStuck_B_Actl 1;
BA_ "ContentDependant" SG_ 360 GearButtnStuck_B_Actl 1;
BA_ "U_P702_MY2021_Rx" SG_ 360 GearButtnStuck_B_Actl 1;
BA_ "U_T6_MCA_MY2020_Rx" SG_ 360 GearButtnStuck_B_Actl 1;
BA_ "CrossOver_InfoCAN" SG_ 90 TrnGsmNtmState_D_Actl 1;
BA_ "ContentDependant" SG_ 90 TrnGsmNtmState_D_Actl 1;
BA_ "U_P702_MY2021_Rx" SG_ 90 TrnGsmNtmState_D_Actl 1;
BA_ "U_T6_MCA_MY2020_Rx" SG_ 90 TrnGsmNtmState_D_Actl 1;
BA_ "U_CX727_MY2021_Rx" SG_ 90 TrnGsmNtmState_D_Actl 1;
BA_ "ContentDependant" SG_ 90 DrQltyDrv_D_StatGsm 1;
BA_ "GenSigStartValue" SG_ 90 DrQltyDrv_D_StatGsm 6;
BA_ "U_P702_MY2021_Rx" SG_ 90 DrQltyDrv_D_StatGsm 1;
BA_ "U_T6_MCA_MY2020_Rx" SG_ 90 DrQltyDrv_D_StatGsm 1;
BA_ "U_CX727_MY2021_Rx" SG_ 90 DrQltyDrv_D_StatGsm 1;
BA_ "ContentDependant" SG_ 90 TrnBtsiOvrrd_B_Stat 1;
BA_ "U_P702_MY2021_Rx" SG_ 90 TrnBtsiOvrrd_B_Stat 1;
BA_ "U_T6_MCA_MY2020_Rx" SG_ 90 TrnBtsiOvrrd_B_Stat 1;
BA_ "GenSigStartValueInteger" SG_ 90 TrnRng_D_RqGsm 14;
BA_ "GenSigStartValue" SG_ 90 TrnRng_D_RqGsm 14;
BA_ "U_P702_MY2021_Rx" SG_ 90 TrnRng_D_RqGsm 1;
BA_ "U_T6_MCA_MY2020_Rx" SG_ 90 TrnRng_D_RqGsm 1;
BA_ "U_CX727_MY2021_Rx" SG_ 90 PrkBrkActv_D_RqGsmGear 1;
BA_ "U_P702_MY2021_Rx" SG_ 90 PrkBrkActv_D_RqGsmGear 1;
BA_ "ContentDependant" SG_ 90 TrnValidGearRq_D_Stat 1;
BA_ "U_P702_MY2021_Rx" SG_ 90 TrnValidGearRq_D_Stat 1;
BA_ "U_T6_MCA_MY2020_Rx" SG_ 90 TrnValidGearRq_D_Stat 1;
BA_ "ContentDependant" SG_ 90 TrnGearRqCnt_B_Actl 1;
BA_ "U_P702_MY2021_Rx" SG_ 90 TrnGearRqCnt_B_Actl 1;
BA_ "U_T6_MCA_MY2020_Rx" SG_ 90 TrnGearRqCnt_B_Actl 1;
BA_ "WakeupSignal" SG_ 90 TrnGearButtn_U_Actl 1;
BA_ "ContentDependant" SG_ 90 TrnGearButtn_U_Actl 1;
BA_ "U_P702_MY2021_Rx" SG_ 90 TrnGearButtn_U_Actl 1;
BA_ "U_T6_MCA_MY2020_Rx" SG_ 90 TrnGearButtn_U_Actl 1;
BA_ "WakeupSignal" SG_ 90 TrnGearButtn_B_ActlR2 1;
BA_ "ContentDependant" SG_ 90 TrnGearButtn_B_ActlR2 1;
BA_ "U_P702_MY2021_Rx" SG_ 90 TrnGearButtn_B_ActlR2 1;
BA_ "U_T6_MCA_MY2020_Rx" SG_ 90 TrnGearButtn_B_ActlR2 1;
BA_ "WakeupSignal" SG_ 90 TrnGearButtn_B_ActlR1 1;
BA_ "ContentDependant" SG_ 90 TrnGearButtn_B_ActlR1 1;
BA_ "U_P702_MY2021_Rx" SG_ 90 TrnGearButtn_B_ActlR1 1;
BA_ "U_T6_MCA_MY2020_Rx" SG_ 90 TrnGearButtn_B_ActlR1 1;
BA_ "WakeupSignal" SG_ 90 TrnGearButtn_B_ActlR0 1;
BA_ "ContentDependant" SG_ 90 TrnGearButtn_B_ActlR0 1;
BA_ "U_P702_MY2021_Rx" SG_ 90 TrnGearButtn_B_ActlR0 1;
BA_ "U_T6_MCA_MY2020_Rx" SG_ 90 TrnGearButtn_B_ActlR0 1;
BA_ "WakeupSignal" SG_ 90 TrnGearButtn_B_ActlP2 1;
BA_ "ContentDependant" SG_ 90 TrnGearButtn_B_ActlP2 1;
BA_ "U_P702_MY2021_Rx" SG_ 90 TrnGearButtn_B_ActlP2 1;
BA_ "U_T6_MCA_MY2020_Rx" SG_ 90 TrnGearButtn_B_ActlP2 1;
BA_ "WakeupSignal" SG_ 90 TrnGearButtn_B_ActlP1 1;
BA_ "ContentDependant" SG_ 90 TrnGearButtn_B_ActlP1 1;
BA_ "U_P702_MY2021_Rx" SG_ 90 TrnGearButtn_B_ActlP1 1;
BA_ "U_T6_MCA_MY2020_Rx" SG_ 90 TrnGearButtn_B_ActlP1 1;
BA_ "WakeupSignal" SG_ 90 TrnGearButtn_B_ActlP0 1;
BA_ "ContentDependant" SG_ 90 TrnGearButtn_B_ActlP0 1;
BA_ "U_P702_MY2021_Rx" SG_ 90 TrnGearButtn_B_ActlP0 1;
BA_ "U_T6_MCA_MY2020_Rx" SG_ 90 TrnGearButtn_B_ActlP0 1;
BA_ "WakeupSignal" SG_ 90 TrnGearButtn_B_ActlN2 1;
BA_ "ContentDependant" SG_ 90 TrnGearButtn_B_ActlN2 1;
BA_ "U_P702_MY2021_Rx" SG_ 90 TrnGearButtn_B_ActlN2 1;
BA_ "U_T6_MCA_MY2020_Rx" SG_ 90 TrnGearButtn_B_ActlN2 1;
BA_ "WakeupSignal" SG_ 90 TrnGearButtn_B_ActlN1 1;
BA_ "ContentDependant" SG_ 90 TrnGearButtn_B_ActlN1 1;
BA_ "U_P702_MY2021_Rx" SG_ 90 TrnGearButtn_B_ActlN1 1;
BA_ "U_T6_MCA_MY2020_Rx" SG_ 90 TrnGearButtn_B_ActlN1 1;
BA_ "WakeupSignal" SG_ 90 TrnGearButtn_B_ActlN0 1;
BA_ "ContentDependant" SG_ 90 TrnGearButtn_B_ActlN0 1;
BA_ "U_P702_MY2021_Rx" SG_ 90 TrnGearButtn_B_ActlN0 1;
BA_ "U_T6_MCA_MY2020_Rx" SG_ 90 TrnGearButtn_B_ActlN0 1;
BA_ "WakeupSignal" SG_ 90 TrnGearButtn_B_ActlM2 1;
BA_ "ContentDependant" SG_ 90 TrnGearButtn_B_ActlM2 1;
BA_ "U_P702_MY2021_Rx" SG_ 90 TrnGearButtn_B_ActlM2 1;
BA_ "U_T6_MCA_MY2020_Rx" SG_ 90 TrnGearButtn_B_ActlM2 1;
BA_ "WakeupSignal" SG_ 90 TrnGearButtn_B_ActlM1 1;
BA_ "ContentDependant" SG_ 90 TrnGearButtn_B_ActlM1 1;
BA_ "U_P702_MY2021_Rx" SG_ 90 TrnGearButtn_B_ActlM1 1;
BA_ "U_T6_MCA_MY2020_Rx" SG_ 90 TrnGearButtn_B_ActlM1 1;
BA_ "WakeupSignal" SG_ 90 TrnGearButtn_B_ActlM0 1;
BA_ "ContentDependant" SG_ 90 TrnGearButtn_B_ActlM0 1;
BA_ "U_P702_MY2021_Rx" SG_ 90 TrnGearButtn_B_ActlM0 1;
BA_ "U_T6_MCA_MY2020_Rx" SG_ 90 TrnGearButtn_B_ActlM0 1;
BA_ "WakeupSignal" SG_ 90 TrnGearButtn_B_ActlD2 1;
BA_ "ContentDependant" SG_ 90 TrnGearButtn_B_ActlD2 1;
BA_ "U_P702_MY2021_Rx" SG_ 90 TrnGearButtn_B_ActlD2 1;
BA_ "U_T6_MCA_MY2020_Rx" SG_ 90 TrnGearButtn_B_ActlD2 1;
BA_ "WakeupSignal" SG_ 90 TrnGearButtn_B_ActlD1 1;
BA_ "ContentDependant" SG_ 90 TrnGearButtn_B_ActlD1 1;
BA_ "U_P702_MY2021_Rx" SG_ 90 TrnGearButtn_B_ActlD1 1;
BA_ "U_T6_MCA_MY2020_Rx" SG_ 90 TrnGearButtn_B_ActlD1 1;
BA_ "WakeupSignal" SG_ 90 TrnGearButtn_B_ActlD0 1;
BA_ "ContentDependant" SG_ 90 TrnGearButtn_B_ActlD0 1;
BA_ "U_P702_MY2021_Rx" SG_ 90 TrnGearButtn_B_ActlD0 1;
BA_ "U_T6_MCA_MY2020_Rx" SG_ 90 TrnGearButtn_B_ActlD0 1;
BA_ "ContentDependant" SG_ 90 TrnGear_No_Cs 1;
BA_ "MetaData" SG_ 90 TrnGear_No_Cs 1;
BA_ "U_P702_MY2021_Rx" SG_ 90 TrnGear_No_Cs 1;
BA_ "U_T6_MCA_MY2020_Rx" SG_ 90 TrnGear_No_Cs 1;
BA_ "ContentDependant" SG_ 90 TrnGear_No_Cnt 1;
BA_ "MetaData" SG_ 90 TrnGear_No_Cnt 1;
BA_ "U_P702_MY2021_Rx" SG_ 90 TrnGear_No_Cnt 1;
BA_ "U_T6_MCA_MY2020_Rx" SG_ 90 TrnGear_No_Cnt 1;
BA_ "WakeupSignal" SG_ 90 TrnGear_D_RqDrv 1;
BA_ "ContentDependant" SG_ 90 TrnGear_D_RqDrv 1;
BA_ "U_P702_MY2021_Rx" SG_ 90 TrnGear_D_RqDrv 1;
BA_ "U_T6_MCA_MY2020_Rx" SG_ 90 TrnGear_D_RqDrv 1;
BA_ "ContentDependant" SG_ 90 BrkSwtchPos_B_ActlGsm 1;
BA_ "U_P702_MY2021_Rx" SG_ 90 BrkSwtchPos_B_ActlGsm 1;
BA_ "U_T6_MCA_MY2020_Rx" SG_ 90 BrkSwtchPos_B_ActlGsm 1;
BA_ "U_P702_MY2021_Rx" SG_ 138 SteWhlRelCalib_T_Actl 1;
BA_ "ContentDependant" SG_ 138 SteWhlRelCalib_An_Sns 1;
BA_ "U_P702_MY2021_Rx" SG_ 138 SteWhlRelCalib_An_Sns 1;
BA_ "U_CX727_MY2021_Rx" SG_ 138 SteWhlRelCalib_An_Sns 1;
BA_ "U_P702_MY2021_Rx" SG_ 1093 TrlrBrkActCnnct_B_Actl 1;
BA_ "U_CX727_MY2021_Rx" SG_ 1093 TrlrBrkActCnnct_B_Actl 1;
BA_ "U_T6_MCA_MY2020_Rx" SG_ 1093 TrlrBrkActCnnct_B_Actl 1;
BA_ "ContentDependant" SG_ 1093 StopLamp_B_RqTrlrBrk 1;
BA_ "U_P702_MY2021_Rx" SG_ 792 FuelRange_L_Dsply 1;
BA_ "U_T6_MCA_MY2020_Rx" SG_ 792 FuelRange_L_Dsply 1;
BA_ "ContentDependant" SG_ 792 ElTrip_L_Dsply 1;
BA_ "ContentDependant" SG_ 792 ElLongTerm_L_Dsply 1;
BA_ "U_T6_MCA_MY2020_Rx" SG_ 765 EdmSailMde_B_RqDrv 1;
BA_ "WakeupSignal" SG_ 765 DrvInputRequired_B_Rq 1;
BA_ "CrossOver_InfoCAN" SG_ 765 AwdRnge_D_ActlIpc 1;
BA_ "GenSigStartValueInteger" SG_ 765 AwdRnge_D_ActlIpc 7;
BA_ "GenSigStartValue" SG_ 765 AwdRnge_D_ActlIpc 7;
BA_ "U_P702_MY2021_Rx" SG_ 765 AwdRnge_D_ActlIpc 1;
BA_ "U_T6_MCA_MY2020_Rx" SG_ 765 AwdRnge_D_ActlIpc 1;
BA_ "GenSigStartValueInteger" SG_ 765 BalrSwtch_D_Stat 1;
BA_ "GenSigStartValue" SG_ 765 BalrSwtch_D_Stat 1;
BA_ "GenSigStartValueInteger" SG_ 765 WaitToStartLamp_D_Falt 1;
BA_ "GenSigStartValue" SG_ 765 WaitToStartLamp_D_Falt 1;
BA_ "U_P702_MY2021_Rx" SG_ 765 WaitToStartLamp_D_Falt 1;
BA_ "U_T6_MCA_MY2020_Rx" SG_ 765 WaitToStartLamp_D_Falt 1;
BA_ "GenSigStartValueInteger" SG_ 765 EsaOn_B_Rq 1;
BA_ "GenSigStartValue" SG_ 765 EsaOn_B_Rq 1;
BA_ "U_P702_MY2021_Rx" SG_ 765 EsaOn_B_Rq 1;
BA_ "GenSigStartValueInteger" SG_ 765 Btt_L_Actl 126;
BA_ "GenSigStartValue" SG_ 765 Btt_L_Actl 126;
BA_ "U_P702_MY2021_Rx" SG_ 765 SelDrvMdeTxtReset_B_Rq 1;
BA_ "U_P702_MY2021_Rx" SG_ 765 SelDrvMdeDsply_B_Avail 1;
BA_ "CrossOver_InfoCAN" SG_ 765 Mc_VehUnitTempUsrSel_St 1;
BA_ "GenSigSendType" SG_ 934 CtaAlrtLeft2_D_Stat 3;
BA_ "GenSigSendType" SG_ 934 CtaBrkLeftMsgTxt_B_Rq 3;
BA_ "GenSigSendType" SG_ 934 CtaLeftBrkDecel_B_Rq 3;
BA_ "U_CX727_MY2021_Rx" SG_ 934 CtaLeftBrkDecel_B_Rq 1;
BA_ "U_P702_MY2021_Rx" SG_ 934 CtaLeftBrkDecel_B_Rq 1;
BA_ "GenSigSendType" SG_ 934 CtaLeftBrkEnbl_B_Rq 3;
BA_ "U_CX727_MY2021_Rx" SG_ 934 CtaLeftBrkEnbl_B_Rq 1;
BA_ "U_P702_MY2021_Rx" SG_ 934 CtaLeftBrkEnbl_B_Rq 1;
BA_ "CrossOver_InfoCAN" SG_ 934 Side_Detect_L_Illum 1;
BA_ "GenSigStartValueInteger" SG_ 934 Side_Detect_L_Illum 100;
BA_ "GenSigStartValue" SG_ 934 Side_Detect_L_Illum 100;
BA_ "GenSigSendType" SG_ 934 BttLeft_D_Stat 3;
BA_ "GenSigSendType" SG_ 934 BttLeft_D_RqDrv 3;
BA_ "CrossOver_InfoCAN" SG_ 934 CtaSnsLeft_D_Stat 1;
BA_ "GenSigSendType" SG_ 934 CtaSnsLeft_D_Stat 3;
BA_ "CrossOver_InfoCAN" SG_ 934 SodDetctLeft_D_Stat 1;
BA_ "GenSigSendType" SG_ 934 SodDetctLeft_D_Stat 3;
BA_ "CrossOver_InfoCAN" SG_ 934 CtaLeft_D_Stat 1;
BA_ "GenSigSendType" SG_ 934 CtaLeft_D_Stat 3;
BA_ "CrossOver_InfoCAN" SG_ 934 CtaAlrtLeft_D_Stat 1;
BA_ "GenSigSendType" SG_ 934 CtaAlrtLeft_D_Stat 3;
BA_ "CrossOver_InfoCAN" SG_ 934 SodLeft_D_Stat 1;
BA_ "GenSigStartValueInteger" SG_ 934 SodLeft_D_Stat 2;
BA_ "GenSigStartValue" SG_ 934 SodLeft_D_Stat 2;
BA_ "GenSigSendType" SG_ 934 SodLeft_D_Stat 3;
BA_ "CrossOver_InfoCAN" SG_ 934 SodSnsLeft_D_Stat 1;
BA_ "GenSigSendType" SG_ 934 SodSnsLeft_D_Stat 3;
BA_ "CrossOver_InfoCAN" SG_ 934 SodAlrtLeft_D_Stat 1;
BA_ "GenSigSendType" SG_ 934 SodAlrtLeft_D_Stat 3;
BA_ "CrossOver_InfoCAN" SG_ 934 SodWarnLeft_Prd_Rq 1;
BA_ "GenSigStartValueInteger" SG_ 934 SodWarnLeft_Prd_Rq 14;
BA_ "GenSigStartValue" SG_ 934 SodWarnLeft_Prd_Rq 14;
BA_ "CrossOver_InfoCAN" SG_ 1072 DrvSlipCtlMde_D_Rq 1;
BA_ "U_P702_MY2021_Rx" SG_ 1072 DrvSlipCtlMde_D_Rq 1;
BA_ "U_P702_MY2021_Rx" SG_ 1072 EngIdlShutDown_B_RqDrv 1;
BA_ "U_T6_MCA_MY2020_Rx" SG_ 1072 EngIdlShutDown_B_RqDrv 1;
BA_ "CrossOver_InfoCAN" SG_ 1072 HsaMde_D_Rq 1;
BA_ "GenSigStartValueInteger" SG_ 1072 HsaMde_D_Rq 1;
BA_ "GenSigStartValue" SG_ 1072 HsaMde_D_Rq 1;
BA_ "CrossOver_InfoCAN" SG_ 1072 NtrlTowMdeEnbl_B_RqDrv 1;
BA_ "U_P702_MY2021_Rx" SG_ 1072 NtrlTowMdeEnbl_B_RqDrv 1;
BA_ "U_T6_MCA_MY2020_Rx" SG_ 1072 NtrlTowMdeEnbl_B_RqDrv 1;
BA_ "CrossOver_InfoCAN" SG_ 1072 BulbChkActv_B_Stat 1;
BA_ "CrossOver_InfoCAN" SG_ 1072 ParkDetect_Stat 1;
BA_ "CrossOver_InfoCAN" SG_ 1072 ReducedGuard_D_Rq 1;
BA_ "U_P702_MY2021_Rx" SG_ 1072 TRLR_SWAY_CONFIG_CMD 1;
BA_ "WakeupSignal" SG_ 1072 Power_Liftgate_Mode_Cmd 1;
BA_ "CrossOver_InfoCAN" SG_ 1072 Power_Liftgate_Mode_Cmd 1;
BA_ "CrossOver_InfoCAN" SG_ 1072 AccEnbl_B_RqDrv 1;
BA_ "GenSigStartValueInteger" SG_ 1072 AccEnbl_B_RqDrv 1;
BA_ "GenSigStartValue" SG_ 1072 AccEnbl_B_RqDrv 1;
BA_ "CrossOver_InfoCAN" SG_ 1072 OdometerMasterValue 1;
BA_ "U_P702_MY2021_Rx" SG_ 1072 OdometerMasterValue 1;
BA_ "U_T6_MCA_MY2020_Rx" SG_ 1072 OdometerMasterValue 1;
BA_ "U_CX727_MY2021_Rx" SG_ 1072 OdometerMasterValue 1;
BA_ "CrossOver_InfoCAN" SG_ 1072 EngOilLife_B_RqReset 1;
BA_ "U_P702_MY2021_Rx" SG_ 1072 EngOilLife_B_RqReset 1;
BA_ "U_T6_MCA_MY2020_Rx" SG_ 1072 EngOilLife_B_RqReset 1;
BA_ "WakeupSignal" SG_ 1072 ePRNDL_MODE 1;
BA_ "CrossOver_InfoCAN" SG_ 1072 ePRNDL_MODE 1;
BA_ "U_P702_MY2021_Rx" SG_ 1072 ePRNDL_MODE 1;
BA_ "U_T6_MCA_MY2020_Rx" SG_ 1072 ePRNDL_MODE 1;
BA_ "CrossOver_InfoCAN" SG_ 1072 DrvSlipCtlMde_B_Rq2 1;
BA_ "U_P702_MY2021_Rx" SG_ 1072 DrvSlipCtlMde_B_Rq2 1;
BA_ "CrossOver_InfoCAN" SG_ 1072 MetricActv_B_Actl 1;
BA_ "U_P702_MY2021_Rx" SG_ 1072 MetricActv_B_Actl 1;
BA_ "U_T6_MCA_MY2020_Rx" SG_ 1072 MetricActv_B_Actl 1;
BA_ "CrossOver_InfoCAN" SG_ 1072 KeyTypeChngMykey_D_Rq 1;
BA_ "CrossOver_InfoCAN" SG_ 1072 ManRgen_D_Rq 1;
BA_ "U_P702_MY2021_Rx" SG_ 1072 ManRgen_D_Rq 1;
BA_ "U_T6_MCA_MY2020_Rx" SG_ 1072 ManRgen_D_Rq 1;
BA_ "GenSigStartValueInteger" SG_ 145 VehYawWActl_D_Qf 1;
BA_ "MetaData" SG_ 145 VehYawWActl_D_Qf 1;
BA_ "GenSigStartValue" SG_ 145 VehYawWActl_D_Qf 1;
BA_ "U_CX727_MY2021_Rx" SG_ 145 VehYawWActl_D_Qf 1;
BA_ "U_P702_MY2021_Rx" SG_ 145 VehYawWActl_D_Qf 1;
BA_ "GenSigStartValueInteger" SG_ 145 VehRolWActl_D_Qf 1;
BA_ "MetaData" SG_ 145 VehRolWActl_D_Qf 1;
BA_ "GenSigStartValue" SG_ 145 VehRolWActl_D_Qf 1;
BA_ "U_CX727_MY2021_Rx" SG_ 145 VehRolWActl_D_Qf 1;
BA_ "U_P702_MY2021_Rx" SG_ 145 VehRolWActl_D_Qf 1;
BA_ "MetaData" SG_ 145 VehRollYawW_No_Cs 1;
BA_ "U_CX727_MY2021_Rx" SG_ 145 VehRollYawW_No_Cs 1;
BA_ "U_P702_MY2021_Rx" SG_ 145 VehRollYawW_No_Cs 1;
BA_ "MetaData" SG_ 145 VehRollYaw_No_Cnt 1;
BA_ "U_CX727_MY2021_Rx" SG_ 145 VehRollYaw_No_Cnt 1;
BA_ "U_P702_MY2021_Rx" SG_ 145 VehRollYaw_No_Cnt 1;
BA_ "GenSigStartValueInteger" SG_ 145 VehYaw_W_Actl 65534;
BA_ "GenSigStartValue" SG_ 145 VehYaw_W_Actl 65534;
BA_ "U_CX727_MY2021_Rx" SG_ 145 VehYaw_W_Actl 1;
BA_ "U_P702_MY2021_Rx" SG_ 145 VehYaw_W_Actl 1;
BA_ "GenSigStartValueInteger" SG_ 145 VehRol_W_Actl 65534;
BA_ "GenSigStartValue" SG_ 145 VehRol_W_Actl 65534;
BA_ "U_CX727_MY2021_Rx" SG_ 145 VehRol_W_Actl 1;
BA_ "U_P702_MY2021_Rx" SG_ 145 VehRol_W_Actl 1;
BA_ "U_P702_MY2021_Rx" SG_ 931 PtWakeReas_D_Stat 1;
BA_ "U_P702_MY2021_Rx" SG_ 931 VehOnSrc_D_Stat 1;
BA_ "U_T6_MCA_MY2020_Rx" SG_ 931 VehOnSrc_D_Stat 1;
BA_ "U_P702_MY2021_Rx" SG_ 931 StrtrMtrCtlDStat_No_Cs 1;
BA_ "U_T6_MCA_MY2020_Rx" SG_ 931 StrtrMtrCtlDStat_No_Cs 1;
BA_ "U_P702_MY2021_Rx" SG_ 931 EngStrtActv_B_Stat 1;
BA_ "U_T6_MCA_MY2020_Rx" SG_ 931 EngStrtActv_B_Stat 1;
BA_ "U_P702_MY2021_Rx" SG_ 931 EngStrt_B_Rq 1;
BA_ "U_T6_MCA_MY2020_Rx" SG_ 931 EngStrt_B_Rq 1;
BA_ "U_P702_MY2021_Rx" SG_ 931 DrvInCtl_B_Stat 1;
BA_ "U_T6_MCA_MY2020_Rx" SG_ 931 DrvInCtl_B_Stat 1;
BA_ "U_P702_MY2021_Rx" SG_ 931 AdvStrt_D_Stat 1;
BA_ "U_T6_MCA_MY2020_Rx" SG_ 931 AdvStrt_D_Stat 1;
BA_ "ContentDependant" SG_ 931 CrnkInhbt_No_Cs 1;
BA_ "MetaData" SG_ 931 CrnkInhbt_No_Cs 1;
BA_ "U_P702_MY2021_Rx" SG_ 931 CrnkInhbt_No_Cs 1;
BA_ "U_T6_MCA_MY2020_Rx" SG_ 931 CrnkInhbt_No_Cs 1;
BA_ "ContentDependant" SG_ 931 CrnkInhbt_No_Cnt 1;
BA_ "MetaData" SG_ 931 CrnkInhbt_No_Cnt 1;
BA_ "U_P702_MY2021_Rx" SG_ 931 CrnkInhbt_No_Cnt 1;
BA_ "U_T6_MCA_MY2020_Rx" SG_ 931 CrnkInhbt_No_Cnt 1;
BA_ "GenSigStartValueInteger" SG_ 931 CrnkInhbt_B_Stat 1;
BA_ "GenSigStartValue" SG_ 931 CrnkInhbt_B_Stat 1;
BA_ "U_P702_MY2021_Rx" SG_ 931 CrnkInhbt_B_Stat 1;
BA_ "U_T6_MCA_MY2020_Rx" SG_ 931 CrnkInhbt_B_Stat 1;
BA_ "U_P702_MY2021_Rx" SG_ 931 IgnPreOffActv_B_Stat 1;
BA_ "U_T6_MCA_MY2020_Rx" SG_ 931 IgnPreOffActv_B_Stat 1;
BA_ "WakeupSignal" SG_ 947 DimmingLvlEvnt_No_Actl 1;
BA_ "U_P702_MY2021_Rx" SG_ 947 DrStatDrvErrCnt_B_Stat 1;
BA_ "U_T6_MCA_MY2020_Rx" SG_ 947 DrStatDrvErrCnt_B_Stat 1;
BA_ "WakeupSignal" SG_ 947 TurnLghtRight_D_Rq 1;
BA_ "CrossOver_InfoCAN" SG_ 947 TurnLghtRight_D_Rq 1;
BA_ "U_P702_MY2021_Rx" SG_ 947 TurnLghtRight_D_Rq 1;
BA_ "CrossOver_InfoCAN" SG_ 947 TurnLghtRightOn_B_Stat 1;
BA_ "CrossOver_InfoCAN" SG_ 947 TurnLghtLeftOn_B_Stat 1;
BA_ "CrossOver_InfoCAN" SG_ 947 FogLghtRearOn_B_Stat 1;
BA_ "U_P702_MY2021_Rx" SG_ 947 FogLghtRearOn_B_Stat 1;
BA_ "WakeupSignal" SG_ 947 Backlit_LED_Status 1;
BA_ "CrossOver_InfoCAN" SG_ 947 Backlit_LED_Status 1;
BA_ "WakeupSignal" SG_ 947 TurnLghtLeft_D_Rq 1;
BA_ "CrossOver_InfoCAN" SG_ 947 TurnLghtLeft_D_Rq 1;
BA_ "U_P702_MY2021_Rx" SG_ 947 TurnLghtLeft_D_Rq 1;
BA_ "CrossOver_InfoCAN" SG_ 947 FogLghtFrontOn_B_Stat 1;
BA_ "U_P702_MY2021_Rx" SG_ 947 FogLghtFrontOn_B_Stat 1;
BA_ "CrossOver_InfoCAN" SG_ 947 IgnKeyType_D_Actl 1;
BA_ "GenSigStartValueInteger" SG_ 947 IgnKeyType_D_Actl 14;
BA_ "GenSigStartValue" SG_ 947 IgnKeyType_D_Actl 14;
BA_ "U_P702_MY2021_Rx" SG_ 947 IgnKeyType_D_Actl 1;
BA_ "U_T6_MCA_MY2020_Rx" SG_ 947 IgnKeyType_D_Actl 1;
BA_ "U_CX727_MY2021_Rx" SG_ 947 IgnKeyType_D_Actl 1;
BA_ "WakeupSignal" SG_ 947 Parklamp_Status 1;
BA_ "CrossOver_InfoCAN" SG_ 947 Parklamp_Status 1;
BA_ "GenSigStartValueInteger" SG_ 947 Parklamp_Status 1;
BA_ "GenSigStartValue" SG_ 947 Parklamp_Status 1;
BA_ "WakeupSignal" SG_ 947 Litval 1;
BA_ "CrossOver_InfoCAN" SG_ 947 Litval 1;
BA_ "U_P702_MY2021_Rx" SG_ 947 Litval 1;
BA_ "WakeupSignal" SG_ 947 Key_In_Ignition_Stat 1;
BA_ "CrossOver_InfoCAN" SG_ 947 Key_In_Ignition_Stat 1;
BA_ "U_CX727_MY2021_Rx" SG_ 947 Key_In_Ignition_Stat 1;
BA_ "U_P702_MY2021_Rx" SG_ 947 Key_In_Ignition_Stat 1;
BA_ "WakeupSignal" SG_ 947 Ignition_Status 1;
BA_ "CrossOver_InfoCAN" SG_ 947 Ignition_Status 1;
BA_ "U_P702_MY2021_Rx" SG_ 947 Ignition_Status 1;
BA_ "U_T6_MCA_MY2020_Rx" SG_ 947 Ignition_Status 1;
BA_ "U_CX727_MY2021_Rx" SG_ 947 Ignition_Status 1;
BA_ "WakeupSignal" SG_ 947 Dimming_Lvl 1;
BA_ "CrossOver_InfoCAN" SG_ 947 Dimming_Lvl 1;
BA_ "GenSigStartValueInteger" SG_ 947 Dimming_Lvl 12;
BA_ "GenSigStartValue" SG_ 947 Dimming_Lvl 12;
BA_ "WakeupSignal" SG_ 947 Day_Night_Status 1;
BA_ "CrossOver_InfoCAN" SG_ 947 Day_Night_Status 1;
BA_ "U_P702_MY2021_Rx" SG_ 947 Day_Night_Status 1;
BA_ "U_T6_MCA_MY2020_Rx" SG_ 947 Day_Night_Status 1;
BA_ "WakeupSignal" SG_ 947 Remote_Start_Status 1;
BA_ "CrossOver_InfoCAN" SG_ 947 Remote_Start_Status 1;
BA_ "WakeupSignal" SG_ 947 DrStatTgate_B_Actl 1;
BA_ "CrossOver_InfoCAN" SG_ 947 DrStatTgate_B_Actl 1;
BA_ "WakeupSignal" SG_ 947 DrStatRr_B_Actl 1;
BA_ "CrossOver_InfoCAN" SG_ 947 DrStatRr_B_Actl 1;
BA_ "U_P702_MY2021_Rx" SG_ 947 DrStatRr_B_Actl 1;
BA_ "WakeupSignal" SG_ 947 DrStatRl_B_Actl 1;
BA_ "CrossOver_InfoCAN" SG_ 947 DrStatRl_B_Actl 1;
BA_ "U_P702_MY2021_Rx" SG_ 947 DrStatRl_B_Actl 1;
BA_ "WakeupSignal" SG_ 947 DrStatPsngr_B_Actl 1;
BA_ "CrossOver_InfoCAN" SG_ 947 DrStatPsngr_B_Actl 1;
BA_ "U_P702_MY2021_Rx" SG_ 947 DrStatPsngr_B_Actl 1;
BA_ "WakeupSignal" SG_ 947 DrStatInnrTgate_B_Actl 1;
BA_ "CrossOver_InfoCAN" SG_ 947 DrStatInnrTgate_B_Actl 1;
BA_ "WakeupSignal" SG_ 947 DrStatHood_B_Actl 1;
BA_ "CrossOver_InfoCAN" SG_ 947 DrStatHood_B_Actl 1;
BA_ "WakeupSignal" SG_ 947 DrStatDrv_B_Actl 1;
BA_ "CrossOver_InfoCAN" SG_ 947 DrStatDrv_B_Actl 1;
BA_ "U_P702_MY2021_Rx" SG_ 947 DrStatDrv_B_Actl 1;
BA_ "U_T6_MCA_MY2020_Rx" SG_ 947 DrStatDrv_B_Actl 1;
BA_ "U_CX727_MY2021_Rx" SG_ 947 DrStatDrv_B_Actl 1;
BA_ "WakeupSignal" SG_ 947 PrkBrkActv_B_Actl 1;
BA_ "CrossOver_InfoCAN" SG_ 947 PrkBrkActv_B_Actl 1;
BA_ "ContentDependant" SG_ 947 PrkBrkActv_B_Actl 1;
BA_ "U_P702_MY2021_Rx" SG_ 947 PrkBrkActv_B_Actl 1;
BA_ "U_T6_MCA_MY2020_Rx" SG_ 947 PrkBrkActv_B_Actl 1;
BA_ "U_CX727_MY2021_Rx" SG_ 947 PrkBrkActv_B_Actl 1;
BA_ "CrossOver_InfoCAN" SG_ 947 LifeCycMde_D_Actl 1;
BA_ "U_P702_MY2021_Rx" SG_ 947 LifeCycMde_D_Actl 1;
BA_ "U_T6_MCA_MY2020_Rx" SG_ 947 LifeCycMde_D_Actl 1;
BA_ "U_CX727_MY2021_Rx" SG_ 947 LifeCycMde_D_Actl 1;
BA_ "WakeupSignal" SG_ 947 Delay_Accy 1;
BA_ "CrossOver_InfoCAN" SG_ 947 Delay_Accy 1;
BA_ "WakeupSignal" SG_ 947 CrashEvnt_D_Stat 1;
BA_ "CrossOver_InfoCAN" SG_ 947 CrashEvnt_D_Stat 1;
BA_ "GenSigStartValueInteger" SG_ 947 CrashEvnt_D_Stat 3;
BA_ "GenSigStartValue" SG_ 947 CrashEvnt_D_Stat 3;
BA_ "CrossOver_InfoCAN" SG_ 947 FuelPmpInhbt_B_Stat 1;
BA_ "CrossOver_InfoCAN" SG_ 947 BodySrvcRqd_B_Rq 1;
BA_ "MetaData" SG_ 394 HaDsply_No_Cs 1;
BA_ "ContentDependant" SG_ 394 HaDsply_No_Cs 1;
BA_ "GenSigSendType" SG_ 394 HaDsply_No_Cs 3;
BA_ "MetaData" SG_ 394 HaDsply_No_Cnt 1;
BA_ "ContentDependant" SG_ 394 HaDsply_No_Cnt 1;
BA_ "GenSigSendType" SG_ 394 HaDsply_No_Cnt 3;
BA_ "GenSigSendType" SG_ 394 AccStopStat_D_Dsply 3;
BA_ "CrossOver_InfoCAN" SG_ 394 AccTrgDist2_D_Dsply 1;
BA_ "GenSigSendType" SG_ 394 AccTrgDist2_D_Dsply 3;
BA_ "CrossOver_InfoCAN" SG_ 394 AccStopRes_B_Dsply 1;
BA_ "GenSigSendType" SG_ 394 AccStopRes_B_Dsply 3;
BA_ "GenSigSendType" SG_ 394 TjaWarn_D_Rq 3;
BA_ "GenSigSendType" SG_ 394 Tja_D_Stat 3;
BA_ "GenSigSendType" SG_ 394 TjaMsgTxt_D_Dsply 3;
BA_ "GenSigSendType" SG_ 394 IaccLamp_D_Rq 3;
BA_ "GenSigSendType" SG_ 394 AccMsgTxt_D2_Rq 3;
BA_ "CrossOver_InfoCAN" SG_ 394 FcwDeny_B_Dsply 1;
BA_ "GenSigSendType" SG_ 394 FcwDeny_B_Dsply 3;
BA_ "CrossOver_InfoCAN" SG_ 394 FcwMemStat_B_Actl 1;
BA_ "GenSigSendType" SG_ 394 FcwMemStat_B_Actl 3;
BA_ "ECGUsedRxSignal" SG_ 394 FcwMemStat_B_Actl 1;
BA_ "CrossOver_InfoCAN" SG_ 394 AccTGap_B_Dsply 1;
BA_ "GenSigSendType" SG_ 394 AccTGap_B_Dsply 3;
BA_ "CrossOver_InfoCAN" SG_ 394 CadsAlignIncplt_B_Actl 1;
BA_ "GenSigSendType" SG_ 394 CadsAlignIncplt_B_Actl 3;
BA_ "CrossOver_InfoCAN" SG_ 394 AccFllwMde_B_Dsply 1;
BA_ "GenSigSendType" SG_ 394 AccFllwMde_B_Dsply 3;
BA_ "CrossOver_InfoCAN" SG_ 394 CadsRadrBlck_B_Actl 1;
BA_ "GenSigSendType" SG_ 394 CadsRadrBlck_B_Actl 3;
BA_ "CrossOver_InfoCAN" SG_ 394 CmbbPostEvnt_B_Dsply 1;
BA_ "GenSigSendType" SG_ 394 CmbbPostEvnt_B_Dsply 3;
BA_ "CrossOver_InfoCAN" SG_ 394 AccStopMde_B_Dsply 1;
BA_ "GenSigSendType" SG_ 394 AccStopMde_B_Dsply 3;
BA_ "CrossOver_InfoCAN" SG_ 394 FcwMemSens_D_Actl 1;
BA_ "GenSigSendType" SG_ 394 FcwMemSens_D_Actl 3;
BA_ "ECGUsedRxSignal" SG_ 394 FcwMemSens_D_Actl 1;
BA_ "CrossOver_InfoCAN" SG_ 394 FcwMsgTxt_D_Rq 1;
BA_ "GenSigSendType" SG_ 394 FcwMsgTxt_D_Rq 3;
BA_ "CrossOver_InfoCAN" SG_ 394 AccWarn_D_Dsply 1;
BA_ "GenSigSendType" SG_ 394 AccWarn_D_Dsply 3;
BA_ "CrossOver_InfoCAN" SG_ 394 FcwVisblWarn_B_Rq 1;
BA_ "GenSigSendType" SG_ 394 FcwVisblWarn_B_Rq 3;
BA_ "CrossOver_InfoCAN" SG_ 394 FcwAudioWarn_B_Rq 1;
BA_ "GenSigSendType" SG_ 394 FcwAudioWarn_B_Rq 3;
BA_ "ECGUsedRxSignal" SG_ 394 FcwAudioWarn_B_Rq 1;
BA_ "CrossOver_InfoCAN" SG_ 394 AccTGap_D_Dsply 1;
BA_ "GenSigStartValueInteger" SG_ 394 AccTGap_D_Dsply 3;
BA_ "GenSigStartValue" SG_ 394 AccTGap_D_Dsply 3;
BA_ "GenSigSendType" SG_ 394 AccTGap_D_Dsply 3;
BA_ "CrossOver_InfoCAN" SG_ 394 AccMemEnbl_B_RqDrv 1;
BA_ "GenSigStartValueInteger" SG_ 394 AccMemEnbl_B_RqDrv 1;
BA_ "GenSigStartValue" SG_ 394 AccMemEnbl_B_RqDrv 1;
BA_ "GenSigSendType" SG_ 394 AccMemEnbl_B_RqDrv 3;
BA_ "CrossOver_InfoCAN" SG_ 394 FdaMem_B_Stat 1;
BA_ "GenSigSendType" SG_ 394 FdaMem_B_Stat 3;
BA_ "MetaData" SG_ 391 CmbbBrkDecel_No_Cnt 1;
BA_ "U_CX727_MY2021_Rx" SG_ 391 CmbbBrkDecel_No_Cnt 1;
BA_ "U_P702_MY2021_Rx" SG_ 391 CmbbBrkDecel_No_Cnt 1;
BA_ "MetaData" SG_ 391 CmbbBrkDecel_No_Cs 1;
BA_ "U_CX727_MY2021_Rx" SG_ 391 CmbbBrkDecel_No_Cs 1;
BA_ "U_P702_MY2021_Rx" SG_ 391 CmbbBrkDecel_No_Cs 1;
BA_ "GenSigStartValueInteger" SG_ 391 CmbbBrkDecel_A_Rq 5129;
BA_ "U_CX727_MY2021_Rx" SG_ 391 CmbbBrkDecel_A_Rq 1;
BA_ "U_P702_MY2021_Rx" SG_ 391 CmbbBrkDecel_A_Rq 1;
BA_ "U_CX727_MY2021_Rx" SG_ 391 CmbbBrkPrchg_D_Rq 1;
BA_ "U_P702_MY2021_Rx" SG_ 391 CmbbBrkPrchg_D_Rq 1;
BA_ "ECGUsedRxSignal" SG_ 391 CmbbBrkPrchg_D_Rq 1;
BA_ "U_CX727_MY2021_Rx" SG_ 391 CmbbBrkDecel_B_Rq 1;
BA_ "U_P702_MY2021_Rx" SG_ 391 CmbbBrkDecel_B_Rq 1;
BA_ "ECGUsedRxSignal" SG_ 391 CmbbBrkDecel_B_Rq 1;
BA_ "U_CX727_MY2021_Rx" SG_ 391 CmbbBaSens_D_Rq 1;
BA_ "U_P702_MY2021_Rx" SG_ 391 CmbbBaSens_D_Rq 1;
BA_ "GenSigStartValueInteger" SG_ 390 AccBrkTot_A_Rq 5129;
BA_ "U_CX727_MY2021_Rx" SG_ 390 AccBrkTot_A_Rq 1;
BA_ "U_P702_MY2021_Rx" SG_ 390 AccBrkTot_A_Rq 1;
BA_ "U_P702_MY2021_Rx" SG_ 390 AccPrpl_A_Pred 1;
BA_ "U_T6_MCA_MY2020_Rx" SG_ 390 AccPrpl_A_Pred 1;
BA_ "U_P702_MY2021_Rx" SG_ 390 AccVeh_V_Trg 1;
BA_ "U_T6_MCA_MY2020_Rx" SG_ 390 AccVeh_V_Trg 1;
BA_ "U_CX727_MY2021_Rx" SG_ 390 AccBrkPrkEl_B_Rq 1;
BA_ "U_P702_MY2021_Rx" SG_ 390 AccBrkPrkEl_B_Rq 1;
BA_ "U_CX727_MY2021_Rx" SG_ 390 CmbbDeny_B_Actl 1;
BA_ "U_P702_MY2021_Rx" SG_ 390 CmbbDeny_B_Actl 1;
BA_ "U_P702_MY2021_Rx" SG_ 390 CmbbEngTqMn_B_Rq 1;
BA_ "U_T6_MCA_MY2020_Rx" SG_ 390 CmbbEngTqMn_B_Rq 1;
BA_ "U_P702_MY2021_Rx" SG_ 390 AccPrpl_A_Rq 1;
BA_ "U_T6_MCA_MY2020_Rx" SG_ 390 AccPrpl_A_Rq 1;
BA_ "U_P702_MY2021_Rx" SG_ 390 AccDeny_B_Rq 1;
BA_ "U_T6_MCA_MY2020_Rx" SG_ 390 AccDeny_B_Rq 1;
BA_ "WakeupSignal" SG_ 390 AccResumEnbl_B_Rq 1;
BA_ "U_P702_MY2021_Rx" SG_ 390 AccResumEnbl_B_Rq 1;
BA_ "U_T6_MCA_MY2020_Rx" SG_ 390 AccResumEnbl_B_Rq 1;
BA_ "U_P702_MY2021_Rx" SG_ 390 AccCancl_B_Rq 1;
BA_ "U_T6_MCA_MY2020_Rx" SG_ 390 AccCancl_B_Rq 1;
BA_ "U_CX727_MY2021_Rx" SG_ 390 AccBrkPrchg_B_Rq 1;
BA_ "U_P702_MY2021_Rx" SG_ 390 AccBrkPrchg_B_Rq 1;
BA_ "U_CX727_MY2021_Rx" SG_ 390 AccBrkDecel_B_Rq 1;
BA_ "U_P702_MY2021_Rx" SG_ 390 AccBrkDecel_B_Rq 1;
BA_ "U_CX727_MY2021_Rx" SG_ 390 AccStopStat_B_Rq 1;
BA_ "U_P702_MY2021_Rx" SG_ 390 AccStopStat_B_Rq 1;
BA_ "U_T6_MCA_MY2020_Rx" SG_ 390 AccStopStat_B_Rq 1;
BA_ "GenSigSendType" SG_ 942 PrkAidRdiusRight_L_Dsply 3;
BA_ "GenSigSendType" SG_ 942 PrkAidRdiusLeft_L_Dsply 3;
BA_ "GenSigSendType" SG_ 942 PrkAidDrvDir_D_Stat 3;
BA_ "GenSigSendType" SG_ 942 PrkAidAcsyRear_D_Stat 3;
BA_ "GenSigSendType" SG_ 942 PrkAidAcsyFront_D_Stat 3;
